VERSION "created by canmatrix"

NS_ :

BS_:

BU_: IPD

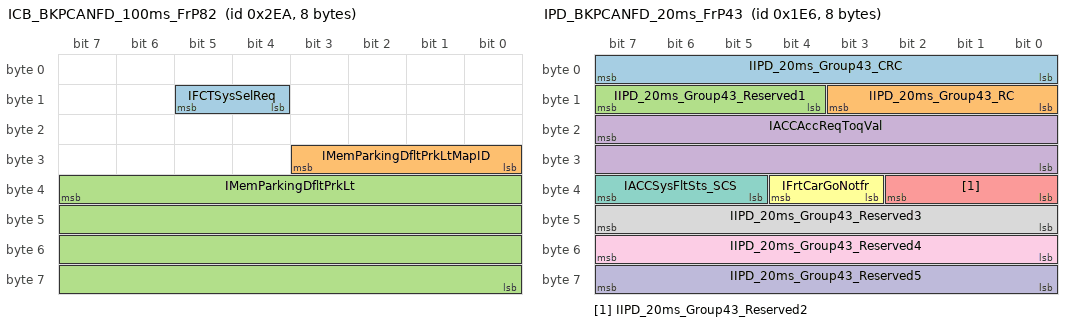
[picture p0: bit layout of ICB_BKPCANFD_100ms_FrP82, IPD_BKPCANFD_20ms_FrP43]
BO_ 746 ICB_BKPCANFD_100ms_FrP82: 8 Vector__XXX
 SG_ IFCTSysSelReq : 13|2@0+ (1,0) [0|3] "null" IPD
 SG_ IMemParkingDfltPrkLtMapID : 27|4@0+ (1,0) [0|15] "null" IPD
 SG_ IMemParkingDfltPrkLt : 39|32@0+ (1,0) [0|4294967295] "null" IPD

BO_ 368 ICB_BKPCANFD_30ms_FrP158: 16 Vector__XXX
 SG_ IICBVC_30ms_Group158_CRC : 7|8@0+ (1,0) [0|255] "null" IPD
 SG_ IICBVC_30ms_Group158_RC : 11|4@0+ (1,0) [0|15] "null" IPD
 SG_ ICCSpdDecAndIncVcCmd : 13|2@0+ (1,0) [0|3] "null" IPD
 SG_ ICCDisDecAndIncVcCmd : 15|2@0+ (1,0) [0|3] "null" IPD
 SG_ IICBVC_30ms_Group158_Reserved1 : 19|4@0+ (1,0) [0|15] "null" IPD
 SG_ ICCSwStsSetSwA : 20|1@0+ (1,0) [0|1] "null" IPD
 SG_ ICCSwStsCCASwA : 21|1@0+ (1,0) [0|1] "null" IPD
 SG_ ICCSpdVcCmdSwReq : 23|2@0+ (1,0) [0|3] "null" IPD
 SG_ ICCSpdVcCmd : 31|8@0+ (1,0) [0|255] "null" IPD
 SG_ IICBVC_30ms_Group158_Reserved2 : 39|8@0+ (1,0) [0|255] "null" IPD
 SG_ IICBVC_30ms_Group158_Reserved3 : 44|5@0+ (1,0) [0|31] "null" IPD
 SG_ ICCDisAdjtVcCmd : 47|3@0+ (1,0) [0|7] "null" IPD
 SG_ IICBVC_30ms_Group158_Reserved4 : 55|8@0+ (1,0) [0|255] "null" IPD
 SG_ IICBVC_30ms_Group158_Reserved5 : 63|8@0+ (1,0) [0|255] "null" IPD
 SG_ IICBVC_30ms_Group158_Reserved6 : 71|8@0+ (1,0) [0|255] "null" IPD
 SG_ IICBVC_30ms_Group158_Reserved7 : 79|8@0+ (1,0) [0|255] "null" IPD
 SG_ IICBVC_30ms_Group158_Reserved8 : 87|8@0+ (1,0) [0|255] "null" IPD
 SG_ IICBVC_30ms_Group158_Reserved9 : 95|8@0+ (1,0) [0|255] "null" IPD
 SG_ IICBVC_30ms_Group158_Reserved10 : 103|8@0+ (1,0) [0|255] "null" IPD
 SG_ IICBVC_30ms_Group158_Reserved11 : 111|8@0+ (1,0) [0|255] "null" IPD
 SG_ IICBVC_30ms_Group158_Reserved12 : 119|8@0+ (1,0) [0|255] "null" IPD
 SG_ IICBVC_30ms_Group158_Reserved13 : 127|8@0+ (1,0) [0|255] "null" IPD

BO_ 1389 ICB_CONNCANFD_Event_FrS67: 16 Vector__XXX
 SG_ IIdentityChlg : 71|64@0+ (1,0) [0|18446744073709551615] "null" IPD

BO_ 1111 ICB_ZONE_BDCAN_100ms_FrP00: 32 Vector__XXX
 SG_ IICCPCBTemp1 : 7|8@0+ (1,-40) [-40|215] "℃" Vector__XXX
 SG_ IICCPCBTemp2 : 15|8@0+ (1,-40) [-40|215] "℃" Vector__XXX
 SG_ IICCPCBTemp3 : 23|8@0+ (1,-40) [-40|215] "℃" Vector__XXX
 SG_ IICCPCBTemp4 : 31|8@0+ (1,-40) [-40|215] "℃" Vector__XXX
 SG_ IICCPCBTemp5 : 39|8@0+ (1,-40) [-40|215] "℃" Vector__XXX
 SG_ IICCThermalCoolingLvl : 47|4@0+ (1,0) [0|15] "null" Vector__XXX
 SG_ IFICMV2XEnEnbReq : 81|2@0+ (1,0) [0|3] "null" Vector__XXX
 SG_ IITMSTripBookReq : 84|3@0+ (1,0) [0|7] "null" Vector__XXX
 SG_ IElecPwrDistbnScene : 95|64@0+ (1,0) [0|18446744073709551615] "null" IPD
 SG_ IAltngChrgCrntReq : 159|8@0+ (1,0) [0|255] "null" Vector__XXX
 SG_ IDschrgTrgtSOCVal : 167|7@0+ (1,0) [0|127] "null" Vector__XXX

BO_ 1767 IPD_BKBCANFD_EvtInfo: 8 IPD
 SG_ IEvtPotclSigIPD : 7|64@0+ (1,0) [0|18446744073709551615] "null" Vector__XXX

BO_ 712 IPD_BKPCANFD_100ms_FrP124: 16 IPD
 SG_ INrwroadFwdBtnDsp : 15|2@0+ (1,0) [0|3] "null" Vector__XXX
 SG_ INrwroadFwdReDst : 23|11@0+ (0.1,0) [0|204.7] "m" Vector__XXX
 SG_ INrwroadFwdDsp : 28|5@0+ (1,0) [0|31] "null" Vector__XXX
 SG_ INrwroadFwdDstL : 39|8@0+ (1,0) [0|255] "cm" Vector__XXX
 SG_ INrwroadFwdDstR : 47|8@0+ (1,0) [0|255] "cm" Vector__XXX
 SG_ INrwroadFwdCndNotSt : 55|5@0+ (1,0) [0|31] "null" Vector__XXX
 SG_ IMemParkingCrsScrnReq : 88|1@0+ (1,0) [0|1] "null" Vector__XXX
 SG_ INrwroadFwdDstTostDsp : 111|4@0+ (1,0) [0|15] "null" Vector__XXX
 SG_ INrwroadFwdSwSts : 113|2@0+ (1,0) [0|3] "null" Vector__XXX
 SG_ INrwroadFwdDst360Req : 116|3@0+ (1,0) [0|7] "null" Vector__XXX
 SG_ INrwroadFwdDstBtnDsp : 119|3@0+ (1,0) [0|7] "null" Vector__XXX

BO_ 710 IPD_BKPCANFD_100ms_FrP127: 64 IPD
 SG_ IMemParkingPrkLt : 7|32@0+ (1,0) [0|4294967295] "null" Vector__XXX
 SG_ IMemParkingPrkLtMapID : 39|4@0+ (1,0) [0|15] "null" Vector__XXX
 SG_ ISpedRegulaModSwSts : 180|3@0+ (1,0) [0|7] "null" Vector__XXX
 SG_ IMemoryRouteSaveCancelRsp : 276|3@0+ (1,0) [0|7] "null" Vector__XXX
 SG_ ILDWAudiAlmReq : 319|3@0+ (1,0) [0|7] "null" Vector__XXX
 SG_ IELKSwStsHid : 321|2@0+ (1,0) [0|3] "null" Vector__XXX
 SG_ IELKIndiDisp : 335|3@0+ (1,0) [0|7] "null" Vector__XXX
 SG_ IMemParkngSwSts : 365|2@0+ (1,0) [0|3] "null" Vector__XXX
 SG_ IRADSSwSts : 373|2@0+ (1,0) [0|3] "null" Vector__XXX

BO_ 706 IPD_BKPCANFD_100ms_FrP128: 64 IPD
 SG_ IPDSysKeyPsAvlbl : 113|2@0+ (1,0) [0|3] "null" Vector__XXX
 SG_ IMemParkingReserveIPD5 : 419|4@0+ (1,0) [0|15] "null" Vector__XXX
 SG_ IMemParkingReserveIPD4 : 423|4@0+ (1,0) [0|15] "null" Vector__XXX
 SG_ IMemParkingReserveIPD2 : 425|2@0+ (1,0) [0|3] "null" Vector__XXX
 SG_ IMemParkingReserveIPD1 : 427|2@0+ (1,0) [0|3] "null" Vector__XXX
 SG_ IMemParkingReserveIPD6 : 431|4@0+ (1,0) [0|15] "null" Vector__XXX
 SG_ IMemParkingReserveIPD3 : 439|2@0+ (1,0) [0|3] "null" Vector__XXX

BO_ 844 IPD_BKPCANFD_100ms_FrP58: 32 IPD
 SG_ IRAAlrWorDis : 23|10@0+ (0.1,0) [0|102.3] "m" Vector__XXX
 SG_ IParkngEndDis : 29|6@0+ (0.1,0) [0|6.3] "m" Vector__XXX
 SG_ IMemParkngSilentPatrolSwSts : 41|2@0+ (1,0) [0|3] "null" Vector__XXX
 SG_ IHODMdlSts : 49|2@0+ (1,0) [0|3] "null" Vector__XXX
 SG_ ITgtParkingFavorite : 59|4@0+ (1,0) [0|15] "null" Vector__XXX
 SG_ IIPDWtrClntInltFlwReq : 63|4@0+ (1,0) [0|15] "null" Vector__XXX
 SG_ IMemParkngBtnRcnmRsp : 71|3@0+ (1,0) [0|7] "null" Vector__XXX
 SG_ IAVPUpdateMapProgress : 79|7@0+ (1,0) [0|127] "%" Vector__XXX
 SG_ IAVPMapDownloadFailReason : 87|4@0+ (1,0) [0|15] "null" Vector__XXX
 SG_ IIPDPowerFailSwSts : 101|2@0+ (1,0) [0|3] "null" Vector__XXX
 SG_ IAVPMapRutMgtSts : 103|2@0+ (1,0) [0|3] "null" Vector__XXX
 SG_ IAVPUpdateMapCancelRsp : 106|1@0+ (1,0) [0|1] "null" Vector__XXX
 SG_ IAVPTagResp : 107|1@0+ (1,0) [0|1] "null" Vector__XXX
 SG_ IAVPTagSts : 108|1@0+ (1,0) [0|1] "null" Vector__XXX
 SG_ ISpdLmtOfstSetNumResp : 115|4@0+ (1,0) [0|15] "null" Vector__XXX
 SG_ ITJAICAMsgReq : 123|5@0+ (1,0) [0|31] "null" Vector__XXX
 SG_ ISpdLmtOfstSetPercResp : 127|3@0+ (1,0) [0|7] "null" Vector__XXX
 SG_ IACCStsSw : 129|2@0+ (1,0) [0|3] "null" Vector__XXX
 SG_ IACCSpdLimtSw : 131|2@0+ (1,0) [0|3] "null" Vector__XXX
 SG_ ISpdLimitManualSts : 137|2@0+ (1,0) [0|3] "null" Vector__XXX
 SG_ ICCSpdlVcCmdSwReqDspCmd : 141|2@0+ (1,0) [0|3] "null" Vector__XXX
 SG_ ISpdLmtMdMsgReq : 147|3@0+ (1,0) [0|7] "null" Vector__XXX

BO_ 755 IPD_BKPCANFD_100ms_FrP61: 24 IPD
 SG_ ILADSInfoDispReqToICM_HPP : 23|8@0+ (1,0) [0|255] "null" Vector__XXX
 SG_ IESSAdoWrnngDspCmd : 25|2@0+ (1,0) [0|3] "null" Vector__XXX
 SG_ IHPPFnSts : 31|6@0+ (1,0) [0|63] "null" Vector__XXX
 SG_ IHPPInBmtSts : 32|1@0+ (1,0) [0|1] "null" Vector__XXX
 SG_ ILADSCurToEndPntDist : 39|7@0+ (0.1,0) [0|12.7] "null" Vector__XXX
 SG_ IESSDspCmd : 41|2@0+ (1,0) [0|3] "null" Vector__XXX
 SG_ INOACitySysMsg : 47|6@0+ (1,0) [0|63] "null" Vector__XXX
 SG_ IFLSUSSSts : 49|2@0+ (1,0) [0|3] "null" Vector__XXX
 SG_ INOPSysMsg : 55|6@0+ (1,0) [0|63] "null" Vector__XXX
 SG_ ILCRInHMI : 58|3@0+ (1,0) [0|7] "null" Vector__XXX
 SG_ INOADistDecMsg : 63|5@0+ (1,0) [0|31] "null" Vector__XXX
 SG_ INarRoVslAssSwResp : 66|3@0+ (1,0) [0|7] "null" Vector__XXX
 SG_ INrwroadBwdAssMesg : 71|5@0+ (1,0) [0|31] "null" Vector__XXX
 SG_ IJAMsgReq : 75|4@0+ (1,0) [0|15] "null" Vector__XXX
 SG_ IDetourMsgReq : 79|4@0+ (1,0) [0|15] "null" Vector__XXX
 SG_ IParkngOutDircnSelResult : 83|4@0+ (1,0) [0|15] "null" Vector__XXX
 SG_ INOAQukChgSwDspCmd : 87|4@0+ (1,0) [0|15] "null" Vector__XXX
 SG_ INrwroadBwdAssSwSts : 90|3@0+ (1,0) [0|7] "null" Vector__XXX
 SG_ IFLUSSSts : 92|2@0+ (1,0) [0|3] "null" Vector__XXX
 SG_ IPEBSts : 95|3@0+ (1,0) [0|7] "null" Vector__XXX
 SG_ IFrtCarGoNotfrDspCmd : 97|2@0+ (1,0) [0|3] "null" Vector__XXX
 SG_ IFRSUSSSts : 99|2@0+ (1,0) [0|3] "null" Vector__XXX
 SG_ IFMRUSSSts : 101|2@0+ (1,0) [0|3] "null" Vector__XXX
 SG_ IFMLUSSSts : 103|2@0+ (1,0) [0|3] "null" Vector__XXX
 SG_ INOALaneSetDspCmd : 105|2@0+ (1,0) [0|3] "null" Vector__XXX
 SG_ INOAETCSetDspCmd : 107|2@0+ (1,0) [0|3] "null" Vector__XXX
 SG_ ILCRSwDspCmd : 109|2@0+ (1,0) [0|3] "null" Vector__XXX
 SG_ IFRUSSSts : 111|2@0+ (1,0) [0|3] "null" Vector__XXX
 SG_ INOPCitySwDspCmd : 113|2@0+ (1,0) [0|3] "null" Vector__XXX
 SG_ INOPSwDspCmd : 116|3@0+ (1,0) [0|7] "null" Vector__XXX
 SG_ INOAReportSetDspCmd : 119|3@0+ (1,0) [0|7] "null" Vector__XXX
 SG_ IRLUSSSts : 121|2@0+ (1,0) [0|3] "null" Vector__XXX
 SG_ IRLSUSSSts : 123|2@0+ (1,0) [0|3] "null" Vector__XXX
 SG_ IPEBWarngReq : 125|2@0+ (1,0) [0|3] "null" Vector__XXX
 SG_ INrwroadBwdAssConfrmSwDscmd : 127|2@0+ (1,0) [0|3] "null" Vector__XXX
 SG_ IRRUSSSts : 129|2@0+ (1,0) [0|3] "null" Vector__XXX
 SG_ IRRSUSSSts : 131|2@0+ (1,0) [0|3] "null" Vector__XXX
 SG_ IRMRUSSSts : 133|2@0+ (1,0) [0|3] "null" Vector__XXX
 SG_ IRMLUSSSts : 135|2@0+ (1,0) [0|3] "null" Vector__XXX
 SG_ IParkngOutFRCrsSts : 136|1@0+ (1,0) [0|1] "null" Vector__XXX
 SG_ IParkngOutFLParllSts : 137|1@0+ (1,0) [0|1] "null" Vector__XXX
 SG_ IParkngOutFLCrsSts : 138|1@0+ (1,0) [0|1] "null" Vector__XXX
 SG_ IParkngOutBkRCrsSts : 139|1@0+ (1,0) [0|1] "null" Vector__XXX
 SG_ IParkngOutBkLCrsSts : 140|1@0+ (1,0) [0|1] "null" Vector__XXX
 SG_ IParkngOutBkCrsSts : 141|1@0+ (1,0) [0|1] "null" Vector__XXX
 SG_ IHPPOnRoutSts : 142|1@0+ (1,0) [0|1] "null" Vector__XXX
 SG_ IHPPMapBuildSts : 143|1@0+ (1,0) [0|1] "null" Vector__XXX
 SG_ IParkngDirAvlSts : 145|2@0+ (1,0) [0|3] "null" Vector__XXX
 SG_ IParkngDirSwResp : 147|2@0+ (1,0) [0|3] "null" Vector__XXX
 SG_ IPEBSwResp : 148|1@0+ (1,0) [0|1] "null" Vector__XXX
 SG_ IParkngSlotFindSts : 149|1@0+ (1,0) [0|1] "null" Vector__XXX
 SG_ IParkngOutFrtCrsSts : 150|1@0+ (1,0) [0|1] "null" Vector__XXX
 SG_ IParkngOutFRParllSts : 151|1@0+ (1,0) [0|1] "null" Vector__XXX

BO_ 486 IPD_BKPCANFD_20ms_FrP43: 8 IPD
 SG_ IIPD_20ms_Group43_CRC : 7|8@0+ (1,0) [0|255] "null" Vector__XXX
 SG_ IIPD_20ms_Group43_RC : 11|4@0+ (1,0) [0|15] "null" Vector__XXX
 SG_ IIPD_20ms_Group43_Reserved1 : 15|4@0+ (1,0) [0|15] "null" Vector__XXX
 SG_ IACCAccReqToqVal : 23|16@0+ (1,0) [0|65535] "Nm" Vector__XXX
 SG_ IIPD_20ms_Group43_Reserved2 : 34|3@0+ (1,0) [0|7] "null" Vector__XXX
 SG_ IFrtCarGoNotfr : 36|2@0+ (1,0) [0|3] "null" Vector__XXX
 SG_ IACCSysFltSts_SCS : 39|3@0+ (1,0) [0|7] "null" Vector__XXX
 SG_ IIPD_20ms_Group43_Reserved3 : 47|8@0+ (1,0) [0|255] "null" Vector__XXX
 SG_ IIPD_20ms_Group43_Reserved4 : 55|8@0+ (1,0) [0|255] "null" Vector__XXX
 SG_ IIPD_20ms_Group43_Reserved5 : 63|8@0+ (1,0) [0|255] "null" Vector__XXX

BO_ 337 IPD_BKPCANFD_20ms_FrP60: 20 IPD
 SG_ IIPD_20ms_Group60_CRC : 7|8@0+ (1,0) [0|255] "null" Vector__XXX
 SG_ IIPD_20ms_Group60_RC : 11|4@0+ (1,0) [0|15] "null" Vector__XXX
 SG_ IAutoLaneChngRLaneSts : 15|4@0+ (1,0) [0|15] "null" Vector__XXX
 SG_ IIPD_20ms_Group60_Reserved1 : 23|8@0+ (1,0) [0|255] "null" Vector__XXX
 SG_ IIPD_20ms_Group60_Reserved2 : 31|8@0+ (1,0) [0|255] "null" Vector__XXX
 SG_ IAPASCSToqReqVal : 39|16@0+ (1,0) [0|65535] "Nm" Vector__XXX
 SG_ IAPAVehCrdnatPosY : 55|10@0+ (1,-512) [-512|511] "cm" Vector__XXX
 SG_ IAPAVehCrdnatAzmth : 56|9@0+ (1,0) [0|511] "degree" Vector__XXX
 SG_ IESSDirInd : 58|2@0+ (1,0) [0|3] "null" Vector__XXX
 SG_ IIPD_20ms_Group60_Reserved3 : 61|3@0+ (1,0) [0|7] "null" Vector__XXX
 SG_ IPilotTkovMsgReq : 75|4@0+ (1,0) [0|15] "null" Vector__XXX
 SG_ INOPSysSts_ZPD : 79|4@0+ (1,0) [0|15] "null" Vector__XXX
 SG_ IPrkgDstCtrlSwResp : 81|2@0+ (1,0) [0|3] "null" Vector__XXX
 SG_ IALCSysSts : 84|3@0+ (1,0) [0|7] "null" Vector__XXX
 SG_ IALCSysFltSts : 87|3@0+ (1,0) [0|7] "null" Vector__XXX
 SG_ IAPAVehCrdnatPosX : 95|12@0+ (1,-2048) [-2048|2047] "cm" Vector__XXX
 SG_ IAutoLaneChngLLaneSts : 99|4@0+ (1,0) [0|15] "null" Vector__XXX
 SG_ IIPD_20ms_Group60_Reserved4 : 105|2@0+ (1,0) [0|3] "null" Vector__XXX
 SG_ IESSSysSts : 108|3@0+ (1,0) [0|7] "null" Vector__XXX
 SG_ IESSSysFltSts : 111|3@0+ (1,0) [0|7] "null" Vector__XXX
 SG_ IIPD_20ms_Group60_Reserved5 : 112|1@0+ (1,0) [0|1] "null" Vector__XXX
 SG_ IESSDrvrTkovReq : 113|1@0+ (1,0) [0|1] "null" Vector__XXX
 SG_ ISLIFSysFltSts : 116|3@0+ (1,0) [0|7] "null" Vector__XXX
 SG_ IParkngslottype : 119|3@0+ (1,0) [0|7] "null" Vector__XXX
 SG_ IIPD_20ms_Group60_Reserved6 : 124|5@0+ (1,0) [0|31] "null" Vector__XXX
 SG_ INOPSysFltSts : 127|3@0+ (1,0) [0|7] "null" Vector__XXX
 SG_ IIPD_20ms_Group60_Reserved7 : 135|8@0+ (1,0) [0|255] "null" Vector__XXX
 SG_ IIPD_20ms_Group60_Reserved8 : 143|8@0+ (1,0) [0|255] "null" Vector__XXX
 SG_ IIPD_20ms_Group60_Reserved9 : 151|8@0+ (1,0) [0|255] "null" Vector__XXX
 SG_ IIPD_20ms_Group60_Reserved10 : 159|8@0+ (1,0) [0|255] "null" Vector__XXX

BO_ 720 IPD_BKPCANFD_50ms_FrP14: 16 IPD
 SG_ IIPD_50ms_Group14_CRC : 7|8@0+ (1,0) [0|255] "null" Vector__XXX
 SG_ IIPD_50ms_Group14_RC : 11|4@0+ (1,0) [0|15] "null" Vector__XXX
 SG_ IIPD_50ms_Group14_Reserved1 : 15|4@0+ (1,0) [0|15] "null" Vector__XXX
 SG_ IIPD_50ms_Group14_Reserved2 : 23|8@0+ (1,0) [0|255] "null" Vector__XXX
 SG_ IIPD_50ms_Group14_Reserved3 : 31|8@0+ (1,0) [0|255] "null" Vector__XXX
 SG_ IIPD_50ms_Group14_Reserved4 : 39|8@0+ (1,0) [0|255] "null" Vector__XXX
 SG_ IIPD_50ms_Group14_Reserved5 : 47|8@0+ (1,0) [0|255] "null" Vector__XXX
 SG_ IIPD_50ms_Group14_Reserved6 : 55|8@0+ (1,0) [0|255] "null" Vector__XXX
 SG_ ILADSInfoDispReq : 63|8@0+ (1,0) [0|255] "null" Vector__XXX
 SG_ ILADSInfoDispReqToICM : 71|8@0+ (1,0) [0|255] "null" Vector__XXX
 SG_ IIPD_50ms_Group14_Reserved7 : 72|1@0+ (1,0) [0|1] "null" Vector__XXX
 SG_ ILADSProgressBar : 79|7@0+ (1,0) [0|127] "percent" Vector__XXX
 SG_ ISDWLSRObsRng : 83|4@0+ (1,0) [0|15] "null" Vector__XXX
 SG_ ISDWLSFObsRng : 87|4@0+ (1,0) [0|15] "null" Vector__XXX
 SG_ ISDWRSRObsRng : 91|4@0+ (1,0) [0|15] "null" Vector__XXX
 SG_ ISDWRSFObsRng : 95|4@0+ (1,0) [0|15] "null" Vector__XXX
 SG_ IIPD_50ms_Group14_Reserved8 : 103|8@0+ (1,0) [0|255] "null" Vector__XXX
 SG_ IIPD_50ms_Group14_Reserved9 : 111|8@0+ (1,0) [0|255] "null" Vector__XXX
 SG_ IIPD_50ms_Group14_Reserved10 : 119|8@0+ (1,0) [0|255] "null" Vector__XXX
 SG_ IIPD_50ms_Group14_Reserved11 : 127|8@0+ (1,0) [0|255] "null" Vector__XXX

BO_ 733 IPD_BKPCANFD_50ms_FrP49: 12 IPD
 SG_ IIPD_50ms_Group49_CRC : 7|8@0+ (1,0) [0|255] "null" Vector__XXX
 SG_ IIPD_50ms_Group49_RC : 11|4@0+ (1,0) [0|15] "null" Vector__XXX
 SG_ IKeepPwrRsnIPD : 15|4@0+ (1,0) [0|15] "null" Vector__XXX
 SG_ IIPD_50ms_Group49_Reserved1 : 20|5@0+ (1,0) [0|31] "null" Vector__XXX
 SG_ ISysPwrMdCtrl : 23|3@0+ (1,0) [0|7] "null" Vector__XXX
 SG_ IIPD_50ms_Group49_Reserved2 : 31|8@0+ (1,0) [0|255] "null" Vector__XXX
 SG_ IIPD_50ms_Group49_Reserved3 : 39|8@0+ (1,0) [0|255] "null" Vector__XXX
 SG_ IIPD_50ms_Group49_Reserved4 : 47|8@0+ (1,0) [0|255] "null" Vector__XXX
 SG_ IIPD_50ms_Group49_Reserved5 : 55|8@0+ (1,0) [0|255] "null" Vector__XXX
 SG_ IIPD_50ms_Group49_Reserved6 : 63|8@0+ (1,0) [0|255] "null" Vector__XXX

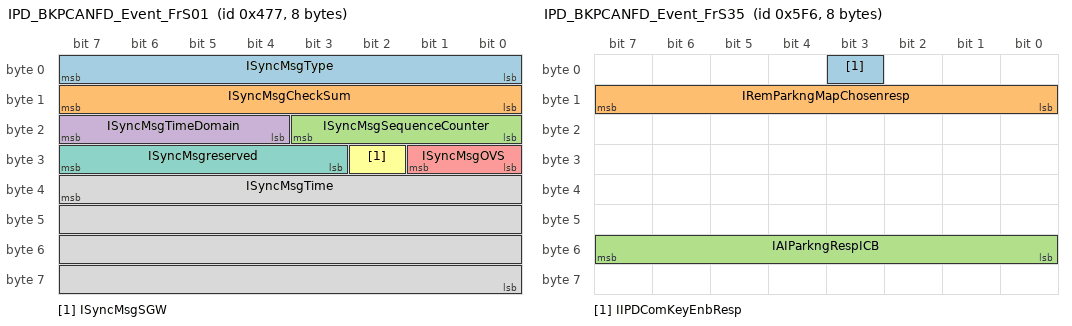
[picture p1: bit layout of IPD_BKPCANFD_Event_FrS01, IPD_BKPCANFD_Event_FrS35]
BO_ 1143 IPD_BKPCANFD_Event_FrS01: 8 IPD
 SG_ ISyncMsgType : 7|8@0+ (1,0) [0|255] "null" Vector__XXX
 SG_ ISyncMsgCheckSum : 15|8@0+ (1,0) [0|255] "null" Vector__XXX
 SG_ ISyncMsgSequenceCounter : 19|4@0+ (1,0) [0|15] "null" Vector__XXX
 SG_ ISyncMsgTimeDomain : 23|4@0+ (1,0) [0|15] "null" Vector__XXX
 SG_ ISyncMsgOVS : 25|2@0+ (1,0) [0|3] "s" Vector__XXX
 SG_ ISyncMsgSGW : 26|1@0+ (1,0) [0|1] "null" Vector__XXX
 SG_ ISyncMsgreserved : 31|5@0+ (1,0) [0|31] "null" Vector__XXX
 SG_ ISyncMsgTime : 39|32@0+ (1,0) [0|4294967295] "null" Vector__XXX

BO_ 1399 IPD_BKPCANFD_Event_FrS13: 20 IPD
 SG_ IIPDIdentityResp : 7|64@0+ (1,0) [0|18446744073709551615] "null" Vector__XXX

BO_ 1526 IPD_BKPCANFD_Event_FrS35: 8 IPD
 SG_ IIPDComKeyEnbResp : 3|1@0+ (1,0) [0|1] "null" Vector__XXX
 SG_ IRemParkngMapChosenresp : 15|8@0+ (1,0) [0|255] "null" Vector__XXX
 SG_ IAIParkngRespICB : 55|8@0+ (1,0) [0|255] "null" Vector__XXX

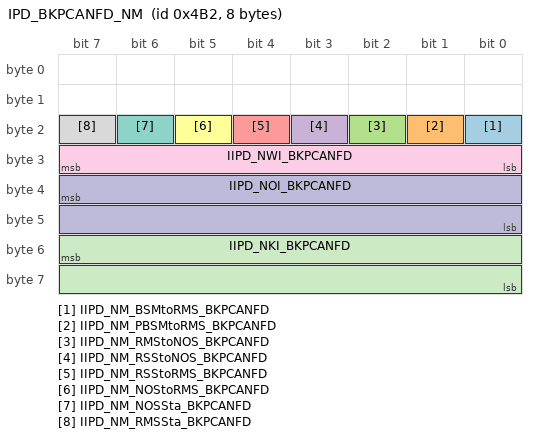
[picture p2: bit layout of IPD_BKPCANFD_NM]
BO_ 1202 IPD_BKPCANFD_NM: 8 IPD
 SG_ IIPD_NM_BSMtoRMS_BKPCANFD : 16|1@0+ (1,0) [0|1] "null" Vector__XXX
 SG_ IIPD_NM_PBSMtoRMS_BKPCANFD : 17|1@0+ (1,0) [0|1] "null" Vector__XXX
 SG_ IIPD_NM_RMStoNOS_BKPCANFD : 18|1@0+ (1,0) [0|1] "null" Vector__XXX
 SG_ IIPD_NM_RSStoNOS_BKPCANFD : 19|1@0+ (1,0) [0|1] "null" Vector__XXX
 SG_ IIPD_NM_RSStoRMS_BKPCANFD : 20|1@0+ (1,0) [0|1] "null" Vector__XXX
 SG_ IIPD_NM_NOStoRMS_BKPCANFD : 21|1@0+ (1,0) [0|1] "null" Vector__XXX
 SG_ IIPD_NM_NOSSta_BKPCANFD : 22|1@0+ (1,0) [0|1] "null" Vector__XXX
 SG_ IIPD_NM_RMSSta_BKPCANFD : 23|1@0+ (1,0) [0|1] "null" Vector__XXX
 SG_ IIPD_NWI_BKPCANFD : 31|8@0+ (1,0) [0|255] "null" Vector__XXX
 SG_ IIPD_NOI_BKPCANFD : 39|16@0+ (1,0) [0|65535] "null" Vector__XXX
 SG_ IIPD_NKI_BKPCANFD : 55|16@0+ (1,0) [0|65535] "null" Vector__XXX

BO_ 705 IPD_CHCANFD_100ms_FrP130: 16 IPD
 SG_ IRASysSts : 19|3@0+ (1,0) [0|7] "null" Vector__XXX
 SG_ IHWPEMStsForEdr : 124|3@0+ (1,0) [0|7] "null" Vector__XXX
 SG_ IHWPEMSts : 127|3@0+ (1,0) [0|7] "null" Vector__XXX

BA_DEF_ BO_ "FrameTriggeringName" STRING;
BA_DEF_ BO_ "GenMsgCycleTime" INT 0 65535;
BA_DEF_ BO_ "GenMsgDelayTime" INT 0 65535;
BA_DEF_ BO_ "GenMsgSendType" ENUM  "cyclicX","spontanX","cyclicIfActiveX","spontanWithDelay","cyclicAndSpontanX","cyclicAndSpontanWithDelay","spontanWithRepitition","cyclicIfActiveAndSpontanWD","cyclicIfActiveFast","cyclicWithRepeatOnDemand","none";
BA_DEF_ BO_ "GenMsgStartValue" STRING;
BA_DEF_ BO_ "PduName" STRING;
BA_DEF_ BO_ "VFrameFormat" ENUM  "StandardCAN","ExtendedCAN","reserved","reserved","reserved","reserved","reserved","reserved","reserved","reserved","reserved","reserved","reserved","reserved","StandardCAN_FD","ExtendedCAN_FD";
BA_DEF_ SG_ "CompuMethodName" STRING;
BA_DEF_ SG_ "GenSigStartValue" FLOAT 0 100000000000;
BA_DEF_ SG_ "ISignalName" STRING;
BA_DEF_ SG_ "LongName" STRING;
BA_DEF_ SG_ "SysSignalName" STRING;
BA_DEF_ SG_ "SystemSignalLongSymbol" STRING;
BA_ "FrameTriggeringName" BO_ 746 "ICB_BKPCANFD_100ms_FrP82";
BA_ "GenMsgCycleTime" BO_ 746 100;
BA_ "GenMsgSendType" BO_ 746 0;
BA_ "GenMsgStartValue" BO_ 746 "0000000000000000";
BA_ "PduName" BO_ 746 "ICB_100ms_PDU82";
BA_ "VFrameFormat" BO_ 746 14;
BA_ "FrameTriggeringName" BO_ 368 "ICB_BKPCANFD_30ms_FrP158";
BA_ "GenMsgCycleTime" BO_ 368 30;
BA_ "GenMsgSendType" BO_ 368 0;
BA_ "GenMsgStartValue" BO_ 368 "00000f00ff1fffffffffffffffffffff";
BA_ "PduName" BO_ 368 "ICBVC_30ms_PDU158";
BA_ "VFrameFormat" BO_ 368 14;
BA_ "FrameTriggeringName" BO_ 1389 "ICB_CONNCANFD_Event_FrS67";
BA_ "GenMsgSendType" BO_ 1389 1;
BA_ "GenMsgStartValue" BO_ 1389 "00000000000000000000000000000000";
BA_ "PduName" BO_ 1389 "ICB_Sporadic_PDU67";
BA_ "VFrameFormat" BO_ 1389 14;
BA_ "FrameTriggeringName" BO_ 1111 "ICB_ZONE_BDCAN_100ms_FrP00";
BA_ "GenMsgCycleTime" BO_ 1111 100;
BA_ "GenMsgSendType" BO_ 1111 0;
BA_ "GenMsgStartValue" BO_ 1111 "ffffffffff100000000000000000000000000020000000000000000000000000";
BA_ "PduName" BO_ 1111 "ICB_ZONE_100ms_PDU00";
BA_ "VFrameFormat" BO_ 1111 14;
BA_ "FrameTriggeringName" BO_ 1767 "IPD_BKBCANFD_EvtInfo";
BA_ "GenMsgSendType" BO_ 1767 1;
BA_ "GenMsgStartValue" BO_ 1767 "0000000000000000";
BA_ "PduName" BO_ 1767 "IPD_BKBCANFD_EvtInfo";
BA_ "VFrameFormat" BO_ 1767 14;
BA_ "FrameTriggeringName" BO_ 712 "IPD_BKPCANFD_100ms_FrP124";
BA_ "GenMsgCycleTime" BO_ 712 100;
BA_ "GenMsgSendType" BO_ 712 0;
BA_ "GenMsgStartValue" BO_ 712 "00c0ffe0ffff00000000000000000100";
BA_ "PduName" BO_ 712 "IPD_100ms_PDU124";
BA_ "VFrameFormat" BO_ 712 14;
BA_ "FrameTriggeringName" BO_ 710 "IPD_BKPCANFD_100ms_FrP127";
BA_ "GenMsgCycleTime" BO_ 710 100;
BA_ "GenMsgSendType" BO_ 710 0;
BA_ "GenMsgStartValue" BO_ 710 "00000000000000000000000000000000000000000000000000000000000000000000000000000000000000000010100000000000000000000000000000000000";
BA_ "PduName" BO_ 710 "IPD_100ms_PDU127";
BA_ "VFrameFormat" BO_ 710 14;
BA_ "FrameTriggeringName" BO_ 706 "IPD_BKPCANFD_100ms_FrP128";
BA_ "GenMsgCycleTime" BO_ 706 100;
BA_ "GenMsgSendType" BO_ 706 0;
BA_ "GenMsgStartValue" BO_ 706 "00000000000000000000000000000100000000000000000000000000000000000000000000000000000000000000000000000000000000000000000000000000";
BA_ "PduName" BO_ 706 "IPD_100ms_PDU128";
BA_ "VFrameFormat" BO_ 706 14;
BA_ "FrameTriggeringName" BO_ 844 "IPD_BKPCANFD_100ms_FrP58";
BA_ "GenMsgCycleTime" BO_ 844 100;
BA_ "GenMsgSendType" BO_ 844 0;
BA_ "GenMsgStartValue" BO_ 844 "0000000000000000000000000000000000000000000000000000000000000000";
BA_ "PduName" BO_ 844 "IPD_100ms_PDU58";
BA_ "VFrameFormat" BO_ 844 14;
BA_ "FrameTriggeringName" BO_ 755 "IPD_BKPCANFD_100ms_FrP61";
BA_ "GenMsgCycleTime" BO_ 755 100;
BA_ "GenMsgSendType" BO_ 755 0;
BA_ "GenMsgStartValue" BO_ 755 "000000020002040000000000000000000000000000000000";
BA_ "PduName" BO_ 755 "IPD_100ms_PDU61";
BA_ "VFrameFormat" BO_ 755 14;
BA_ "FrameTriggeringName" BO_ 486 "IPD_BKPCANFD_20ms_FrP43";
BA_ "GenMsgCycleTime" BO_ 486 20;
BA_ "GenMsgSendType" BO_ 486 0;
BA_ "GenMsgStartValue" BO_ 486 "00f0000007ffffff";
BA_ "PduName" BO_ 486 "IPD_20ms_PDU43";
BA_ "VFrameFormat" BO_ 486 14;
BA_ "FrameTriggeringName" BO_ 337 "IPD_BKPCANFD_20ms_FrP60";
BA_ "GenMsgCycleTime" BO_ 337 20;
BA_ "GenMsgSendType" BO_ 337 0;
BA_ "GenMsgStartValue" BO_ 337 "0000ffff0000003c000001000007011fffffffff";
BA_ "PduName" BO_ 337 "IPD_20ms_PDU60";
BA_ "VFrameFormat" BO_ 337 14;
BA_ "FrameTriggeringName" BO_ 720 "IPD_BKPCANFD_50ms_FrP14";
BA_ "GenMsgCycleTime" BO_ 720 50;
BA_ "GenMsgSendType" BO_ 720 0;
BA_ "GenMsgStartValue" BO_ 720 "00f0ffffffffff0000010000ffffffff";
BA_ "PduName" BO_ 720 "IPD_50ms_PDU14";
BA_ "VFrameFormat" BO_ 720 14;
BA_ "FrameTriggeringName" BO_ 733 "IPD_BKPCANFD_50ms_FrP49";
BA_ "GenMsgCycleTime" BO_ 733 50;
BA_ "GenMsgSendType" BO_ 733 0;
BA_ "GenMsgStartValue" BO_ 733 "00001fffffffffff00000000";
BA_ "PduName" BO_ 733 "IPD_50ms_PDU49";
BA_ "VFrameFormat" BO_ 733 14;
BA_ "FrameTriggeringName" BO_ 1143 "IPD_BKPCANFD_Event_FrS01";
BA_ "GenMsgDelayTime" BO_ 1143 10;
BA_ "GenMsgSendType" BO_ 1143 1;
BA_ "GenMsgStartValue" BO_ 1143 "0000100000000000";
BA_ "PduName" BO_ 1143 "IPD_Sporadic_PDU01";
BA_ "VFrameFormat" BO_ 1143 14;
BA_ "FrameTriggeringName" BO_ 1399 "IPD_BKPCANFD_Event_FrS13";
BA_ "GenMsgSendType" BO_ 1399 1;
BA_ "GenMsgStartValue" BO_ 1399 "0000000000000000000000000000000000000000";
BA_ "PduName" BO_ 1399 "IPD_Sporadic_PDU13";
BA_ "VFrameFormat" BO_ 1399 14;
BA_ "FrameTriggeringName" BO_ 1526 "IPD_BKPCANFD_Event_FrS35";
BA_ "GenMsgDelayTime" BO_ 1526 20;
BA_ "GenMsgSendType" BO_ 1526 1;
BA_ "GenMsgStartValue" BO_ 1526 "0000000000000000";
BA_ "PduName" BO_ 1526 "IPD_Sporadic_PDU35";
BA_ "VFrameFormat" BO_ 1526 14;
BA_ "FrameTriggeringName" BO_ 1202 "IPD_BKPCANFD_NM";
BA_ "GenMsgSendType" BO_ 1202 1;
BA_ "GenMsgStartValue" BO_ 1202 "0000000000000000";
BA_ "PduName" BO_ 1202 "NmPDU_BKPCANFD_IPD";
BA_ "VFrameFormat" BO_ 1202 14;
BA_ "FrameTriggeringName" BO_ 705 "IPD_CHCANFD_100ms_FrP130";
BA_ "GenMsgCycleTime" BO_ 705 100;
BA_ "GenMsgSendType" BO_ 705 0;
BA_ "GenMsgStartValue" BO_ 705 "00000000000000000000000000000000";
BA_ "PduName" BO_ 705 "IPD_100ms_PDU130";
BA_ "VFrameFormat" BO_ 705 14;
BA_ "CompuMethodName" SG_ 746 IFCTSysSelReq "FCTSysSelReq";
BA_ "ISignalName" SG_ 746 IFCTSysSelReq "IFCTSysSelReq";
BA_ "LongName" SG_ 746 IFCTSysSelReq "FCTA/B Switch Select Request";
BA_ "SysSignalName" SG_ 746 IFCTSysSelReq "FCTSysSelReq";
BA_ "CompuMethodName" SG_ 746 IMemParkingDfltPrkLtMapID "MemParkingDfltPrkLtMapID";
BA_ "ISignalName" SG_ 746 IMemParkingDfltPrkLtMapID "IMemParkingDfltPrkLtMapID";
BA_ "LongName" SG_ 746 IMemParkingDfltPrkLtMapID "Memory parking default parking lot map ID";
BA_ "SysSignalName" SG_ 746 IMemParkingDfltPrkLtMapID "MemParkingDfltPrkLtMapID";
BA_ "CompuMethodName" SG_ 746 IMemParkingDfltPrkLt "MemParkingDfltPrkLt";
BA_ "ISignalName" SG_ 746 IMemParkingDfltPrkLt "IMemParkingDfltPrkLt";
BA_ "LongName" SG_ 746 IMemParkingDfltPrkLt "Memory parking default parking lot";
BA_ "SysSignalName" SG_ 746 IMemParkingDfltPrkLt "MemParkingDfltPrkLt";
BA_ "CompuMethodName" SG_ 368 IICBVC_30ms_Group158_CRC "ICBVC_30ms_Group158_CRC";
BA_ "ISignalName" SG_ 368 IICBVC_30ms_Group158_CRC "IICBVC_30ms_Group158_CRC";
BA_ "SysSignalName" SG_ 368 IICBVC_30ms_Group158_CRC "ICBVC_30ms_Group158_CRC";
BA_ "CompuMethodName" SG_ 368 IICBVC_30ms_Group158_RC "ICBVC_30ms_Group158_RC";
BA_ "ISignalName" SG_ 368 IICBVC_30ms_Group158_RC "IICBVC_30ms_Group158_RC";
BA_ "SysSignalName" SG_ 368 IICBVC_30ms_Group158_RC "ICBVC_30ms_Group158_RC";
BA_ "CompuMethodName" SG_ 368 ICCSpdDecAndIncVcCmd "CCSpdDecAndIncVcCmd";
BA_ "ISignalName" SG_ 368 ICCSpdDecAndIncVcCmd "ICCSpdDecAndIncVcCmd";
BA_ "LongName" SG_ 368 ICCSpdDecAndIncVcCmd "Cruise_Control_Speed_Decrease_And_Increase_Voice_Command";
BA_ "SysSignalName" SG_ 368 ICCSpdDecAndIncVcCmd "CCSpdDecAndIncVcCmd";
BA_ "CompuMethodName" SG_ 368 ICCDisDecAndIncVcCmd "CCDisDecAndIncVcCmd";
BA_ "ISignalName" SG_ 368 ICCDisDecAndIncVcCmd "ICCDisDecAndIncVcCmd";
BA_ "LongName" SG_ 368 ICCDisDecAndIncVcCmd "Cruise_Control_Distance_Decrease_And_Increase_Voice_Command";
BA_ "SysSignalName" SG_ 368 ICCDisDecAndIncVcCmd "CCDisDecAndIncVcCmd";
BA_ "CompuMethodName" SG_ 368 IICBVC_30ms_Group158_Reserved1 "ICBVC_30ms_Group158_Reserved1";
BA_ "GenSigStartValue" SG_ 368 IICBVC_30ms_Group158_Reserved1 15;
BA_ "ISignalName" SG_ 368 IICBVC_30ms_Group158_Reserved1 "IICBVC_30ms_Group158_Reserved1";
BA_ "SysSignalName" SG_ 368 IICBVC_30ms_Group158_Reserved1 "ICBVC_30ms_Group158_Reserved1";
BA_ "CompuMethodName" SG_ 368 ICCSwStsSetSwA "CCSwStsSetSwA";
BA_ "ISignalName" SG_ 368 ICCSwStsSetSwA "ICCSwStsSetSwA";
BA_ "LongName" SG_ 368 ICCSwStsSetSwA "Cruise_Control_Switch_Status_Set_Switch_Active";
BA_ "SysSignalName" SG_ 368 ICCSwStsSetSwA "CCSwStsSetSwA";
BA_ "CompuMethodName" SG_ 368 ICCSwStsCCASwA "CCSwStsCCASwA";
BA_ "ISignalName" SG_ 368 ICCSwStsCCASwA "ICCSwStsCCASwA";
BA_ "LongName" SG_ 368 ICCSwStsCCASwA "Cruise_Control_Switch_Status_Cruise_Control_Active_Switch_Active";
BA_ "SysSignalName" SG_ 368 ICCSwStsCCASwA "CCSwStsCCASwA";
BA_ "CompuMethodName" SG_ 368 ICCSpdVcCmdSwReq "CCSpdVcCmdSwReq";
BA_ "ISignalName" SG_ 368 ICCSpdVcCmdSwReq "ICCSpdVcCmdSwReq";
BA_ "LongName" SG_ 368 ICCSpdVcCmdSwReq "Cruise_Control_Speed_Voice_Command_Switch_Request";
BA_ "SysSignalName" SG_ 368 ICCSpdVcCmdSwReq "CCSpdVcCmdSwReq";
BA_ "CompuMethodName" SG_ 368 ICCSpdVcCmd "CCSpdVcCmd";
BA_ "ISignalName" SG_ 368 ICCSpdVcCmd "ICCSpdVcCmd";
BA_ "LongName" SG_ 368 ICCSpdVcCmd "Cruise_Control_Speed_Voice_Command";
BA_ "SysSignalName" SG_ 368 ICCSpdVcCmd "CCSpdVcCmd";
BA_ "CompuMethodName" SG_ 368 IICBVC_30ms_Group158_Reserved2 "ICBVC_30ms_Group158_Reserved2";
BA_ "GenSigStartValue" SG_ 368 IICBVC_30ms_Group158_Reserved2 255;
BA_ "ISignalName" SG_ 368 IICBVC_30ms_Group158_Reserved2 "IICBVC_30ms_Group158_Reserved2";
BA_ "SysSignalName" SG_ 368 IICBVC_30ms_Group158_Reserved2 "ICBVC_30ms_Group158_Reserved2";
BA_ "CompuMethodName" SG_ 368 IICBVC_30ms_Group158_Reserved3 "ICBVC_30ms_Group158_Reserved3";
BA_ "GenSigStartValue" SG_ 368 IICBVC_30ms_Group158_Reserved3 31;
BA_ "ISignalName" SG_ 368 IICBVC_30ms_Group158_Reserved3 "IICBVC_30ms_Group158_Reserved3";
BA_ "SysSignalName" SG_ 368 IICBVC_30ms_Group158_Reserved3 "ICBVC_30ms_Group158_Reserved3";
BA_ "CompuMethodName" SG_ 368 ICCDisAdjtVcCmd "CCDisAdjtVcCmd";
BA_ "ISignalName" SG_ 368 ICCDisAdjtVcCmd "ICCDisAdjtVcCmd";
BA_ "LongName" SG_ 368 ICCDisAdjtVcCmd "Cruise_Control_Distance_Adjust_Voice_Command";
BA_ "SysSignalName" SG_ 368 ICCDisAdjtVcCmd "CCDisAdjtVcCmd";
BA_ "CompuMethodName" SG_ 368 IICBVC_30ms_Group158_Reserved4 "ICBVC_30ms_Group158_Reserved4";
BA_ "GenSigStartValue" SG_ 368 IICBVC_30ms_Group158_Reserved4 255;
BA_ "ISignalName" SG_ 368 IICBVC_30ms_Group158_Reserved4 "IICBVC_30ms_Group158_Reserved4";
BA_ "SysSignalName" SG_ 368 IICBVC_30ms_Group158_Reserved4 "ICBVC_30ms_Group158_Reserved4";
BA_ "CompuMethodName" SG_ 368 IICBVC_30ms_Group158_Reserved5 "ICBVC_30ms_Group158_Reserved5";
BA_ "GenSigStartValue" SG_ 368 IICBVC_30ms_Group158_Reserved5 255;
BA_ "ISignalName" SG_ 368 IICBVC_30ms_Group158_Reserved5 "IICBVC_30ms_Group158_Reserved5";
BA_ "SysSignalName" SG_ 368 IICBVC_30ms_Group158_Reserved5 "ICBVC_30ms_Group158_Reserved5";
BA_ "CompuMethodName" SG_ 368 IICBVC_30ms_Group158_Reserved6 "ICBVC_30ms_Group158_Reserved6";
BA_ "GenSigStartValue" SG_ 368 IICBVC_30ms_Group158_Reserved6 255;
BA_ "ISignalName" SG_ 368 IICBVC_30ms_Group158_Reserved6 "IICBVC_30ms_Group158_Reserved6";
BA_ "SysSignalName" SG_ 368 IICBVC_30ms_Group158_Reserved6 "ICBVC_30ms_Group158_Reserved6";
BA_ "CompuMethodName" SG_ 368 IICBVC_30ms_Group158_Reserved7 "ICBVC_30ms_Group158_Reserved7";
BA_ "GenSigStartValue" SG_ 368 IICBVC_30ms_Group158_Reserved7 255;
BA_ "ISignalName" SG_ 368 IICBVC_30ms_Group158_Reserved7 "IICBVC_30ms_Group158_Reserved7";
BA_ "SysSignalName" SG_ 368 IICBVC_30ms_Group158_Reserved7 "ICBVC_30ms_Group158_Reserved7";
BA_ "CompuMethodName" SG_ 368 IICBVC_30ms_Group158_Reserved8 "ICBVC_30ms_Group158_Reserved8";
BA_ "GenSigStartValue" SG_ 368 IICBVC_30ms_Group158_Reserved8 255;
BA_ "ISignalName" SG_ 368 IICBVC_30ms_Group158_Reserved8 "IICBVC_30ms_Group158_Reserved8";
BA_ "SysSignalName" SG_ 368 IICBVC_30ms_Group158_Reserved8 "ICBVC_30ms_Group158_Reserved8";
BA_ "CompuMethodName" SG_ 368 IICBVC_30ms_Group158_Reserved9 "ICBVC_30ms_Group158_Reserved9";
BA_ "GenSigStartValue" SG_ 368 IICBVC_30ms_Group158_Reserved9 255;
BA_ "ISignalName" SG_ 368 IICBVC_30ms_Group158_Reserved9 "IICBVC_30ms_Group158_Reserved9";
BA_ "SysSignalName" SG_ 368 IICBVC_30ms_Group158_Reserved9 "ICBVC_30ms_Group158_Reserved9";
BA_ "CompuMethodName" SG_ 368 IICBVC_30ms_Group158_Reserved10 "ICBVC_30ms_Group158_Reserved10";
BA_ "GenSigStartValue" SG_ 368 IICBVC_30ms_Group158_Reserved10 255;
BA_ "ISignalName" SG_ 368 IICBVC_30ms_Group158_Reserved10 "IICBVC_30ms_Group158_Reserved10";
BA_ "SysSignalName" SG_ 368 IICBVC_30ms_Group158_Reserved10 "ICBVC_30ms_Group158_Reserved10";
BA_ "CompuMethodName" SG_ 368 IICBVC_30ms_Group158_Reserved11 "ICBVC_30ms_Group158_Reserved11";
BA_ "GenSigStartValue" SG_ 368 IICBVC_30ms_Group158_Reserved11 255;
BA_ "ISignalName" SG_ 368 IICBVC_30ms_Group158_Reserved11 "IICBVC_30ms_Group158_Reserved11";
BA_ "SysSignalName" SG_ 368 IICBVC_30ms_Group158_Reserved11 "ICBVC_30ms_Group158_Reserved11";
BA_ "CompuMethodName" SG_ 368 IICBVC_30ms_Group158_Reserved12 "ICBVC_30ms_Group158_Reserved12";
BA_ "GenSigStartValue" SG_ 368 IICBVC_30ms_Group158_Reserved12 255;
BA_ "ISignalName" SG_ 368 IICBVC_30ms_Group158_Reserved12 "IICBVC_30ms_Group158_Reserved12";
BA_ "SysSignalName" SG_ 368 IICBVC_30ms_Group158_Reserved12 "ICBVC_30ms_Group158_Reserved12";
BA_ "CompuMethodName" SG_ 368 IICBVC_30ms_Group158_Reserved13 "ICBVC_30ms_Group158_Reserved13";
BA_ "GenSigStartValue" SG_ 368 IICBVC_30ms_Group158_Reserved13 255;
BA_ "ISignalName" SG_ 368 IICBVC_30ms_Group158_Reserved13 "IICBVC_30ms_Group158_Reserved13";
BA_ "SysSignalName" SG_ 368 IICBVC_30ms_Group158_Reserved13 "ICBVC_30ms_Group158_Reserved13";
BA_ "CompuMethodName" SG_ 1389 IIdentityChlg "IdentityChlg";
BA_ "ISignalName" SG_ 1389 IIdentityChlg "IIdentityChlg";
BA_ "LongName" SG_ 1389 IIdentityChlg "Identification Challenge";
BA_ "SysSignalName" SG_ 1389 IIdentityChlg "IdentityChlg";
BA_ "CompuMethodName" SG_ 1111 IICCPCBTemp1 "ICCPCBTemp1";
BA_ "GenSigStartValue" SG_ 1111 IICCPCBTemp1 255;
BA_ "ISignalName" SG_ 1111 IICCPCBTemp1 "IICCPCBTemp1";
BA_ "LongName" SG_ 1111 IICCPCBTemp1 "ICC PCB Temperature 1";
BA_ "SysSignalName" SG_ 1111 IICCPCBTemp1 "ICCPCBTemp1";
BA_ "CompuMethodName" SG_ 1111 IICCPCBTemp2 "ICCPCBTemp2";
BA_ "GenSigStartValue" SG_ 1111 IICCPCBTemp2 255;
BA_ "ISignalName" SG_ 1111 IICCPCBTemp2 "IICCPCBTemp2";
BA_ "LongName" SG_ 1111 IICCPCBTemp2 "ICC PCB Temperature 2";
BA_ "SysSignalName" SG_ 1111 IICCPCBTemp2 "ICCPCBTemp2";
BA_ "CompuMethodName" SG_ 1111 IICCPCBTemp3 "ICCPCBTemp3";
BA_ "GenSigStartValue" SG_ 1111 IICCPCBTemp3 255;
BA_ "ISignalName" SG_ 1111 IICCPCBTemp3 "IICCPCBTemp3";
BA_ "LongName" SG_ 1111 IICCPCBTemp3 "ICC PCB Temperature 3";
BA_ "SysSignalName" SG_ 1111 IICCPCBTemp3 "ICCPCBTemp3";
BA_ "CompuMethodName" SG_ 1111 IICCPCBTemp4 "ICCPCBTemp4";
BA_ "GenSigStartValue" SG_ 1111 IICCPCBTemp4 255;
BA_ "ISignalName" SG_ 1111 IICCPCBTemp4 "IICCPCBTemp4";
BA_ "LongName" SG_ 1111 IICCPCBTemp4 "ICC PCB Temperature 4";
BA_ "SysSignalName" SG_ 1111 IICCPCBTemp4 "ICCPCBTemp4";
BA_ "CompuMethodName" SG_ 1111 IICCPCBTemp5 "ICCPCBTemp5";
BA_ "GenSigStartValue" SG_ 1111 IICCPCBTemp5 255;
BA_ "ISignalName" SG_ 1111 IICCPCBTemp5 "IICCPCBTemp5";
BA_ "LongName" SG_ 1111 IICCPCBTemp5 "ICC PCB Temperature 5";
BA_ "SysSignalName" SG_ 1111 IICCPCBTemp5 "ICCPCBTemp5";
BA_ "CompuMethodName" SG_ 1111 IICCThermalCoolingLvl "ICCThermalCoolingLvl";
BA_ "GenSigStartValue" SG_ 1111 IICCThermalCoolingLvl 1;
BA_ "ISignalName" SG_ 1111 IICCThermalCoolingLvl "IICCThermalCoolingLvl";
BA_ "LongName" SG_ 1111 IICCThermalCoolingLvl "ICC Thermal Cooling Level";
BA_ "SysSignalName" SG_ 1111 IICCThermalCoolingLvl "ICCThermalCoolingLvl";
BA_ "CompuMethodName" SG_ 1111 IFICMV2XEnEnbReq "FICMV2XEnEnbReq";
BA_ "ISignalName" SG_ 1111 IFICMV2XEnEnbReq "IFICMV2XEnEnbReq";
BA_ "LongName" SG_ 1111 IFICMV2XEnEnbReq "Front Infotainment Control Module V2x Engine Enable  Request";
BA_ "SysSignalName" SG_ 1111 IFICMV2XEnEnbReq "FICMV2XEnEnbReq";
BA_ "CompuMethodName" SG_ 1111 IITMSTripBookReq "ITMSTripBookReq";
BA_ "ISignalName" SG_ 1111 IITMSTripBookReq "IITMSTripBookReq";
BA_ "LongName" SG_ 1111 IITMSTripBookReq "Trip Book Request";
BA_ "SysSignalName" SG_ 1111 IITMSTripBookReq "ITMSTripBookReq";
BA_ "CompuMethodName" SG_ 1111 IElecPwrDistbnScene "ElecPwrDistbnScene";
BA_ "ISignalName" SG_ 1111 IElecPwrDistbnScene "IElecPwrDistbnScene";
BA_ "LongName" SG_ 1111 IElecPwrDistbnScene "ElectricPowerDistributionScene";
BA_ "SysSignalName" SG_ 1111 IElecPwrDistbnScene "ElecPwrDistbnScene";
BA_ "CompuMethodName" SG_ 1111 IAltngChrgCrntReq "AltngChrgCrntReq";
BA_ "GenSigStartValue" SG_ 1111 IAltngChrgCrntReq 32;
BA_ "ISignalName" SG_ 1111 IAltngChrgCrntReq "IAltngChrgCrntReq";
BA_ "LongName" SG_ 1111 IAltngChrgCrntReq "Alternating Charge Current Request";
BA_ "SysSignalName" SG_ 1111 IAltngChrgCrntReq "AltngChrgCrntReq";
BA_ "CompuMethodName" SG_ 1111 IDschrgTrgtSOCVal "DschrgTrgtSOCVal";
BA_ "ISignalName" SG_ 1111 IDschrgTrgtSOCVal "IDschrgTrgtSOCVal";
BA_ "LongName" SG_ 1111 IDschrgTrgtSOCVal "DisCharge Target State Of Charge Value";
BA_ "SysSignalName" SG_ 1111 IDschrgTrgtSOCVal "DschrgTrgtSOCVal";
BA_ "CompuMethodName" SG_ 1767 IEvtPotclSigIPD "EvtPotclSigIPD";
BA_ "ISignalName" SG_ 1767 IEvtPotclSigIPD "IEvtPotclSigIPD";
BA_ "LongName" SG_ 1767 IEvtPotclSigIPD "Event_Protocol_Signal_IPD";
BA_ "SysSignalName" SG_ 1767 IEvtPotclSigIPD "EvtPotclSigIPD";
BA_ "CompuMethodName" SG_ 712 INrwroadFwdBtnDsp "NrwroadFwdBtnDsp";
BA_ "GenSigStartValue" SG_ 712 INrwroadFwdBtnDsp 3;
BA_ "ISignalName" SG_ 712 INrwroadFwdBtnDsp "INrwroadFwdBtnDsp";
BA_ "LongName" SG_ 712 INrwroadFwdBtnDsp "Narrow road forward button display";
BA_ "SysSignalName" SG_ 712 INrwroadFwdBtnDsp "NrwroadFwdBtnDsp";
BA_ "CompuMethodName" SG_ 712 INrwroadFwdReDst "NrwroadFwdReDst";
BA_ "GenSigStartValue" SG_ 712 INrwroadFwdReDst 2047;
BA_ "ISignalName" SG_ 712 INrwroadFwdReDst "INrwroadFwdReDst";
BA_ "LongName" SG_ 712 INrwroadFwdReDst "Narrow road forward remaining distance";
BA_ "SysSignalName" SG_ 712 INrwroadFwdReDst "NrwroadFwdReDst";
BA_ "CompuMethodName" SG_ 712 INrwroadFwdDsp "NrwroadFwdDsp";
BA_ "ISignalName" SG_ 712 INrwroadFwdDsp "INrwroadFwdDsp";
BA_ "LongName" SG_ 712 INrwroadFwdDsp "Narrow road forward display";
BA_ "SysSignalName" SG_ 712 INrwroadFwdDsp "NrwroadFwdDsp";
BA_ "CompuMethodName" SG_ 712 INrwroadFwdDstL "NrwroadFwdDstL";
BA_ "GenSigStartValue" SG_ 712 INrwroadFwdDstL 255;
BA_ "ISignalName" SG_ 712 INrwroadFwdDstL "INrwroadFwdDstL";
BA_ "LongName" SG_ 712 INrwroadFwdDstL "Narrow road forward distance left";
BA_ "SysSignalName" SG_ 712 INrwroadFwdDstL "NrwroadFwdDstL";
BA_ "CompuMethodName" SG_ 712 INrwroadFwdDstR "NrwroadFwdDstR";
BA_ "GenSigStartValue" SG_ 712 INrwroadFwdDstR 255;
BA_ "ISignalName" SG_ 712 INrwroadFwdDstR "INrwroadFwdDstR";
BA_ "LongName" SG_ 712 INrwroadFwdDstR "Narrow road forward distance right";
BA_ "SysSignalName" SG_ 712 INrwroadFwdDstR "NrwroadFwdDstR";
BA_ "CompuMethodName" SG_ 712 INrwroadFwdCndNotSt "NrwroadFwdCndNotSt";
BA_ "ISignalName" SG_ 712 INrwroadFwdCndNotSt "INrwroadFwdCndNotSt";
BA_ "LongName" SG_ 712 INrwroadFwdCndNotSt "Narrow road forward not satisfied";
BA_ "SysSignalName" SG_ 712 INrwroadFwdCndNotSt "NrwroadFwdCndNotSt";
BA_ "CompuMethodName" SG_ 712 IMemParkingCrsScrnReq "MemParkingCrsScrnReq";
BA_ "ISignalName" SG_ 712 IMemParkingCrsScrnReq "IMemParkingCrsScrnReq";
BA_ "LongName" SG_ 712 IMemParkingCrsScrnReq "Memory parking curise screen display request";
BA_ "SysSignalName" SG_ 712 IMemParkingCrsScrnReq "MemParkingCrsScrnReq";
BA_ "CompuMethodName" SG_ 712 INrwroadFwdDstTostDsp "NrwroadFwdDstTostDsp";
BA_ "ISignalName" SG_ 712 INrwroadFwdDstTostDsp "INrwroadFwdDstTostDsp";
BA_ "LongName" SG_ 712 INrwroadFwdDstTostDsp "Narrow road forward distance Toast display";
BA_ "SysSignalName" SG_ 712 INrwroadFwdDstTostDsp "NrwroadFwdDstTostDsp";
BA_ "CompuMethodName" SG_ 712 INrwroadFwdSwSts "NrwroadFwdSwSts";
BA_ "GenSigStartValue" SG_ 712 INrwroadFwdSwSts 1;
BA_ "ISignalName" SG_ 712 INrwroadFwdSwSts "INrwroadFwdSwSts";
BA_ "LongName" SG_ 712 INrwroadFwdSwSts "Narrow road forward Switch Status";
BA_ "SysSignalName" SG_ 712 INrwroadFwdSwSts "NrwroadFwdSwSts";
BA_ "CompuMethodName" SG_ 712 INrwroadFwdDst360Req "NrwroadFwdDst360Req";
BA_ "ISignalName" SG_ 712 INrwroadFwdDst360Req "INrwroadFwdDst360Req";
BA_ "LongName" SG_ 712 INrwroadFwdDst360Req "Narrow road forward distance 360 Requst";
BA_ "SysSignalName" SG_ 712 INrwroadFwdDst360Req "NrwroadFwdDst360Req";
BA_ "CompuMethodName" SG_ 712 INrwroadFwdDstBtnDsp "NrwroadFwdDstBtnDsp";
BA_ "ISignalName" SG_ 712 INrwroadFwdDstBtnDsp "INrwroadFwdDstBtnDsp";
BA_ "LongName" SG_ 712 INrwroadFwdDstBtnDsp "Narrow road forward distance button display";
BA_ "SysSignalName" SG_ 712 INrwroadFwdDstBtnDsp "NrwroadFwdDstBtnDsp";
BA_ "CompuMethodName" SG_ 710 IMemParkingPrkLt "MemParkingPrkLt";
BA_ "ISignalName" SG_ 710 IMemParkingPrkLt "IMemParkingPrkLt";
BA_ "LongName" SG_ 710 IMemParkingPrkLt "Memory parking parking lot";
BA_ "SysSignalName" SG_ 710 IMemParkingPrkLt "MemParkingPrkLt";
BA_ "CompuMethodName" SG_ 710 IMemParkingPrkLtMapID "MemParkingPrkLtMapID";
BA_ "ISignalName" SG_ 710 IMemParkingPrkLtMapID "IMemParkingPrkLtMapID";
BA_ "LongName" SG_ 710 IMemParkingPrkLtMapID "Memory parking parking lot map ID";
BA_ "SysSignalName" SG_ 710 IMemParkingPrkLtMapID "MemParkingPrkLtMapID";
BA_ "CompuMethodName" SG_ 710 ISpedRegulaModSwSts "SpedRegulaModSwSts";
BA_ "ISignalName" SG_ 710 ISpedRegulaModSwSts "ISpedRegulaModSwSts";
BA_ "LongName" SG_ 710 ISpedRegulaModSwSts "Speed Regulation Mode Switch status";
BA_ "SysSignalName" SG_ 710 ISpedRegulaModSwSts "SpedRegulaModSwSts";
BA_ "CompuMethodName" SG_ 710 IMemoryRouteSaveCancelRsp "MemoryRouteSaveCancelRsp";
BA_ "ISignalName" SG_ 710 IMemoryRouteSaveCancelRsp "IMemoryRouteSaveCancelRsp";
BA_ "LongName" SG_ 710 IMemoryRouteSaveCancelRsp "Memory Route Save Cancel Respond";
BA_ "SysSignalName" SG_ 710 IMemoryRouteSaveCancelRsp "MemoryRouteSaveCancelRsp";
BA_ "CompuMethodName" SG_ 710 ILDWAudiAlmReq "LDWAudiAlmReq";
BA_ "ISignalName" SG_ 710 ILDWAudiAlmReq "ILDWAudiAlmReq";
BA_ "LongName" SG_ 710 ILDWAudiAlmReq "LDW Audible Alarm Request";
BA_ "SysSignalName" SG_ 710 ILDWAudiAlmReq "LDWAudiAlmReq";
BA_ "CompuMethodName" SG_ 710 IELKSwStsHid "ELKSwStsHid";
BA_ "ISignalName" SG_ 710 IELKSwStsHid "IELKSwStsHid";
BA_ "LongName" SG_ 710 IELKSwStsHid "ELK Switch status hide";
BA_ "SysSignalName" SG_ 710 IELKSwStsHid "ELKSwStsHid";
BA_ "CompuMethodName" SG_ 710 IELKIndiDisp "ELKIndiDisp";
BA_ "ISignalName" SG_ 710 IELKIndiDisp "IELKIndiDisp";
BA_ "LongName" SG_ 710 IELKIndiDisp "ELK Indicator Display";
BA_ "SysSignalName" SG_ 710 IELKIndiDisp "ELKIndiDisp";
BA_ "CompuMethodName" SG_ 710 IMemParkngSwSts "MemParkngSwSts";
BA_ "GenSigStartValue" SG_ 710 IMemParkngSwSts 1;
BA_ "ISignalName" SG_ 710 IMemParkngSwSts "IMemParkngSwSts";
BA_ "LongName" SG_ 710 IMemParkngSwSts "Memory Parking Switch Status";
BA_ "SysSignalName" SG_ 710 IMemParkngSwSts "MemParkngSwSts";
BA_ "CompuMethodName" SG_ 710 IRADSSwSts "RADSSwSts";
BA_ "GenSigStartValue" SG_ 710 IRADSSwSts 1;
BA_ "ISignalName" SG_ 710 IRADSSwSts "IRADSSwSts";
BA_ "LongName" SG_ 710 IRADSSwSts "Remenber Autonomous Driving System Switch Status";
BA_ "SysSignalName" SG_ 710 IRADSSwSts "RADSSwSts";
BA_ "CompuMethodName" SG_ 706 IPDSysKeyPsAvlbl "PDSysKeyPsAvlbl";
BA_ "GenSigStartValue" SG_ 706 IPDSysKeyPsAvlbl 1;
BA_ "ISignalName" SG_ 706 IPDSysKeyPsAvlbl "IPDSysKeyPsAvlbl";
BA_ "LongName" SG_ 706 IPDSysKeyPsAvlbl "Key valid";
BA_ "SysSignalName" SG_ 706 IPDSysKeyPsAvlbl "PDSysKeyPsAvlbl";
BA_ "CompuMethodName" SG_ 706 IMemParkingReserveIPD5 "MemParkingReserveIPD5";
BA_ "ISignalName" SG_ 706 IMemParkingReserveIPD5 "IMemParkingReserveIPD5";
BA_ "LongName" SG_ 706 IMemParkingReserveIPD5 "memory parking reserved IPD 05";
BA_ "SysSignalName" SG_ 706 IMemParkingReserveIPD5 "MemParkingReserveIPD5";
BA_ "CompuMethodName" SG_ 706 IMemParkingReserveIPD4 "MemParkingReserveIPD4";
BA_ "ISignalName" SG_ 706 IMemParkingReserveIPD4 "IMemParkingReserveIPD4";
BA_ "LongName" SG_ 706 IMemParkingReserveIPD4 "memory parking reserved IPD 04";
BA_ "SysSignalName" SG_ 706 IMemParkingReserveIPD4 "MemParkingReserveIPD4";
BA_ "CompuMethodName" SG_ 706 IMemParkingReserveIPD2 "MemParkingReserveIPD2";
BA_ "ISignalName" SG_ 706 IMemParkingReserveIPD2 "IMemParkingReserveIPD2";
BA_ "LongName" SG_ 706 IMemParkingReserveIPD2 "memory parking reserved IPD 02";
BA_ "SysSignalName" SG_ 706 IMemParkingReserveIPD2 "MemParkingReserveIPD2";
BA_ "CompuMethodName" SG_ 706 IMemParkingReserveIPD1 "MemParkingReserveIPD1";
BA_ "ISignalName" SG_ 706 IMemParkingReserveIPD1 "IMemParkingReserveIPD1";
BA_ "LongName" SG_ 706 IMemParkingReserveIPD1 "memory parking reserved IPD 01";
BA_ "SysSignalName" SG_ 706 IMemParkingReserveIPD1 "MemParkingReserveIPD1";
BA_ "CompuMethodName" SG_ 706 IMemParkingReserveIPD6 "MemParkingReserveIPD6";
BA_ "ISignalName" SG_ 706 IMemParkingReserveIPD6 "IMemParkingReserveIPD6";
BA_ "LongName" SG_ 706 IMemParkingReserveIPD6 "memory parking reserved IPD 06";
BA_ "SysSignalName" SG_ 706 IMemParkingReserveIPD6 "MemParkingReserveIPD6";
BA_ "CompuMethodName" SG_ 706 IMemParkingReserveIPD3 "MemParkingReserveIPD3";
BA_ "ISignalName" SG_ 706 IMemParkingReserveIPD3 "IMemParkingReserveIPD3";
BA_ "LongName" SG_ 706 IMemParkingReserveIPD3 "memory parking reserved IPD 03";
BA_ "SysSignalName" SG_ 706 IMemParkingReserveIPD3 "MemParkingReserveIPD3";
BA_ "CompuMethodName" SG_ 844 IRAAlrWorDis "RAAlrWorDis";
BA_ "ISignalName" SG_ 844 IRAAlrWorDis "IRAAlrWorDis";
BA_ "LongName" SG_ 844 IRAAlrWorDis "Reverse Assist Already Working Distance";
BA_ "SysSignalName" SG_ 844 IRAAlrWorDis "RAAlrWorDis";
BA_ "CompuMethodName" SG_ 844 IParkngEndDis "ParkngEndDis";
BA_ "ISignalName" SG_ 844 IParkngEndDis "IParkngEndDis";
BA_ "LongName" SG_ 844 IParkngEndDis "Parking to End Distance";
BA_ "SysSignalName" SG_ 844 IParkngEndDis "ParkngEndDis";
BA_ "CompuMethodName" SG_ 844 IMemParkngSilentPatrolSwSts "MemParkngSilentPatrolSwSts";
BA_ "ISignalName" SG_ 844 IMemParkngSilentPatrolSwSts "IMemParkngSilentPatrolSwSts";
BA_ "LongName" SG_ 844 IMemParkngSilentPatrolSwSts "Mem Parkng Silent Patrol Sts";
BA_ "SysSignalName" SG_ 844 IMemParkngSilentPatrolSwSts "MemParkngSilentPatrolSwSts";
BA_ "CompuMethodName" SG_ 844 IHODMdlSts "HODMdlSts";
BA_ "ISignalName" SG_ 844 IHODMdlSts "IHODMdlSts";
BA_ "LongName" SG_ 844 IHODMdlSts "HOD Model Status";
BA_ "SysSignalName" SG_ 844 IHODMdlSts "HODMdlSts";
BA_ "CompuMethodName" SG_ 844 ITgtParkingFavorite "TgtParkingFavorite";
BA_ "ISignalName" SG_ 844 ITgtParkingFavorite "ITgtParkingFavorite";
BA_ "LongName" SG_ 844 ITgtParkingFavorite "Target Parking Favorite";
BA_ "SysSignalName" SG_ 844 ITgtParkingFavorite "TgtParkingFavorite";
BA_ "CompuMethodName" SG_ 844 IIPDWtrClntInltFlwReq "IPDWtrClntInltFlwReq";
BA_ "ISignalName" SG_ 844 IIPDWtrClntInltFlwReq "IIPDWtrClntInltFlwReq";
BA_ "LongName" SG_ 844 IIPDWtrClntInltFlwReq "IPD_water_coolant_inlet_flow_request";
BA_ "SysSignalName" SG_ 844 IIPDWtrClntInltFlwReq "IPDWtrClntInltFlwReq";
BA_ "CompuMethodName" SG_ 844 IMemParkngBtnRcnmRsp "MemParkngBtnRcnmRsp";
BA_ "ISignalName" SG_ 844 IMemParkngBtnRcnmRsp "IMemParkngBtnRcnmRsp";
BA_ "LongName" SG_ 844 IMemParkngBtnRcnmRsp "Memory Parkng Button Recommand Response";
BA_ "SysSignalName" SG_ 844 IMemParkngBtnRcnmRsp "MemParkngBtnRcnmRsp";
BA_ "CompuMethodName" SG_ 844 IAVPUpdateMapProgress "AVPUpdateMapProgress";
BA_ "ISignalName" SG_ 844 IAVPUpdateMapProgress "IAVPUpdateMapProgress";
BA_ "LongName" SG_ 844 IAVPUpdateMapProgress "AVP Update Map Progress";
BA_ "SysSignalName" SG_ 844 IAVPUpdateMapProgress "AVPUpdateMapProgress";
BA_ "CompuMethodName" SG_ 844 IAVPMapDownloadFailReason "AVPMapDownloadFailReason";
BA_ "ISignalName" SG_ 844 IAVPMapDownloadFailReason "IAVPMapDownloadFailReason";
BA_ "LongName" SG_ 844 IAVPMapDownloadFailReason "AVP Map Download Fail Reason";
BA_ "SysSignalName" SG_ 844 IAVPMapDownloadFailReason "AVPMapDownloadFailReason";
BA_ "CompuMethodName" SG_ 844 IIPDPowerFailSwSts "IPDPowerFailSwSts";
BA_ "ISignalName" SG_ 844 IIPDPowerFailSwSts "IIPDPowerFailSwSts";
BA_ "LongName" SG_ 844 IIPDPowerFailSwSts "IPD_Power_Faile_Switch_Status";
BA_ "SysSignalName" SG_ 844 IIPDPowerFailSwSts "IPDPowerFailSwSts";
BA_ "CompuMethodName" SG_ 844 IAVPMapRutMgtSts "AVPMapRutMgtSts";
BA_ "ISignalName" SG_ 844 IAVPMapRutMgtSts "IAVPMapRutMgtSts";
BA_ "LongName" SG_ 844 IAVPMapRutMgtSts "AVP Map Route Management Status";
BA_ "SysSignalName" SG_ 844 IAVPMapRutMgtSts "AVPMapRutMgtSts";
BA_ "CompuMethodName" SG_ 844 IAVPUpdateMapCancelRsp "AVPUpdateMapCancelRsp";
BA_ "ISignalName" SG_ 844 IAVPUpdateMapCancelRsp "IAVPUpdateMapCancelRsp";
BA_ "LongName" SG_ 844 IAVPUpdateMapCancelRsp "AVP Update Map Cancel Response";
BA_ "SysSignalName" SG_ 844 IAVPUpdateMapCancelRsp "AVPUpdateMapCancelRsp";
BA_ "CompuMethodName" SG_ 844 IAVPTagResp "AVPTagResp";
BA_ "ISignalName" SG_ 844 IAVPTagResp "IAVPTagResp";
BA_ "LongName" SG_ 844 IAVPTagResp "AVP Tag Response";
BA_ "SysSignalName" SG_ 844 IAVPTagResp "AVPTagResp";
BA_ "CompuMethodName" SG_ 844 IAVPTagSts "AVPTagSts";
BA_ "ISignalName" SG_ 844 IAVPTagSts "IAVPTagSts";
BA_ "LongName" SG_ 844 IAVPTagSts "AVP Tag Status";
BA_ "SysSignalName" SG_ 844 IAVPTagSts "AVPTagSts";
BA_ "CompuMethodName" SG_ 844 ISpdLmtOfstSetNumResp "SpdLmtOfstSetNumResp";
BA_ "ISignalName" SG_ 844 ISpdLmtOfstSetNumResp "ISpdLmtOfstSetNumResp";
BA_ "LongName" SG_ 844 ISpdLmtOfstSetNumResp "Speed Limit Offset Set Number_Response";
BA_ "SysSignalName" SG_ 844 ISpdLmtOfstSetNumResp "SpdLmtOfstSetNumResp";
BA_ "CompuMethodName" SG_ 844 ITJAICAMsgReq "TJAICAMsgReq";
BA_ "ISignalName" SG_ 844 ITJAICAMsgReq "ITJAICAMsgReq";
BA_ "LongName" SG_ 844 ITJAICAMsgReq "Traffic_Jam_Assist_Integrated_Cruise_Assist_Message_Request";
BA_ "SysSignalName" SG_ 844 ITJAICAMsgReq "TJAICAMsgReq";
BA_ "CompuMethodName" SG_ 844 ISpdLmtOfstSetPercResp "SpdLmtOfstSetPercResp";
BA_ "ISignalName" SG_ 844 ISpdLmtOfstSetPercResp "ISpdLmtOfstSetPercResp";
BA_ "LongName" SG_ 844 ISpdLmtOfstSetPercResp "Speed Limit Offset Set Percent_Response";
BA_ "SysSignalName" SG_ 844 ISpdLmtOfstSetPercResp "SpdLmtOfstSetPercResp";
BA_ "CompuMethodName" SG_ 844 IACCStsSw "ACCStsSw";
BA_ "ISignalName" SG_ 844 IACCStsSw "IACCStsSw";
BA_ "LongName" SG_ 844 IACCStsSw "ACC status switch";
BA_ "SysSignalName" SG_ 844 IACCStsSw "ACCStsSw";
BA_ "CompuMethodName" SG_ 844 IACCSpdLimtSw "ACCSpdLimtSw";
BA_ "ISignalName" SG_ 844 IACCSpdLimtSw "IACCSpdLimtSw";
BA_ "LongName" SG_ 844 IACCSpdLimtSw "ACC speed limit swtich";
BA_ "SysSignalName" SG_ 844 IACCSpdLimtSw "ACCSpdLimtSw";
BA_ "CompuMethodName" SG_ 844 ISpdLimitManualSts "SpdLimitManualSts";
BA_ "ISignalName" SG_ 844 ISpdLimitManualSts "ISpdLimitManualSts";
BA_ "LongName" SG_ 844 ISpdLimitManualSts "Speed limit manual status";
BA_ "SysSignalName" SG_ 844 ISpdLimitManualSts "SpdLimitManualSts";
BA_ "CompuMethodName" SG_ 844 ICCSpdlVcCmdSwReqDspCmd "CCSpdlVcCmdSwReqDspCmd";
BA_ "ISignalName" SG_ 844 ICCSpdlVcCmdSwReqDspCmd "ICCSpdlVcCmdSwReqDspCmd";
BA_ "LongName" SG_ 844 ICCSpdlVcCmdSwReqDspCmd "Cruise_Control_Speed_Voice_Command_Switch_Request_Display_Command";
BA_ "SysSignalName" SG_ 844 ICCSpdlVcCmdSwReqDspCmd "CCSpdlVcCmdSwReqDspCmd";
BA_ "CompuMethodName" SG_ 844 ISpdLmtMdMsgReq "SpdLmtMdMsgReq";
BA_ "ISignalName" SG_ 844 ISpdLmtMdMsgReq "ISpdLmtMdMsgReq";
BA_ "LongName" SG_ 844 ISpdLmtMdMsgReq "Speed_Limit_Mode_Message_Request";
BA_ "SysSignalName" SG_ 844 ISpdLmtMdMsgReq "SpdLmtMdMsgReq";
BA_ "CompuMethodName" SG_ 755 ILADSInfoDispReqToICM_HPP "LADSInfoDispReqToICM_HPP";
BA_ "ISignalName" SG_ 755 ILADSInfoDispReqToICM_HPP "ILADSInfoDispReqToICM_HPP";
BA_ "LongName" SG_ 755 ILADSInfoDispReqToICM_HPP "Advance_Park_Assist_Information_Display_Request_HPP";
BA_ "SysSignalName" SG_ 755 ILADSInfoDispReqToICM_HPP "LADSInfoDispReqToICM_HPP";
BA_ "CompuMethodName" SG_ 755 IESSAdoWrnngDspCmd "ESSAdoWrnngDspCmd";
BA_ "GenSigStartValue" SG_ 755 IESSAdoWrnngDspCmd 2;
BA_ "ISignalName" SG_ 755 IESSAdoWrnngDspCmd "IESSAdoWrnngDspCmd";
BA_ "LongName" SG_ 755 IESSAdoWrnngDspCmd "Emergency_Steering_System Audio Warning Display Command";
BA_ "SysSignalName" SG_ 755 IESSAdoWrnngDspCmd "ESSAdoWrnngDspCmd";
BA_ "CompuMethodName" SG_ 755 IHPPFnSts "HPPFnSts";
BA_ "ISignalName" SG_ 755 IHPPFnSts "IHPPFnSts";
BA_ "LongName" SG_ 755 IHPPFnSts "HPP_Function_Status";
BA_ "SysSignalName" SG_ 755 IHPPFnSts "HPPFnSts";
BA_ "CompuMethodName" SG_ 755 IHPPInBmtSts "HPPInBmtSts";
BA_ "ISignalName" SG_ 755 IHPPInBmtSts "IHPPInBmtSts";
BA_ "LongName" SG_ 755 IHPPInBmtSts "HPP_In_Basement_Status";
BA_ "SysSignalName" SG_ 755 IHPPInBmtSts "HPPInBmtSts";
BA_ "CompuMethodName" SG_ 755 ILADSCurToEndPntDist "LADSCurToEndPntDist";
BA_ "ISignalName" SG_ 755 ILADSCurToEndPntDist "ILADSCurToEndPntDist";
BA_ "LongName" SG_ 755 ILADSCurToEndPntDist "Low Speed Automated Driving System Current To End Point Distance";
BA_ "SysSignalName" SG_ 755 ILADSCurToEndPntDist "LADSCurToEndPntDist";
BA_ "CompuMethodName" SG_ 755 IESSDspCmd "ESSDspCmd";
BA_ "GenSigStartValue" SG_ 755 IESSDspCmd 2;
BA_ "ISignalName" SG_ 755 IESSDspCmd "IESSDspCmd";
BA_ "LongName" SG_ 755 IESSDspCmd "Emergency_Steering_Display_Command";
BA_ "SysSignalName" SG_ 755 IESSDspCmd "ESSDspCmd";
BA_ "CompuMethodName" SG_ 755 INOACitySysMsg "NOACitySysMsg";
BA_ "ISignalName" SG_ 755 INOACitySysMsg "INOACitySysMsg";
BA_ "LongName" SG_ 755 INOACitySysMsg "Navigation  On AutoPilot City System
  Message";
BA_ "SysSignalName" SG_ 755 INOACitySysMsg "NOACitySysMsg";
BA_ "CompuMethodName" SG_ 755 IFLSUSSSts "FLSUSSSts";
BA_ "ISignalName" SG_ 755 IFLSUSSSts "IFLSUSSSts";
BA_ "LongName" SG_ 755 IFLSUSSSts "Front Left Side USS Status";
BA_ "SysSignalName" SG_ 755 IFLSUSSSts "FLSUSSSts";
BA_ "CompuMethodName" SG_ 755 INOPSysMsg "NOPSysMsg";
BA_ "GenSigStartValue" SG_ 755 INOPSysMsg 1;
BA_ "ISignalName" SG_ 755 INOPSysMsg "INOPSysMsg";
BA_ "LongName" SG_ 755 INOPSysMsg "Navigation On Pilot System Message";
BA_ "SysSignalName" SG_ 755 INOPSysMsg "NOPSysMsg";
BA_ "CompuMethodName" SG_ 755 ILCRInHMI "LCRInHMI";
BA_ "ISignalName" SG_ 755 ILCRInHMI "ILCRInHMI";
BA_ "LongName" SG_ 755 ILCRInHMI "Lane Change Recommendation In Human Machine Interface";
BA_ "SysSignalName" SG_ 755 ILCRInHMI "LCRInHMI";
BA_ "CompuMethodName" SG_ 755 INOADistDecMsg "NOADistDecMsg";
BA_ "ISignalName" SG_ 755 INOADistDecMsg "INOADistDecMsg";
BA_ "LongName" SG_ 755 INOADistDecMsg "NOA distance decrease Message";
BA_ "SysSignalName" SG_ 755 INOADistDecMsg "NOADistDecMsg";
BA_ "CompuMethodName" SG_ 755 INarRoVslAssSwResp "NarRoVslAssSwResp";
BA_ "ISignalName" SG_ 755 INarRoVslAssSwResp "INarRoVslAssSwResp";
BA_ "LongName" SG_ 755 INarRoVslAssSwResp "Narrow road Visual Assist Switch Response";
BA_ "SysSignalName" SG_ 755 INarRoVslAssSwResp "NarRoVslAssSwResp";
BA_ "CompuMethodName" SG_ 755 INrwroadBwdAssMesg "NrwroadBwdAssMesg";
BA_ "ISignalName" SG_ 755 INrwroadBwdAssMesg "INrwroadBwdAssMesg";
BA_ "LongName" SG_ 755 INrwroadBwdAssMesg "Narrow road Backward Assistance Message";
BA_ "SysSignalName" SG_ 755 INrwroadBwdAssMesg "NrwroadBwdAssMesg";
BA_ "CompuMethodName" SG_ 755 IJAMsgReq "JAMsgReq";
BA_ "ISignalName" SG_ 755 IJAMsgReq "IJAMsgReq";
BA_ "LongName" SG_ 755 IJAMsgReq "Junction Assist Message Request";
BA_ "SysSignalName" SG_ 755 IJAMsgReq "JAMsgReq";
BA_ "CompuMethodName" SG_ 755 IDetourMsgReq "DetourMsgReq";
BA_ "ISignalName" SG_ 755 IDetourMsgReq "IDetourMsgReq";
BA_ "LongName" SG_ 755 IDetourMsgReq "Detour Message Request";
BA_ "SysSignalName" SG_ 755 IDetourMsgReq "DetourMsgReq";
BA_ "CompuMethodName" SG_ 755 IParkngOutDircnSelResult "ParkngOutDircnSelResult";
BA_ "ISignalName" SG_ 755 IParkngOutDircnSelResult "IParkngOutDircnSelResult";
BA_ "LongName" SG_ 755 IParkngOutDircnSelResult "Parking Out Direction Select Result";
BA_ "SysSignalName" SG_ 755 IParkngOutDircnSelResult "ParkngOutDircnSelResult";
BA_ "CompuMethodName" SG_ 755 INOAQukChgSwDspCmd "NOAQukChgSwDspCmd";
BA_ "ISignalName" SG_ 755 INOAQukChgSwDspCmd "INOAQukChgSwDspCmd";
BA_ "LongName" SG_ 755 INOAQukChgSwDspCmd "NOA quickly change Switch Display Command";
BA_ "SysSignalName" SG_ 755 INOAQukChgSwDspCmd "NOAQukChgSwDspCmd";
BA_ "CompuMethodName" SG_ 755 INrwroadBwdAssSwSts "NrwroadBwdAssSwSts";
BA_ "ISignalName" SG_ 755 INrwroadBwdAssSwSts "INrwroadBwdAssSwSts";
BA_ "LongName" SG_ 755 INrwroadBwdAssSwSts "Narrow road Backward Assistance Switch Status";
BA_ "SysSignalName" SG_ 755 INrwroadBwdAssSwSts "NrwroadBwdAssSwSts";
BA_ "CompuMethodName" SG_ 755 IFLUSSSts "FLUSSSts";
BA_ "ISignalName" SG_ 755 IFLUSSSts "IFLUSSSts";
BA_ "LongName" SG_ 755 IFLUSSSts "Front Left USS Status";
BA_ "SysSignalName" SG_ 755 IFLUSSSts "FLUSSSts";
BA_ "CompuMethodName" SG_ 755 IPEBSts "PEBSts";
BA_ "ISignalName" SG_ 755 IPEBSts "IPEBSts";
BA_ "LongName" SG_ 755 IPEBSts "Parking_Emergency_Brake_Status";
BA_ "SysSignalName" SG_ 755 IPEBSts "PEBSts";
BA_ "CompuMethodName" SG_ 755 IFrtCarGoNotfrDspCmd "FrtCarGoNotfrDspCmd";
BA_ "ISignalName" SG_ 755 IFrtCarGoNotfrDspCmd "IFrtCarGoNotfrDspCmd";
BA_ "LongName" SG_ 755 IFrtCarGoNotfrDspCmd "FrontCar GoNotifierDisplayCommand";
BA_ "SysSignalName" SG_ 755 IFrtCarGoNotfrDspCmd "FrtCarGoNotfrDspCmd";
BA_ "CompuMethodName" SG_ 755 IFRSUSSSts "FRSUSSSts";
BA_ "ISignalName" SG_ 755 IFRSUSSSts "IFRSUSSSts";
BA_ "LongName" SG_ 755 IFRSUSSSts "Front Right Side USS Status";
BA_ "SysSignalName" SG_ 755 IFRSUSSSts "FRSUSSSts";
BA_ "CompuMethodName" SG_ 755 IFMRUSSSts "FMRUSSSts";
BA_ "ISignalName" SG_ 755 IFMRUSSSts "IFMRUSSSts";
BA_ "LongName" SG_ 755 IFMRUSSSts "Front Middle Right USS Status";
BA_ "SysSignalName" SG_ 755 IFMRUSSSts "FMRUSSSts";
BA_ "CompuMethodName" SG_ 755 IFMLUSSSts "FMLUSSSts";
BA_ "ISignalName" SG_ 755 IFMLUSSSts "IFMLUSSSts";
BA_ "LongName" SG_ 755 IFMLUSSSts "Front Middle Left USS Status";
BA_ "SysSignalName" SG_ 755 IFMLUSSSts "FMLUSSSts";
BA_ "CompuMethodName" SG_ 755 INOALaneSetDspCmd "NOALaneSetDspCmd";
BA_ "ISignalName" SG_ 755 INOALaneSetDspCmd "INOALaneSetDspCmd";
BA_ "LongName" SG_ 755 INOALaneSetDspCmd "NOA Lane Set Display Command";
BA_ "SysSignalName" SG_ 755 INOALaneSetDspCmd "NOALaneSetDspCmd";
BA_ "CompuMethodName" SG_ 755 INOAETCSetDspCmd "NOAETCSetDspCmd";
BA_ "ISignalName" SG_ 755 INOAETCSetDspCmd "INOAETCSetDspCmd";
BA_ "LongName" SG_ 755 INOAETCSetDspCmd "NOA ETC Set Display Command";
BA_ "SysSignalName" SG_ 755 INOAETCSetDspCmd "NOAETCSetDspCmd";
BA_ "CompuMethodName" SG_ 755 ILCRSwDspCmd "LCRSwDspCmd";
BA_ "ISignalName" SG_ 755 ILCRSwDspCmd "ILCRSwDspCmd";
BA_ "LongName" SG_ 755 ILCRSwDspCmd "Lane Change Recommendation Switch Display Command";
BA_ "SysSignalName" SG_ 755 ILCRSwDspCmd "LCRSwDspCmd";
BA_ "CompuMethodName" SG_ 755 IFRUSSSts "FRUSSSts";
BA_ "ISignalName" SG_ 755 IFRUSSSts "IFRUSSSts";
BA_ "LongName" SG_ 755 IFRUSSSts "Front Right USS Status";
BA_ "SysSignalName" SG_ 755 IFRUSSSts "FRUSSSts";
BA_ "CompuMethodName" SG_ 755 INOPCitySwDspCmd "NOPCitySwDspCmd";
BA_ "ISignalName" SG_ 755 INOPCitySwDspCmd "INOPCitySwDspCmd";
BA_ "LongName" SG_ 755 INOPCitySwDspCmd "Navigation On Pilot City Display Command";
BA_ "SysSignalName" SG_ 755 INOPCitySwDspCmd "NOPCitySwDspCmd";
BA_ "CompuMethodName" SG_ 755 INOPSwDspCmd "NOPSwDspCmd";
BA_ "ISignalName" SG_ 755 INOPSwDspCmd "INOPSwDspCmd";
BA_ "LongName" SG_ 755 INOPSwDspCmd "Nop Switch Request Display Command";
BA_ "SysSignalName" SG_ 755 INOPSwDspCmd "NOPSwDspCmd";
BA_ "CompuMethodName" SG_ 755 INOAReportSetDspCmd "NOAReportSetDspCmd";
BA_ "ISignalName" SG_ 755 INOAReportSetDspCmd "INOAReportSetDspCmd";
BA_ "LongName" SG_ 755 INOAReportSetDspCmd "NOA Report Set Display Command";
BA_ "SysSignalName" SG_ 755 INOAReportSetDspCmd "NOAReportSetDspCmd";
BA_ "CompuMethodName" SG_ 755 IRLUSSSts "RLUSSSts";
BA_ "ISignalName" SG_ 755 IRLUSSSts "IRLUSSSts";
BA_ "LongName" SG_ 755 IRLUSSSts "Rear Left USS Status";
BA_ "SysSignalName" SG_ 755 IRLUSSSts "RLUSSSts";
BA_ "CompuMethodName" SG_ 755 IRLSUSSSts "RLSUSSSts";
BA_ "ISignalName" SG_ 755 IRLSUSSSts "IRLSUSSSts";
BA_ "LongName" SG_ 755 IRLSUSSSts "Rear Left Side USS Status";
BA_ "SysSignalName" SG_ 755 IRLSUSSSts "RLSUSSSts";
BA_ "CompuMethodName" SG_ 755 IPEBWarngReq "PEBWarngReq";
BA_ "ISignalName" SG_ 755 IPEBWarngReq "IPEBWarngReq";
BA_ "LongName" SG_ 755 IPEBWarngReq "Parking_Emergency_Brake_Warning_Request";
BA_ "SysSignalName" SG_ 755 IPEBWarngReq "PEBWarngReq";
BA_ "CompuMethodName" SG_ 755 INrwroadBwdAssConfrmSwDscmd "NrwroadBwdAssConfrmSwDscmd";
BA_ "ISignalName" SG_ 755 INrwroadBwdAssConfrmSwDscmd "INrwroadBwdAssConfrmSwDscmd";
BA_ "LongName" SG_ 755 INrwroadBwdAssConfrmSwDscmd "Narrow road Backward Assistance Conform Switch Display command";
BA_ "SysSignalName" SG_ 755 INrwroadBwdAssConfrmSwDscmd "NrwroadBwdAssConfrmSwDscmd";
BA_ "CompuMethodName" SG_ 755 IRRUSSSts "RRUSSSts";
BA_ "ISignalName" SG_ 755 IRRUSSSts "IRRUSSSts";
BA_ "LongName" SG_ 755 IRRUSSSts "Rear Right USS Status";
BA_ "SysSignalName" SG_ 755 IRRUSSSts "RRUSSSts";
BA_ "CompuMethodName" SG_ 755 IRRSUSSSts "RRSUSSSts";
BA_ "ISignalName" SG_ 755 IRRSUSSSts "IRRSUSSSts";
BA_ "LongName" SG_ 755 IRRSUSSSts "Rear Right Side USS Status";
BA_ "SysSignalName" SG_ 755 IRRSUSSSts "RRSUSSSts";
BA_ "CompuMethodName" SG_ 755 IRMRUSSSts "RMRUSSSts";
BA_ "ISignalName" SG_ 755 IRMRUSSSts "IRMRUSSSts";
BA_ "LongName" SG_ 755 IRMRUSSSts "Rear Middle Right USS Status";
BA_ "SysSignalName" SG_ 755 IRMRUSSSts "RMRUSSSts";
BA_ "CompuMethodName" SG_ 755 IRMLUSSSts "RMLUSSSts";
BA_ "ISignalName" SG_ 755 IRMLUSSSts "IRMLUSSSts";
BA_ "LongName" SG_ 755 IRMLUSSSts "Rear Middle Left USS Status";
BA_ "SysSignalName" SG_ 755 IRMLUSSSts "RMLUSSSts";
BA_ "CompuMethodName" SG_ 755 IParkngOutFRCrsSts "ParkngOutFRCrsSts";
BA_ "ISignalName" SG_ 755 IParkngOutFRCrsSts "IParkngOutFRCrsSts";
BA_ "LongName" SG_ 755 IParkngOutFRCrsSts "Parking Out Front Right Cross Status";
BA_ "SysSignalName" SG_ 755 IParkngOutFRCrsSts "ParkngOutFRCrsSts";
BA_ "CompuMethodName" SG_ 755 IParkngOutFLParllSts "ParkngOutFLParllSts";
BA_ "ISignalName" SG_ 755 IParkngOutFLParllSts "IParkngOutFLParllSts";
BA_ "LongName" SG_ 755 IParkngOutFLParllSts "Parking Out Front Left Parallel Status";
BA_ "SysSignalName" SG_ 755 IParkngOutFLParllSts "ParkngOutFLParllSts";
BA_ "CompuMethodName" SG_ 755 IParkngOutFLCrsSts "ParkngOutFLCrsSts";
BA_ "ISignalName" SG_ 755 IParkngOutFLCrsSts "IParkngOutFLCrsSts";
BA_ "LongName" SG_ 755 IParkngOutFLCrsSts "Parking Out Front Left Cross Status";
BA_ "SysSignalName" SG_ 755 IParkngOutFLCrsSts "ParkngOutFLCrsSts";
BA_ "CompuMethodName" SG_ 755 IParkngOutBkRCrsSts "ParkngOutBkRCrsSts";
BA_ "ISignalName" SG_ 755 IParkngOutBkRCrsSts "IParkngOutBkRCrsSts";
BA_ "LongName" SG_ 755 IParkngOutBkRCrsSts "Parking Out Back Right Cross Status";
BA_ "SysSignalName" SG_ 755 IParkngOutBkRCrsSts "ParkngOutBkRCrsSts";
BA_ "CompuMethodName" SG_ 755 IParkngOutBkLCrsSts "ParkngOutBkLCrsSts";
BA_ "ISignalName" SG_ 755 IParkngOutBkLCrsSts "IParkngOutBkLCrsSts";
BA_ "LongName" SG_ 755 IParkngOutBkLCrsSts "Parking Out Back Left Cross Status";
BA_ "SysSignalName" SG_ 755 IParkngOutBkLCrsSts "ParkngOutBkLCrsSts";
BA_ "CompuMethodName" SG_ 755 IParkngOutBkCrsSts "ParkngOutBkCrsSts";
BA_ "ISignalName" SG_ 755 IParkngOutBkCrsSts "IParkngOutBkCrsSts";
BA_ "LongName" SG_ 755 IParkngOutBkCrsSts "Parking Out Back Cross Status";
BA_ "SysSignalName" SG_ 755 IParkngOutBkCrsSts "ParkngOutBkCrsSts";
BA_ "CompuMethodName" SG_ 755 IHPPOnRoutSts "HPPOnRoutSts";
BA_ "ISignalName" SG_ 755 IHPPOnRoutSts "IHPPOnRoutSts";
BA_ "LongName" SG_ 755 IHPPOnRoutSts "HPP_On_Rout_Ststus";
BA_ "SysSignalName" SG_ 755 IHPPOnRoutSts "HPPOnRoutSts";
BA_ "CompuMethodName" SG_ 755 IHPPMapBuildSts "HPPMapBuildSts";
BA_ "ISignalName" SG_ 755 IHPPMapBuildSts "IHPPMapBuildSts";
BA_ "LongName" SG_ 755 IHPPMapBuildSts "HPP_Map_Build_Status";
BA_ "SysSignalName" SG_ 755 IHPPMapBuildSts "HPPMapBuildSts";
BA_ "CompuMethodName" SG_ 755 IParkngDirAvlSts "ParkngDirAvlSts";
BA_ "ISignalName" SG_ 755 IParkngDirAvlSts "IParkngDirAvlSts";
BA_ "LongName" SG_ 755 IParkngDirAvlSts "AIParking Function Request";
BA_ "SysSignalName" SG_ 755 IParkngDirAvlSts "ParkngDirAvlSts";
BA_ "CompuMethodName" SG_ 755 IParkngDirSwResp "ParkngDirSwResp";
BA_ "ISignalName" SG_ 755 IParkngDirSwResp "IParkngDirSwResp";
BA_ "LongName" SG_ 755 IParkngDirSwResp "Parking_Direction_Switch_Response";
BA_ "SysSignalName" SG_ 755 IParkngDirSwResp "ParkngDirSwResp";
BA_ "CompuMethodName" SG_ 755 IPEBSwResp "PEBSwResp";
BA_ "ISignalName" SG_ 755 IPEBSwResp "IPEBSwResp";
BA_ "LongName" SG_ 755 IPEBSwResp "Parking_Emergency_Brake_Switch_Response";
BA_ "SysSignalName" SG_ 755 IPEBSwResp "PEBSwResp";
BA_ "CompuMethodName" SG_ 755 IParkngSlotFindSts "ParkngSlotFindSts";
BA_ "ISignalName" SG_ 755 IParkngSlotFindSts "IParkngSlotFindSts";
BA_ "LongName" SG_ 755 IParkngSlotFindSts "Parking Slot Find Status";
BA_ "SysSignalName" SG_ 755 IParkngSlotFindSts "ParkngSlotFindSts";
BA_ "CompuMethodName" SG_ 755 IParkngOutFrtCrsSts "ParkngOutFrtCrsSts";
BA_ "ISignalName" SG_ 755 IParkngOutFrtCrsSts "IParkngOutFrtCrsSts";
BA_ "LongName" SG_ 755 IParkngOutFrtCrsSts "Parking Out Front Cross Status";
BA_ "SysSignalName" SG_ 755 IParkngOutFrtCrsSts "ParkngOutFrtCrsSts";
BA_ "CompuMethodName" SG_ 755 IParkngOutFRParllSts "ParkngOutFRParllSts";
BA_ "ISignalName" SG_ 755 IParkngOutFRParllSts "IParkngOutFRParllSts";
BA_ "LongName" SG_ 755 IParkngOutFRParllSts "Parking Out Front Right Parallel Status";
BA_ "SysSignalName" SG_ 755 IParkngOutFRParllSts "ParkngOutFRParllSts";
BA_ "CompuMethodName" SG_ 486 IIPD_20ms_Group43_CRC "IPD_20ms_Group43_CRC";
BA_ "ISignalName" SG_ 486 IIPD_20ms_Group43_CRC "IIPD_20ms_Group43_CRC";
BA_ "SysSignalName" SG_ 486 IIPD_20ms_Group43_CRC "IPD_20ms_Group43_CRC";
BA_ "CompuMethodName" SG_ 486 IIPD_20ms_Group43_RC "IPD_20ms_Group43_RC";
BA_ "ISignalName" SG_ 486 IIPD_20ms_Group43_RC "IIPD_20ms_Group43_RC";
BA_ "SysSignalName" SG_ 486 IIPD_20ms_Group43_RC "IPD_20ms_Group43_RC";
BA_ "CompuMethodName" SG_ 486 IIPD_20ms_Group43_Reserved1 "IPD_20ms_Group43_Reserved1";
BA_ "GenSigStartValue" SG_ 486 IIPD_20ms_Group43_Reserved1 15;
BA_ "ISignalName" SG_ 486 IIPD_20ms_Group43_Reserved1 "IIPD_20ms_Group43_Reserved1";
BA_ "SysSignalName" SG_ 486 IIPD_20ms_Group43_Reserved1 "IPD_20ms_Group43_Reserved1";
BA_ "CompuMethodName" SG_ 486 IACCAccReqToqVal "ACCAccReqToqVal";
BA_ "ISignalName" SG_ 486 IACCAccReqToqVal "IACCAccReqToqVal";
BA_ "LongName" SG_ 486 IACCAccReqToqVal "Adaptive Cruise Control Acceleration Request Torque Value";
BA_ "SysSignalName" SG_ 486 IACCAccReqToqVal "ACCAccReqToqVal";
BA_ "CompuMethodName" SG_ 486 IIPD_20ms_Group43_Reserved2 "IPD_20ms_Group43_Reserved2";
BA_ "GenSigStartValue" SG_ 486 IIPD_20ms_Group43_Reserved2 7;
BA_ "ISignalName" SG_ 486 IIPD_20ms_Group43_Reserved2 "IIPD_20ms_Group43_Reserved2";
BA_ "SysSignalName" SG_ 486 IIPD_20ms_Group43_Reserved2 "IPD_20ms_Group43_Reserved2";
BA_ "CompuMethodName" SG_ 486 IFrtCarGoNotfr "FrtCarGoNotfr";
BA_ "ISignalName" SG_ 486 IFrtCarGoNotfr "IFrtCarGoNotfr";
BA_ "LongName" SG_ 486 IFrtCarGoNotfr "FrontCar GoNotifier";
BA_ "SysSignalName" SG_ 486 IFrtCarGoNotfr "FrtCarGoNotfr";
BA_ "CompuMethodName" SG_ 486 IACCSysFltSts_SCS "ACCSysFltSts_SCS";
BA_ "ISignalName" SG_ 486 IACCSysFltSts_SCS "IACCSysFltSts_SCS";
BA_ "LongName" SG_ 486 IACCSysFltSts_SCS "Adaptive_Cruise_Control_System_Fault_Status";
BA_ "SysSignalName" SG_ 486 IACCSysFltSts_SCS "ACCSysFltSts_SCS";
BA_ "CompuMethodName" SG_ 486 IIPD_20ms_Group43_Reserved3 "IPD_20ms_Group43_Reserved3";
BA_ "GenSigStartValue" SG_ 486 IIPD_20ms_Group43_Reserved3 255;
BA_ "ISignalName" SG_ 486 IIPD_20ms_Group43_Reserved3 "IIPD_20ms_Group43_Reserved3";
BA_ "SysSignalName" SG_ 486 IIPD_20ms_Group43_Reserved3 "IPD_20ms_Group43_Reserved3";
BA_ "CompuMethodName" SG_ 486 IIPD_20ms_Group43_Reserved4 "IPD_20ms_Group43_Reserved4";
BA_ "GenSigStartValue" SG_ 486 IIPD_20ms_Group43_Reserved4 255;
BA_ "ISignalName" SG_ 486 IIPD_20ms_Group43_Reserved4 "IIPD_20ms_Group43_Reserved4";
BA_ "SysSignalName" SG_ 486 IIPD_20ms_Group43_Reserved4 "IPD_20ms_Group43_Reserved4";
BA_ "CompuMethodName" SG_ 486 IIPD_20ms_Group43_Reserved5 "IPD_20ms_Group43_Reserved5";
BA_ "GenSigStartValue" SG_ 486 IIPD_20ms_Group43_Reserved5 255;
BA_ "ISignalName" SG_ 486 IIPD_20ms_Group43_Reserved5 "IIPD_20ms_Group43_Reserved5";
BA_ "SysSignalName" SG_ 486 IIPD_20ms_Group43_Reserved5 "IPD_20ms_Group43_Reserved5";
BA_ "CompuMethodName" SG_ 337 IIPD_20ms_Group60_CRC "IPD_20ms_Group60_CRC";
BA_ "ISignalName" SG_ 337 IIPD_20ms_Group60_CRC "IIPD_20ms_Group60_CRC";
BA_ "SysSignalName" SG_ 337 IIPD_20ms_Group60_CRC "IPD_20ms_Group60_CRC";
BA_ "CompuMethodName" SG_ 337 IIPD_20ms_Group60_RC "IPD_20ms_Group60_RC";
BA_ "ISignalName" SG_ 337 IIPD_20ms_Group60_RC "IIPD_20ms_Group60_RC";
BA_ "SysSignalName" SG_ 337 IIPD_20ms_Group60_RC "IPD_20ms_Group60_RC";
BA_ "CompuMethodName" SG_ 337 IAutoLaneChngRLaneSts "AutoLaneChngRLaneSts";
BA_ "ISignalName" SG_ 337 IAutoLaneChngRLaneSts "IAutoLaneChngRLaneSts";
BA_ "LongName" SG_ 337 IAutoLaneChngRLaneSts "Auto_Lane_Change_Right_Lane_Status";
BA_ "SysSignalName" SG_ 337 IAutoLaneChngRLaneSts "AutoLaneChngRLaneSts";
BA_ "CompuMethodName" SG_ 337 IIPD_20ms_Group60_Reserved1 "IPD_20ms_Group60_Reserved1";
BA_ "GenSigStartValue" SG_ 337 IIPD_20ms_Group60_Reserved1 255;
BA_ "ISignalName" SG_ 337 IIPD_20ms_Group60_Reserved1 "IIPD_20ms_Group60_Reserved1";
BA_ "SysSignalName" SG_ 337 IIPD_20ms_Group60_Reserved1 "IPD_20ms_Group60_Reserved1";
BA_ "CompuMethodName" SG_ 337 IIPD_20ms_Group60_Reserved2 "IPD_20ms_Group60_Reserved2";
BA_ "GenSigStartValue" SG_ 337 IIPD_20ms_Group60_Reserved2 255;
BA_ "ISignalName" SG_ 337 IIPD_20ms_Group60_Reserved2 "IIPD_20ms_Group60_Reserved2";
BA_ "SysSignalName" SG_ 337 IIPD_20ms_Group60_Reserved2 "IPD_20ms_Group60_Reserved2";
BA_ "CompuMethodName" SG_ 337 IAPASCSToqReqVal "APASCSToqReqVal";
BA_ "ISignalName" SG_ 337 IAPASCSToqReqVal "IAPASCSToqReqVal";
BA_ "LongName" SG_ 337 IAPASCSToqReqVal "Advance Park Assist Stability Control System Torque Request Value";
BA_ "SysSignalName" SG_ 337 IAPASCSToqReqVal "APASCSToqReqVal";
BA_ "CompuMethodName" SG_ 337 IAPAVehCrdnatPosY "APAVehCrdnatPosY";
BA_ "ISignalName" SG_ 337 IAPAVehCrdnatPosY "IAPAVehCrdnatPosY";
BA_ "LongName" SG_ 337 IAPAVehCrdnatPosY "Advanced_Park_Assist_Vehicle_Coordinate_Position_Y";
BA_ "SysSignalName" SG_ 337 IAPAVehCrdnatPosY "APAVehCrdnatPosY";
BA_ "CompuMethodName" SG_ 337 IAPAVehCrdnatAzmth "APAVehCrdnatAzmth";
BA_ "ISignalName" SG_ 337 IAPAVehCrdnatAzmth "IAPAVehCrdnatAzmth";
BA_ "LongName" SG_ 337 IAPAVehCrdnatAzmth "Advanced_Park_Assist_Vehicle_Coordinate_Azimuth";
BA_ "SysSignalName" SG_ 337 IAPAVehCrdnatAzmth "APAVehCrdnatAzmth";
BA_ "CompuMethodName" SG_ 337 IESSDirInd "ESSDirInd";
BA_ "GenSigStartValue" SG_ 337 IESSDirInd 2;
BA_ "ISignalName" SG_ 337 IESSDirInd "IESSDirInd";
BA_ "LongName" SG_ 337 IESSDirInd "Emergency_Steering_System _Direction_Indication";
BA_ "SysSignalName" SG_ 337 IESSDirInd "ESSDirInd";
BA_ "CompuMethodName" SG_ 337 IIPD_20ms_Group60_Reserved3 "IPD_20ms_Group60_Reserved3";
BA_ "GenSigStartValue" SG_ 337 IIPD_20ms_Group60_Reserved3 7;
BA_ "ISignalName" SG_ 337 IIPD_20ms_Group60_Reserved3 "IIPD_20ms_Group60_Reserved3";
BA_ "SysSignalName" SG_ 337 IIPD_20ms_Group60_Reserved3 "IPD_20ms_Group60_Reserved3";
BA_ "CompuMethodName" SG_ 337 IPilotTkovMsgReq "PilotTkovMsgReq";
BA_ "ISignalName" SG_ 337 IPilotTkovMsgReq "IPilotTkovMsgReq";
BA_ "LongName" SG_ 337 IPilotTkovMsgReq "Pilot Take Over Message Request";
BA_ "SysSignalName" SG_ 337 IPilotTkovMsgReq "PilotTkovMsgReq";
BA_ "CompuMethodName" SG_ 337 INOPSysSts_ZPD "NOPSysSts_ZPD";
BA_ "ISignalName" SG_ 337 INOPSysSts_ZPD "INOPSysSts_ZPD";
BA_ "LongName" SG_ 337 INOPSysSts_ZPD "Navigation On Pilot System Status";
BA_ "SysSignalName" SG_ 337 INOPSysSts_ZPD "NOPSysSts_ZPD";
BA_ "CompuMethodName" SG_ 337 IPrkgDstCtrlSwResp "PrkgDstCtrlSwResp";
BA_ "GenSigStartValue" SG_ 337 IPrkgDstCtrlSwResp 1;
BA_ "ISignalName" SG_ 337 IPrkgDstCtrlSwResp "IPrkgDstCtrlSwResp";
BA_ "LongName" SG_ 337 IPrkgDstCtrlSwResp "Parking Distance Ctrl Switch Response";
BA_ "SysSignalName" SG_ 337 IPrkgDstCtrlSwResp "PrkgDstCtrlSwResp";
BA_ "CompuMethodName" SG_ 337 IALCSysSts "ALCSysSts";
BA_ "ISignalName" SG_ 337 IALCSysSts "IALCSysSts";
BA_ "LongName" SG_ 337 IALCSysSts "Auto_Lane_Change_System_Status";
BA_ "SysSignalName" SG_ 337 IALCSysSts "ALCSysSts";
BA_ "CompuMethodName" SG_ 337 IALCSysFltSts "ALCSysFltSts";
BA_ "ISignalName" SG_ 337 IALCSysFltSts "IALCSysFltSts";
BA_ "LongName" SG_ 337 IALCSysFltSts "ALC System Failure Status";
BA_ "SysSignalName" SG_ 337 IALCSysFltSts "ALCSysFltSts";
BA_ "CompuMethodName" SG_ 337 IAPAVehCrdnatPosX "APAVehCrdnatPosX";
BA_ "ISignalName" SG_ 337 IAPAVehCrdnatPosX "IAPAVehCrdnatPosX";
BA_ "LongName" SG_ 337 IAPAVehCrdnatPosX "Advanced_Park_Assist_Vehicle_Coordinate_Position_X";
BA_ "SysSignalName" SG_ 337 IAPAVehCrdnatPosX "APAVehCrdnatPosX";
BA_ "CompuMethodName" SG_ 337 IAutoLaneChngLLaneSts "AutoLaneChngLLaneSts";
BA_ "ISignalName" SG_ 337 IAutoLaneChngLLaneSts "IAutoLaneChngLLaneSts";
BA_ "LongName" SG_ 337 IAutoLaneChngLLaneSts "Auto_Lane_Change_Left_Lane_Status";
BA_ "SysSignalName" SG_ 337 IAutoLaneChngLLaneSts "AutoLaneChngLLaneSts";
BA_ "CompuMethodName" SG_ 337 IIPD_20ms_Group60_Reserved4 "IPD_20ms_Group60_Reserved4";
BA_ "GenSigStartValue" SG_ 337 IIPD_20ms_Group60_Reserved4 3;
BA_ "ISignalName" SG_ 337 IIPD_20ms_Group60_Reserved4 "IIPD_20ms_Group60_Reserved4";
BA_ "SysSignalName" SG_ 337 IIPD_20ms_Group60_Reserved4 "IPD_20ms_Group60_Reserved4";
BA_ "CompuMethodName" SG_ 337 IESSSysSts "ESSSysSts";
BA_ "GenSigStartValue" SG_ 337 IESSSysSts 1;
BA_ "ISignalName" SG_ 337 IESSSysSts "IESSSysSts";
BA_ "LongName" SG_ 337 IESSSysSts "Emergency_Steering_System_Status";
BA_ "SysSignalName" SG_ 337 IESSSysSts "ESSSysSts";
BA_ "CompuMethodName" SG_ 337 IESSSysFltSts "ESSSysFltSts";
BA_ "ISignalName" SG_ 337 IESSSysFltSts "IESSSysFltSts";
BA_ "LongName" SG_ 337 IESSSysFltSts "Emergency_Steering_System_Fault_Status";
BA_ "SysSignalName" SG_ 337 IESSSysFltSts "ESSSysFltSts";
BA_ "CompuMethodName" SG_ 337 IIPD_20ms_Group60_Reserved5 "IPD_20ms_Group60_Reserved5";
BA_ "GenSigStartValue" SG_ 337 IIPD_20ms_Group60_Reserved5 1;
BA_ "ISignalName" SG_ 337 IIPD_20ms_Group60_Reserved5 "IIPD_20ms_Group60_Reserved5";
BA_ "SysSignalName" SG_ 337 IIPD_20ms_Group60_Reserved5 "IPD_20ms_Group60_Reserved5";
BA_ "CompuMethodName" SG_ 337 IESSDrvrTkovReq "ESSDrvrTkovReq";
BA_ "ISignalName" SG_ 337 IESSDrvrTkovReq "IESSDrvrTkovReq";
BA_ "LongName" SG_ 337 IESSDrvrTkovReq "Emergency_Steering_System_Takeover_Request";
BA_ "SysSignalName" SG_ 337 IESSDrvrTkovReq "ESSDrvrTkovReq";
BA_ "CompuMethodName" SG_ 337 ISLIFSysFltSts "SLIFSysFltSts";
BA_ "ISignalName" SG_ 337 ISLIFSysFltSts "ISLIFSysFltSts";
BA_ "LongName" SG_ 337 ISLIFSysFltSts "Speed_Limit_Information_Function_System_Fault_Status";
BA_ "SysSignalName" SG_ 337 ISLIFSysFltSts "SLIFSysFltSts";
BA_ "CompuMethodName" SG_ 337 IParkngslottype "Parkngslottype";
BA_ "ISignalName" SG_ 337 IParkngslottype "IParkngslottype";
BA_ "LongName" SG_ 337 IParkngslottype "Parking Slot Type";
BA_ "SysSignalName" SG_ 337 IParkngslottype "Parkngslottype";
BA_ "CompuMethodName" SG_ 337 IIPD_20ms_Group60_Reserved6 "IPD_20ms_Group60_Reserved6";
BA_ "GenSigStartValue" SG_ 337 IIPD_20ms_Group60_Reserved6 31;
BA_ "ISignalName" SG_ 337 IIPD_20ms_Group60_Reserved6 "IIPD_20ms_Group60_Reserved6";
BA_ "SysSignalName" SG_ 337 IIPD_20ms_Group60_Reserved6 "IPD_20ms_Group60_Reserved6";
BA_ "CompuMethodName" SG_ 337 INOPSysFltSts "NOPSysFltSts";
BA_ "ISignalName" SG_ 337 INOPSysFltSts "INOPSysFltSts";
BA_ "LongName" SG_ 337 INOPSysFltSts "Nop System Failure Status";
BA_ "SysSignalName" SG_ 337 INOPSysFltSts "NOPSysFltSts";
BA_ "CompuMethodName" SG_ 337 IIPD_20ms_Group60_Reserved7 "IPD_20ms_Group60_Reserved7";
BA_ "GenSigStartValue" SG_ 337 IIPD_20ms_Group60_Reserved7 255;
BA_ "ISignalName" SG_ 337 IIPD_20ms_Group60_Reserved7 "IIPD_20ms_Group60_Reserved7";
BA_ "SysSignalName" SG_ 337 IIPD_20ms_Group60_Reserved7 "IPD_20ms_Group60_Reserved7";
BA_ "CompuMethodName" SG_ 337 IIPD_20ms_Group60_Reserved8 "IPD_20ms_Group60_Reserved8";
BA_ "GenSigStartValue" SG_ 337 IIPD_20ms_Group60_Reserved8 255;
BA_ "ISignalName" SG_ 337 IIPD_20ms_Group60_Reserved8 "IIPD_20ms_Group60_Reserved8";
BA_ "SysSignalName" SG_ 337 IIPD_20ms_Group60_Reserved8 "IPD_20ms_Group60_Reserved8";
BA_ "CompuMethodName" SG_ 337 IIPD_20ms_Group60_Reserved9 "IPD_20ms_Group60_Reserved9";
BA_ "GenSigStartValue" SG_ 337 IIPD_20ms_Group60_Reserved9 255;
BA_ "ISignalName" SG_ 337 IIPD_20ms_Group60_Reserved9 "IIPD_20ms_Group60_Reserved9";
BA_ "SysSignalName" SG_ 337 IIPD_20ms_Group60_Reserved9 "IPD_20ms_Group60_Reserved9";
BA_ "CompuMethodName" SG_ 337 IIPD_20ms_Group60_Reserved10 "IPD_20ms_Group60_Reserved10";
BA_ "GenSigStartValue" SG_ 337 IIPD_20ms_Group60_Reserved10 255;
BA_ "ISignalName" SG_ 337 IIPD_20ms_Group60_Reserved10 "IIPD_20ms_Group60_Reserved10";
BA_ "SysSignalName" SG_ 337 IIPD_20ms_Group60_Reserved10 "IPD_20ms_Group60_Reserved10";
BA_ "CompuMethodName" SG_ 720 IIPD_50ms_Group14_CRC "IPD_50ms_Group14_CRC";
BA_ "ISignalName" SG_ 720 IIPD_50ms_Group14_CRC "IIPD_50ms_Group14_CRC";
BA_ "SysSignalName" SG_ 720 IIPD_50ms_Group14_CRC "IPD_50ms_Group14_CRC";
BA_ "CompuMethodName" SG_ 720 IIPD_50ms_Group14_RC "IPD_50ms_Group14_RC";
BA_ "ISignalName" SG_ 720 IIPD_50ms_Group14_RC "IIPD_50ms_Group14_RC";
BA_ "SysSignalName" SG_ 720 IIPD_50ms_Group14_RC "IPD_50ms_Group14_RC";
BA_ "CompuMethodName" SG_ 720 IIPD_50ms_Group14_Reserved1 "IPD_50ms_Group14_Reserved1";
BA_ "GenSigStartValue" SG_ 720 IIPD_50ms_Group14_Reserved1 15;
BA_ "ISignalName" SG_ 720 IIPD_50ms_Group14_Reserved1 "IIPD_50ms_Group14_Reserved1";
BA_ "SysSignalName" SG_ 720 IIPD_50ms_Group14_Reserved1 "IPD_50ms_Group14_Reserved1";
BA_ "CompuMethodName" SG_ 720 IIPD_50ms_Group14_Reserved2 "IPD_50ms_Group14_Reserved2";
BA_ "GenSigStartValue" SG_ 720 IIPD_50ms_Group14_Reserved2 255;
BA_ "ISignalName" SG_ 720 IIPD_50ms_Group14_Reserved2 "IIPD_50ms_Group14_Reserved2";
BA_ "SysSignalName" SG_ 720 IIPD_50ms_Group14_Reserved2 "IPD_50ms_Group14_Reserved2";
BA_ "CompuMethodName" SG_ 720 IIPD_50ms_Group14_Reserved3 "IPD_50ms_Group14_Reserved3";
BA_ "GenSigStartValue" SG_ 720 IIPD_50ms_Group14_Reserved3 255;
BA_ "ISignalName" SG_ 720 IIPD_50ms_Group14_Reserved3 "IIPD_50ms_Group14_Reserved3";
BA_ "SysSignalName" SG_ 720 IIPD_50ms_Group14_Reserved3 "IPD_50ms_Group14_Reserved3";
BA_ "CompuMethodName" SG_ 720 IIPD_50ms_Group14_Reserved4 "IPD_50ms_Group14_Reserved4";
BA_ "GenSigStartValue" SG_ 720 IIPD_50ms_Group14_Reserved4 255;
BA_ "ISignalName" SG_ 720 IIPD_50ms_Group14_Reserved4 "IIPD_50ms_Group14_Reserved4";
BA_ "SysSignalName" SG_ 720 IIPD_50ms_Group14_Reserved4 "IPD_50ms_Group14_Reserved4";
BA_ "CompuMethodName" SG_ 720 IIPD_50ms_Group14_Reserved5 "IPD_50ms_Group14_Reserved5";
BA_ "GenSigStartValue" SG_ 720 IIPD_50ms_Group14_Reserved5 255;
BA_ "ISignalName" SG_ 720 IIPD_50ms_Group14_Reserved5 "IIPD_50ms_Group14_Reserved5";
BA_ "SysSignalName" SG_ 720 IIPD_50ms_Group14_Reserved5 "IPD_50ms_Group14_Reserved5";
BA_ "CompuMethodName" SG_ 720 IIPD_50ms_Group14_Reserved6 "IPD_50ms_Group14_Reserved6";
BA_ "GenSigStartValue" SG_ 720 IIPD_50ms_Group14_Reserved6 255;
BA_ "ISignalName" SG_ 720 IIPD_50ms_Group14_Reserved6 "IIPD_50ms_Group14_Reserved6";
BA_ "SysSignalName" SG_ 720 IIPD_50ms_Group14_Reserved6 "IPD_50ms_Group14_Reserved6";
BA_ "CompuMethodName" SG_ 720 ILADSInfoDispReq "LADSInfoDispReq";
BA_ "ISignalName" SG_ 720 ILADSInfoDispReq "ILADSInfoDispReq";
BA_ "LongName" SG_ 720 ILADSInfoDispReq "Low Speed Automated Driving System Information Display Request";
BA_ "SysSignalName" SG_ 720 ILADSInfoDispReq "LADSInfoDispReq";
BA_ "CompuMethodName" SG_ 720 ILADSInfoDispReqToICM "LADSInfoDispReqToICM";
BA_ "ISignalName" SG_ 720 ILADSInfoDispReqToICM "ILADSInfoDispReqToICM";
BA_ "LongName" SG_ 720 ILADSInfoDispReqToICM "Low Speed Automated Driving System Informaiton Display Request To Intelligent Cockpit Module";
BA_ "SysSignalName" SG_ 720 ILADSInfoDispReqToICM "LADSInfoDispReqToICM";
BA_ "CompuMethodName" SG_ 720 IIPD_50ms_Group14_Reserved7 "IPD_50ms_Group14_Reserved7";
BA_ "GenSigStartValue" SG_ 720 IIPD_50ms_Group14_Reserved7 1;
BA_ "ISignalName" SG_ 720 IIPD_50ms_Group14_Reserved7 "IIPD_50ms_Group14_Reserved7";
BA_ "SysSignalName" SG_ 720 IIPD_50ms_Group14_Reserved7 "IPD_50ms_Group14_Reserved7";
BA_ "CompuMethodName" SG_ 720 ILADSProgressBar "LADSProgressBar";
BA_ "ISignalName" SG_ 720 ILADSProgressBar "ILADSProgressBar";
BA_ "LongName" SG_ 720 ILADSProgressBar "Lads_Progress_Bar";
BA_ "SysSignalName" SG_ 720 ILADSProgressBar "LADSProgressBar";
BA_ "CompuMethodName" SG_ 720 ISDWLSRObsRng "SDWLSRObsRng";
BA_ "ISignalName" SG_ 720 ISDWLSRObsRng "ISDWLSRObsRng";
BA_ "LongName" SG_ 720 ISDWLSRObsRng "SDW Left Side Rear Obstacle Range";
BA_ "SysSignalName" SG_ 720 ISDWLSRObsRng "SDWLSRObsRng";
BA_ "CompuMethodName" SG_ 720 ISDWLSFObsRng "SDWLSFObsRng";
BA_ "ISignalName" SG_ 720 ISDWLSFObsRng "ISDWLSFObsRng";
BA_ "LongName" SG_ 720 ISDWLSFObsRng "SDW Left Side Front Obstacle Range";
BA_ "SysSignalName" SG_ 720 ISDWLSFObsRng "SDWLSFObsRng";
BA_ "CompuMethodName" SG_ 720 ISDWRSRObsRng "SDWRSRObsRng";
BA_ "ISignalName" SG_ 720 ISDWRSRObsRng "ISDWRSRObsRng";
BA_ "LongName" SG_ 720 ISDWRSRObsRng "SDW Right Side Rear Obstacle Range";
BA_ "SysSignalName" SG_ 720 ISDWRSRObsRng "SDWRSRObsRng";
BA_ "CompuMethodName" SG_ 720 ISDWRSFObsRng "SDWRSFObsRng";
BA_ "ISignalName" SG_ 720 ISDWRSFObsRng "ISDWRSFObsRng";
BA_ "LongName" SG_ 720 ISDWRSFObsRng "SDW Right Side Front Obstacle Range";
BA_ "SysSignalName" SG_ 720 ISDWRSFObsRng "SDWRSFObsRng";
BA_ "CompuMethodName" SG_ 720 IIPD_50ms_Group14_Reserved8 "IPD_50ms_Group14_Reserved8";
BA_ "GenSigStartValue" SG_ 720 IIPD_50ms_Group14_Reserved8 255;
BA_ "ISignalName" SG_ 720 IIPD_50ms_Group14_Reserved8 "IIPD_50ms_Group14_Reserved8";
BA_ "SysSignalName" SG_ 720 IIPD_50ms_Group14_Reserved8 "IPD_50ms_Group14_Reserved8";
BA_ "CompuMethodName" SG_ 720 IIPD_50ms_Group14_Reserved9 "IPD_50ms_Group14_Reserved9";
BA_ "GenSigStartValue" SG_ 720 IIPD_50ms_Group14_Reserved9 255;
BA_ "ISignalName" SG_ 720 IIPD_50ms_Group14_Reserved9 "IIPD_50ms_Group14_Reserved9";
BA_ "SysSignalName" SG_ 720 IIPD_50ms_Group14_Reserved9 "IPD_50ms_Group14_Reserved9";
BA_ "CompuMethodName" SG_ 720 IIPD_50ms_Group14_Reserved10 "IPD_50ms_Group14_Reserved10";
BA_ "GenSigStartValue" SG_ 720 IIPD_50ms_Group14_Reserved10 255;
BA_ "ISignalName" SG_ 720 IIPD_50ms_Group14_Reserved10 "IIPD_50ms_Group14_Reserved10";
BA_ "SysSignalName" SG_ 720 IIPD_50ms_Group14_Reserved10 "IPD_50ms_Group14_Reserved10";
BA_ "CompuMethodName" SG_ 720 IIPD_50ms_Group14_Reserved11 "IPD_50ms_Group14_Reserved11";
BA_ "GenSigStartValue" SG_ 720 IIPD_50ms_Group14_Reserved11 255;
BA_ "ISignalName" SG_ 720 IIPD_50ms_Group14_Reserved11 "IIPD_50ms_Group14_Reserved11";
BA_ "SysSignalName" SG_ 720 IIPD_50ms_Group14_Reserved11 "IPD_50ms_Group14_Reserved11";
BA_ "CompuMethodName" SG_ 733 IIPD_50ms_Group49_CRC "IPD_50ms_Group49_CRC";
BA_ "ISignalName" SG_ 733 IIPD_50ms_Group49_CRC "IIPD_50ms_Group49_CRC";
BA_ "SysSignalName" SG_ 733 IIPD_50ms_Group49_CRC "IPD_50ms_Group49_CRC";
BA_ "CompuMethodName" SG_ 733 IIPD_50ms_Group49_RC "IPD_50ms_Group49_RC";
BA_ "ISignalName" SG_ 733 IIPD_50ms_Group49_RC "IIPD_50ms_Group49_RC";
BA_ "SysSignalName" SG_ 733 IIPD_50ms_Group49_RC "IPD_50ms_Group49_RC";
BA_ "CompuMethodName" SG_ 733 IKeepPwrRsnIPD "KeepPwrRsnIPD";
BA_ "ISignalName" SG_ 733 IKeepPwrRsnIPD "IKeepPwrRsnIPD";
BA_ "LongName" SG_ 733 IKeepPwrRsnIPD "Keep Power Reason IPD";
BA_ "SysSignalName" SG_ 733 IKeepPwrRsnIPD "KeepPwrRsnIPD";
BA_ "CompuMethodName" SG_ 733 IIPD_50ms_Group49_Reserved1 "IPD_50ms_Group49_Reserved1";
BA_ "GenSigStartValue" SG_ 733 IIPD_50ms_Group49_Reserved1 31;
BA_ "ISignalName" SG_ 733 IIPD_50ms_Group49_Reserved1 "IIPD_50ms_Group49_Reserved1";
BA_ "SysSignalName" SG_ 733 IIPD_50ms_Group49_Reserved1 "IPD_50ms_Group49_Reserved1";
BA_ "CompuMethodName" SG_ 733 ISysPwrMdCtrl "SysPwrMdCtrl";
BA_ "ISignalName" SG_ 733 ISysPwrMdCtrl "ISysPwrMdCtrl";
BA_ "LongName" SG_ 733 ISysPwrMdCtrl "System power mode control";
BA_ "SysSignalName" SG_ 733 ISysPwrMdCtrl "SysPwrMdCtrl";
BA_ "CompuMethodName" SG_ 733 IIPD_50ms_Group49_Reserved2 "IPD_50ms_Group49_Reserved2";
BA_ "GenSigStartValue" SG_ 733 IIPD_50ms_Group49_Reserved2 255;
BA_ "ISignalName" SG_ 733 IIPD_50ms_Group49_Reserved2 "IIPD_50ms_Group49_Reserved2";
BA_ "SysSignalName" SG_ 733 IIPD_50ms_Group49_Reserved2 "IPD_50ms_Group49_Reserved2";
BA_ "CompuMethodName" SG_ 733 IIPD_50ms_Group49_Reserved3 "IPD_50ms_Group49_Reserved3";
BA_ "GenSigStartValue" SG_ 733 IIPD_50ms_Group49_Reserved3 255;
BA_ "ISignalName" SG_ 733 IIPD_50ms_Group49_Reserved3 "IIPD_50ms_Group49_Reserved3";
BA_ "SysSignalName" SG_ 733 IIPD_50ms_Group49_Reserved3 "IPD_50ms_Group49_Reserved3";
BA_ "CompuMethodName" SG_ 733 IIPD_50ms_Group49_Reserved4 "IPD_50ms_Group49_Reserved4";
BA_ "GenSigStartValue" SG_ 733 IIPD_50ms_Group49_Reserved4 255;
BA_ "ISignalName" SG_ 733 IIPD_50ms_Group49_Reserved4 "IIPD_50ms_Group49_Reserved4";
BA_ "SysSignalName" SG_ 733 IIPD_50ms_Group49_Reserved4 "IPD_50ms_Group49_Reserved4";
BA_ "CompuMethodName" SG_ 733 IIPD_50ms_Group49_Reserved5 "IPD_50ms_Group49_Reserved5";
BA_ "GenSigStartValue" SG_ 733 IIPD_50ms_Group49_Reserved5 255;
BA_ "ISignalName" SG_ 733 IIPD_50ms_Group49_Reserved5 "IIPD_50ms_Group49_Reserved5";
BA_ "SysSignalName" SG_ 733 IIPD_50ms_Group49_Reserved5 "IPD_50ms_Group49_Reserved5";
BA_ "CompuMethodName" SG_ 733 IIPD_50ms_Group49_Reserved6 "IPD_50ms_Group49_Reserved6";
BA_ "GenSigStartValue" SG_ 733 IIPD_50ms_Group49_Reserved6 255;
BA_ "ISignalName" SG_ 733 IIPD_50ms_Group49_Reserved6 "IIPD_50ms_Group49_Reserved6";
BA_ "SysSignalName" SG_ 733 IIPD_50ms_Group49_Reserved6 "IPD_50ms_Group49_Reserved6";
BA_ "CompuMethodName" SG_ 1143 ISyncMsgType "SyncMsgType";
BA_ "ISignalName" SG_ 1143 ISyncMsgType "ISyncMsgType";
BA_ "LongName" SG_ 1143 ISyncMsgType "Time synchronization message - type";
BA_ "SysSignalName" SG_ 1143 ISyncMsgType "SyncMsgType";
BA_ "CompuMethodName" SG_ 1143 ISyncMsgCheckSum "SyncMsgCheckSum";
BA_ "ISignalName" SG_ 1143 ISyncMsgCheckSum "ISyncMsgCheckSum";
BA_ "LongName" SG_ 1143 ISyncMsgCheckSum "Time synchronization message - CRC";
BA_ "SysSignalName" SG_ 1143 ISyncMsgCheckSum "SyncMsgCheckSum";
BA_ "CompuMethodName" SG_ 1143 ISyncMsgSequenceCounter "SyncMsgSequenceCounter";
BA_ "ISignalName" SG_ 1143 ISyncMsgSequenceCounter "ISyncMsgSequenceCounter";
BA_ "LongName" SG_ 1143 ISyncMsgSequenceCounter "Time synchronization message - sequence counter";
BA_ "SysSignalName" SG_ 1143 ISyncMsgSequenceCounter "SyncMsgSequenceCounter";
BA_ "CompuMethodName" SG_ 1143 ISyncMsgTimeDomain "SyncMsgTimeDomain";
BA_ "GenSigStartValue" SG_ 1143 ISyncMsgTimeDomain 1;
BA_ "ISignalName" SG_ 1143 ISyncMsgTimeDomain "ISyncMsgTimeDomain";
BA_ "LongName" SG_ 1143 ISyncMsgTimeDomain "Time synchronization message - time domain";
BA_ "SysSignalName" SG_ 1143 ISyncMsgTimeDomain "SyncMsgTimeDomain";
BA_ "CompuMethodName" SG_ 1143 ISyncMsgOVS "SyncMsgOVS";
BA_ "ISignalName" SG_ 1143 ISyncMsgOVS "ISyncMsgOVS";
BA_ "LongName" SG_ 1143 ISyncMsgOVS "Time synchronization message - overflow of second";
BA_ "SysSignalName" SG_ 1143 ISyncMsgOVS "SyncMsgOVS";
BA_ "CompuMethodName" SG_ 1143 ISyncMsgSGW "SyncMsgSGW";
BA_ "ISignalName" SG_ 1143 ISyncMsgSGW "ISyncMsgSGW";
BA_ "LongName" SG_ 1143 ISyncMsgSGW "Time synchronization message - time gateway synchronization status";
BA_ "SysSignalName" SG_ 1143 ISyncMsgSGW "SyncMsgSGW";
BA_ "CompuMethodName" SG_ 1143 ISyncMsgreserved "SyncMsgreserved";
BA_ "ISignalName" SG_ 1143 ISyncMsgreserved "ISyncMsgreserved";
BA_ "LongName" SG_ 1143 ISyncMsgreserved "Time synchronization message - reserved";
BA_ "SysSignalName" SG_ 1143 ISyncMsgreserved "SyncMsgreserved";
BA_ "CompuMethodName" SG_ 1143 ISyncMsgTime "SyncMsgTime";
BA_ "ISignalName" SG_ 1143 ISyncMsgTime "ISyncMsgTime";
BA_ "LongName" SG_ 1143 ISyncMsgTime "Time synchronization message - synchronization time";
BA_ "SysSignalName" SG_ 1143 ISyncMsgTime "SyncMsgTime";
BA_ "CompuMethodName" SG_ 1399 IIPDIdentityResp "IPDIdentityResp";
BA_ "ISignalName" SG_ 1399 IIPDIdentityResp "IIPDIdentityResp";
BA_ "LongName" SG_ 1399 IIPDIdentityResp "IPD Identification Response";
BA_ "SysSignalName" SG_ 1399 IIPDIdentityResp "IPDIdentityResp";
BA_ "CompuMethodName" SG_ 1526 IIPDComKeyEnbResp "IPDComKeyEnbResp";
BA_ "ISignalName" SG_ 1526 IIPDComKeyEnbResp "IIPDComKeyEnbResp";
BA_ "LongName" SG_ 1526 IIPDComKeyEnbResp "IPD Communication Key Enable Response";
BA_ "SysSignalName" SG_ 1526 IIPDComKeyEnbResp "IPDComKeyEnbResp";
BA_ "CompuMethodName" SG_ 1526 IRemParkngMapChosenresp "RemParkngMapChosenresp";
BA_ "ISignalName" SG_ 1526 IRemParkngMapChosenresp "IRemParkngMapChosenresp";
BA_ "LongName" SG_ 1526 IRemParkngMapChosenresp "response for remember parking map choosen";
BA_ "SysSignalName" SG_ 1526 IRemParkngMapChosenresp "RemParkngMapChosenresp";
BA_ "CompuMethodName" SG_ 1526 IAIParkngRespICB "AIParkngRespICB";
BA_ "ISignalName" SG_ 1526 IAIParkngRespICB "IAIParkngRespICB";
BA_ "LongName" SG_ 1526 IAIParkngRespICB "AIParking Function Response";
BA_ "SysSignalName" SG_ 1526 IAIParkngRespICB "AIParkngRespICB";
BA_ "CompuMethodName" SG_ 1202 IIPD_NM_BSMtoRMS_BKPCANFD "IPD_NM_BSMtoRMS_BKPCANFD";
BA_ "ISignalName" SG_ 1202 IIPD_NM_BSMtoRMS_BKPCANFD "IIPD_NM_BSMtoRMS_BKPCANFD";
BA_ "LongName" SG_ 1202 IIPD_NM_BSMtoRMS_BKPCANFD "IPD_NM_BSMtoRMS_BKPCANFD";
BA_ "SysSignalName" SG_ 1202 IIPD_NM_BSMtoRMS_BKPCANFD "IPD_NM_BSMtoRMS_BKPCANFD";
BA_ "CompuMethodName" SG_ 1202 IIPD_NM_PBSMtoRMS_BKPCANFD "IPD_NM_PBSMtoRMS_BKPCANFD";
BA_ "ISignalName" SG_ 1202 IIPD_NM_PBSMtoRMS_BKPCANFD "IIPD_NM_PBSMtoRMS_BKPCANFD";
BA_ "LongName" SG_ 1202 IIPD_NM_PBSMtoRMS_BKPCANFD "IPD_NM_PBSMtoRMS_BKPCANFD";
BA_ "SysSignalName" SG_ 1202 IIPD_NM_PBSMtoRMS_BKPCANFD "IPD_NM_PBSMtoRMS_BKPCANFD";
BA_ "CompuMethodName" SG_ 1202 IIPD_NM_RMStoNOS_BKPCANFD "IPD_NM_RMStoNOS_BKPCANFD";
BA_ "ISignalName" SG_ 1202 IIPD_NM_RMStoNOS_BKPCANFD "IIPD_NM_RMStoNOS_BKPCANFD";
BA_ "LongName" SG_ 1202 IIPD_NM_RMStoNOS_BKPCANFD "IPD_NM_RMStoNOS_BKPCANFD";
BA_ "SysSignalName" SG_ 1202 IIPD_NM_RMStoNOS_BKPCANFD "IPD_NM_RMStoNOS_BKPCANFD";
BA_ "CompuMethodName" SG_ 1202 IIPD_NM_RSStoNOS_BKPCANFD "IPD_NM_RSStoNOS_BKPCANFD";
BA_ "ISignalName" SG_ 1202 IIPD_NM_RSStoNOS_BKPCANFD "IIPD_NM_RSStoNOS_BKPCANFD";
BA_ "LongName" SG_ 1202 IIPD_NM_RSStoNOS_BKPCANFD "IPD_NM_RSStoNOS_BKPCANFD";
BA_ "SysSignalName" SG_ 1202 IIPD_NM_RSStoNOS_BKPCANFD "IPD_NM_RSStoNOS_BKPCANFD";
BA_ "CompuMethodName" SG_ 1202 IIPD_NM_RSStoRMS_BKPCANFD "IPD_NM_RSStoRMS_BKPCANFD";
BA_ "ISignalName" SG_ 1202 IIPD_NM_RSStoRMS_BKPCANFD "IIPD_NM_RSStoRMS_BKPCANFD";
BA_ "LongName" SG_ 1202 IIPD_NM_RSStoRMS_BKPCANFD "IPD_NM_RSStoRMS_BKPCANFD";
BA_ "SysSignalName" SG_ 1202 IIPD_NM_RSStoRMS_BKPCANFD "IPD_NM_RSStoRMS_BKPCANFD";
BA_ "CompuMethodName" SG_ 1202 IIPD_NM_NOStoRMS_BKPCANFD "IPD_NM_NOStoRMS_BKPCANFD";
BA_ "ISignalName" SG_ 1202 IIPD_NM_NOStoRMS_BKPCANFD "IIPD_NM_NOStoRMS_BKPCANFD";
BA_ "LongName" SG_ 1202 IIPD_NM_NOStoRMS_BKPCANFD "IPD_NM_NOStoRMS_BKPCANFD";
BA_ "SysSignalName" SG_ 1202 IIPD_NM_NOStoRMS_BKPCANFD "IPD_NM_NOStoRMS_BKPCANFD";
BA_ "CompuMethodName" SG_ 1202 IIPD_NM_NOSSta_BKPCANFD "IPD_NM_NOSSta_BKPCANFD";
BA_ "ISignalName" SG_ 1202 IIPD_NM_NOSSta_BKPCANFD "IIPD_NM_NOSSta_BKPCANFD";
BA_ "LongName" SG_ 1202 IIPD_NM_NOSSta_BKPCANFD "IPD_NM_NOSSta_BKPCANFD";
BA_ "SysSignalName" SG_ 1202 IIPD_NM_NOSSta_BKPCANFD "IPD_NM_NOSSta_BKPCANFD";
BA_ "CompuMethodName" SG_ 1202 IIPD_NM_RMSSta_BKPCANFD "IPD_NM_RMSSta_BKPCANFD";
BA_ "ISignalName" SG_ 1202 IIPD_NM_RMSSta_BKPCANFD "IIPD_NM_RMSSta_BKPCANFD";
BA_ "LongName" SG_ 1202 IIPD_NM_RMSSta_BKPCANFD "IPD_NM_RMSSta_BKPCANFD";
BA_ "SysSignalName" SG_ 1202 IIPD_NM_RMSSta_BKPCANFD "IPD_NM_RMSSta_BKPCANFD";
BA_ "CompuMethodName" SG_ 1202 IIPD_NWI_BKPCANFD "IPD_NWI_BKPCANFD";
BA_ "ISignalName" SG_ 1202 IIPD_NWI_BKPCANFD "IIPD_NWI_BKPCANFD";
BA_ "LongName" SG_ 1202 IIPD_NWI_BKPCANFD "IPD BKPCANFD Network_Wakeup_Indication";
BA_ "SysSignalName" SG_ 1202 IIPD_NWI_BKPCANFD "IPD_NWI_BKPCANFD";
BA_ "CompuMethodName" SG_ 1202 IIPD_NOI_BKPCANFD "IPD_NOI_BKPCANFD";
BA_ "ISignalName" SG_ 1202 IIPD_NOI_BKPCANFD "IIPD_NOI_BKPCANFD";
BA_ "LongName" SG_ 1202 IIPD_NOI_BKPCANFD "IPD BKPCANFD Network Operation Indication";
BA_ "SysSignalName" SG_ 1202 IIPD_NOI_BKPCANFD "IPD_NOI_BKPCANFD";
BA_ "CompuMethodName" SG_ 1202 IIPD_NKI_BKPCANFD "IPD_NKI_BKPCANFD";
BA_ "ISignalName" SG_ 1202 IIPD_NKI_BKPCANFD "IIPD_NKI_BKPCANFD";
BA_ "LongName" SG_ 1202 IIPD_NKI_BKPCANFD "IPD BKPCANFD Network Keep Indication";
BA_ "SysSignalName" SG_ 1202 IIPD_NKI_BKPCANFD "IPD_NKI_BKPCANFD";
BA_ "CompuMethodName" SG_ 705 IRASysSts "RASysSts";
BA_ "ISignalName" SG_ 705 IRASysSts "IRASysSts";
BA_ "LongName" SG_ 705 IRASysSts "Reverse Assist Systerm Status";
BA_ "SysSignalName" SG_ 705 IRASysSts "RASysSts";
BA_ "CompuMethodName" SG_ 705 IHWPEMStsForEdr "HWPEMStsForEdr";
BA_ "ISignalName" SG_ 705 IHWPEMStsForEdr "IHWPEMStsForEdr";
BA_ "LongName" SG_ 705 IHWPEMStsForEdr "L3 Function Emergency mode Status For Edr";
BA_ "SysSignalName" SG_ 705 IHWPEMStsForEdr "HWPEMStsForEdr";
BA_ "CompuMethodName" SG_ 705 IHWPEMSts "HWPEMSts";
BA_ "ISignalName" SG_ 705 IHWPEMSts "IHWPEMSts";
BA_ "LongName" SG_ 705 IHWPEMSts "HWP Function Emergency mode Status";
BA_ "SysSignalName" SG_ 705 IHWPEMSts "HWPEMSts";
VAL_ 746 IFCTSysSelReq 0 "FCTSysSelReq_0_no_request" 1 "FCTSysSelReq_1_driver_switch_FCTA_off_request" 2 "FCTSysSelReq_2_driver_switch_FCTA_on_request" 3 "FCTSysSelReq_3_driver_switch_FCTB__FCTA__on_request";
VAL_ 368 ICCSpdDecAndIncVcCmd 0 "CCSpdDecAndIncVcCmd_0_NoRequest" 1 "CCSpdDecAndIncVcCmd_1_SpeedDecrease" 2 "CCSpdDecAndIncVcCmd_2_SpeedIncrease" 3 "CCSpdDecAndIncVcCmd_3_reserved";
VAL_ 368 ICCDisDecAndIncVcCmd 0 "CCDisDecAndIncVcCmd_0_NoRequest" 1 "CCDisDecAndIncVcCmd_1_DistanceDecrease" 2 "CCDisDecAndIncVcCmd_2_DistanceIncrease" 3 "CCDisDecAndIncVcCmd_3_reserved";
VAL_ 368 ICCSwStsSetSwA 0 "CCSwStsSetSwA_0_False" 1 "CCSwStsSetSwA_1_True";
VAL_ 368 ICCSwStsCCASwA 0 "CCSwStsCCASwA_0_False" 1 "CCSwStsCCASwA_1_True";
VAL_ 368 ICCSpdVcCmdSwReq 0 "CCSpdVcCmdSwReq_0_NoRequest" 1 "CCSpdVcCmdSwReq_1_off" 2 "CCSpdVcCmdSwReq_2_on" 3 "CCSpdVcCmdSwReq_3_reserved";
VAL_ 368 ICCDisAdjtVcCmd 0 "CCDisAdjtVcCmd_0_NoRequest" 1 "CCDisAdjtVcCmd_1_Distance1" 2 "CCDisAdjtVcCmd_2_Distance2" 3 "CCDisAdjtVcCmd_3_Distance3" 4 "CCDisAdjtVcCmd_4_Distance4" 5 "CCDisAdjtVcCmd_5_Distance5";
VAL_ 1111 IICCPCBTemp1 255 "ICCPCBTemp1_255_Invalid_Value";
VAL_ 1111 IICCPCBTemp2 255 "ICCPCBTemp2_255_Invalid_Value";
VAL_ 1111 IICCPCBTemp3 255 "ICCPCBTemp3_255_Invalid_Value";
VAL_ 1111 IICCPCBTemp4 255 "ICCPCBTemp4_255_Invalid_Value";
VAL_ 1111 IICCPCBTemp5 255 "ICCPCBTemp5_255_Invalid_Value";
VAL_ 1111 IICCThermalCoolingLvl 0 "ICCThermalCoolingLvl_0_abnormal" 1 "ICCThermalCoolingLvl_1_Thermal_Cooling_level_1" 2 "ICCThermalCoolingLvl_2_Thermal_Cooling_level_2" 3 "ICCThermalCoolingLvl_3_Thermal_Cooling_level_3" 4 "ICCThermalCoolingLvl_4_Thermal_Cooling_level_4" 5 "ICCThermalCoolingLvl_5_reserved" 6 "ICCThermalCoolingLvl_6_reserved" 7 "ICCThermalCoolingLvl_7_reserved" 8 "ICCThermalCoolingLvl_8_reserved" 9 "ICCThermalCoolingLvl_9_reserved" 10 "ICCThermalCoolingLvl_10_reserved" 11 "ICCThermalCoolingLvl_11_reserved" 12 "ICCThermalCoolingLvl_12_reserved" 13 "ICCThermalCoolingLvl_13_reserved" 14 "ICCThermalCoolingLvl_14_reserved" 15 "ICCThermalCoolingLvl_15_reserved";
VAL_ 1111 IFICMV2XEnEnbReq 0 "FICMV2XEnEnbReq_0_Default" 1 "FICMV2XEnEnbReq_1_Enable" 2 "FICMV2XEnEnbReq_2_Disable";
VAL_ 1111 IITMSTripBookReq 0 "ITMSTripBookReq_0_Default" 1 "ITMSTripBookReq_1_TripBookON" 2 "ITMSTripBookReq_2_TripBookOFF";
VAL_ 712 INrwroadFwdBtnDsp 0 "NrwroadFwdBtnDsp_0_unavailable" 1 "NrwroadFwdBtnDsp_1_passive" 2 "NrwroadFwdBtnDsp_2_postive" 3 "NrwroadFwdBtnDsp_3_Reserved";
VAL_ 712 INrwroadFwdDsp 0 "NrwroadFwdDsp_0_Reserved0" 1 "NrwroadFwdDsp_1_Reserved1" 2 "NrwroadFwdDsp_2_Reserved2" 3 "NrwroadFwdDsp_3_Reserved3" 4 "NrwroadFwdDsp_4_Reserved4" 5 "NrwroadFwdDsp_5_Reserved5" 6 "NrwroadFwdDsp_6_Reserved6" 7 "NrwroadFwdDsp_7_Reserved7" 8 "NrwroadFwdDsp_8_Reserved8" 9 "NrwroadFwdDsp_9_Reserved9" 10 "NrwroadFwdDsp_10_Reserved10" 11 "NrwroadFwdDsp_11_Reserved11" 12 "NrwroadFwdDsp_12_Reserved12" 13 "NrwroadFwdDsp_13_Reserved13" 14 "NrwroadFwdDsp_14_Reserved14" 15 "NrwroadFwdDsp_15_Reserved15" 16 "NrwroadFwdDsp_16_Reserved16" 17 "NrwroadFwdDsp_17_Reserved17" 18 "NrwroadFwdDsp_18_Reserved18" 19 "NrwroadFwdDsp_19_Reserved19" 20 "NrwroadFwdDsp_20_Reserved20" 21 "NrwroadFwdDsp_21_Reserved21" 22 "NrwroadFwdDsp_22_Reserved22" 23 "NrwroadFwdDsp_23_Reserved23" 24 "NrwroadFwdDsp_24_Reserved24" 25 "NrwroadFwdDsp_25_Reserved25" 26 "NrwroadFwdDsp_26_Reserved26" 27 "NrwroadFwdDsp_27_Reserved27" 28 "NrwroadFwdDsp_28_Reserved28" 29 "NrwroadFwdDsp_29_Reserved29" 30 "NrwroadFwdDsp_30_Reserved30" 31 "NrwroadFwdDsp_31_Reserved31";
VAL_ 712 INrwroadFwdCndNotSt 0 "NrwroadFwdCndNotSt_0_Reserved0" 1 "NrwroadFwdCndNotSt_1_Reserved1" 2 "NrwroadFwdCndNotSt_2_Reserved2" 3 "NrwroadFwdCndNotSt_3_Reserved3" 4 "NrwroadFwdCndNotSt_4_Reserved4" 5 "NrwroadFwdCndNotSt_5_Reserved5" 6 "NrwroadFwdCndNotSt_6_Reserved6" 7 "NrwroadFwdCndNotSt_7_Reserved7" 8 "NrwroadFwdCndNotSt_8_Reserved8" 9 "NrwroadFwdCndNotSt_9_Reserved9" 10 "NrwroadFwdCndNotSt_10_Reserved10" 11 "NrwroadFwdCndNotSt_11_Reserved11" 12 "NrwroadFwdCndNotSt_12_Reserved12" 13 "NrwroadFwdCndNotSt_13_Reserved13" 14 "NrwroadFwdCndNotSt_14_Reserved14" 15 "NrwroadFwdCndNotSt_15_Reserved15" 16 "NrwroadFwdCndNotSt_16_Reserved16" 17 "NrwroadFwdCndNotSt_17_Reserved17" 18 "NrwroadFwdCndNotSt_18_Reserved18" 19 "NrwroadFwdCndNotSt_19_Reserved19" 20 "NrwroadFwdCndNotSt_20_Reserved20" 21 "NrwroadFwdCndNotSt_21_Reserved21" 22 "NrwroadFwdCndNotSt_22_Reserved22" 23 "NrwroadFwdCndNotSt_23_Reserved23" 24 "NrwroadFwdCndNotSt_24_Reserved24" 25 "NrwroadFwdCndNotSt_25_Reserved25" 26 "NrwroadFwdCndNotSt_26_Reserved26" 27 "NrwroadFwdCndNotSt_27_Reserved27" 28 "NrwroadFwdCndNotSt_28_Reserved28" 29 "NrwroadFwdCndNotSt_29_Reserved29" 30 "NrwroadFwdCndNotSt_30_Reserved30" 31 "NrwroadFwdCndNotSt_31_Reserved31";
VAL_ 712 IMemParkingCrsScrnReq 0 "MemParkingCrsScrnReq_0_Norequest" 1 "MemParkingCrsScrnReq_1_Request";
VAL_ 712 INrwroadFwdDstTostDsp 0 "NrwroadFwdDstTostDsp_0_Unavialable" 1 "NrwroadFwdDstTostDsp_1_RecommendedRelease" 2 "NrwroadFwdDstTostDsp_2_StartRelease" 3 "NrwroadFwdDstTostDsp_3_SuspendRelease" 4 "NrwroadFwdDstTostDsp_4_ResumeRelease" 5 "NrwroadFwdDstTostDsp_5_QuitRelease" 6 "NrwroadFwdDstTostDsp_6_Reserved6" 7 "NrwroadFwdDstTostDsp_7_Reserved7" 8 "NrwroadFwdDstTostDsp_8_Reserved8" 9 "NrwroadFwdDstTostDsp_9_Reserved9" 10 "NrwroadFwdDstTostDsp_10_Reserved10" 11 "NrwroadFwdDstTostDsp_11_Reserved11" 12 "NrwroadFwdDstTostDsp_12_Reserved12" 13 "NrwroadFwdDstTostDsp_13_Reserved13" 14 "NrwroadFwdDstTostDsp_14_Reserved14" 15 "NrwroadFwdDstTostDsp_15_Reserved15";
VAL_ 712 INrwroadFwdSwSts 0 "NrwroadFwdSwSts_0_Unavaliable" 1 "NrwroadFwdSwSts_1_Off" 2 "NrwroadFwdSwSts_2_On" 3 "NrwroadFwdSwSts_3_Reserve";
VAL_ 712 INrwroadFwdDst360Req 0 "NrwroadFwdDst360Req_0_NoRequest" 1 "NrwroadFwdDst360Req_1_Request" 2 "NrwroadFwdDst360Req_2_Quit" 3 "NrwroadFwdDst360Req_3_Hold" 4 "NrwroadFwdDst360Req_4_Reserved4" 5 "NrwroadFwdDst360Req_5_Reserved5" 6 "NrwroadFwdDst360Req_6_Reserved6" 7 "NrwroadFwdDst360Req_7_Reserved7";
VAL_ 712 INrwroadFwdDstBtnDsp 0 "NrwroadFwdDstBtndsp_0_Unavialable" 1 "NrwroadFwdDstBtndsp_1_Highlight" 2 "NrwroadFwdDstBtndsp_2_Flashing" 3 "NrwroadFwdDstBtndsp_3_Hide" 4 "NrwroadFwdDstBtndsp_4_Reserved4" 5 "NrwroadFwdDstBtndsp_5_Reserved5" 6 "NrwroadFwdDstBtndsp_6_Reserved6" 7 "NrwroadFwdDstBtndsp_7_Reserved7";
VAL_ 710 ISpedRegulaModSwSts 0 "SpedRegulaModSwSts_0_unavaliable" 1 "SpedRegulaModSwSts_1_switch_on" 2 "SpedRegulaModSwSts_2_switch_off" 3 "SpedRegulaModSwSts_3_switch_hide" 4 "SpedRegulaModSwSts_4_Reserved" 5 "SpedRegulaModSwSts_5_Reserved" 6 "SpedRegulaModSwSts_6_Reserved" 7 "SpedRegulaModSwSts_7_Reserved";
VAL_ 710 IMemoryRouteSaveCancelRsp 0 "MemoryRouteSaveCancelRsp_0_no_request" 1 "MemoryRouteSaveCancelRsp_1_ON_request" 2 "MemoryRouteSaveCancelRsp_2_OFF_request" 3 "MemoryRouteSaveCancelRsp_3_Reserved" 4 "MemoryRouteSaveCancelRsp_4_Reserved" 5 "MemoryRouteSaveCancelRsp_5_Reserved" 6 "MemoryRouteSaveCancelRsp_6_Reserved" 7 "MemoryRouteSaveCancelRsp_7_Reserved";
VAL_ 710 ILDWAudiAlmReq 0 "LDWAudiAlmReq_0__0" 1 "LDWAudiAlmReq_1__1" 2 "LDWAudiAlmReq_2__2" 3 "LDWAudiAlmReq_3__3" 4 "LDWAudiAlmReq_4__4" 5 "LDWAudiAlmReq_5__5" 6 "LDWAudiAlmReq_6__6" 7 "LDWAudiAlmReq_7__7";
VAL_ 710 IELKSwStsHid 0 "ELKSwStsHid_0__0" 1 "ELKSwStsHid_1__1" 2 "ELKSwStsHid_2__2" 3 "ELKSwStsHid_3__3";
VAL_ 710 IELKIndiDisp 0 "ELKIndiDisp_0__0" 1 "ELKIndiDisp_1__1" 2 "ELKIndiDisp_2__2" 3 "ELKIndiDisp_3__3" 4 "ELKIndiDisp_4__4" 5 "ELKIndiDisp_5__5" 6 "ELKIndiDisp_6__6" 7 "ELKIndiDisp_7__7";
VAL_ 710 IMemParkngSwSts 0 "MemParkngSwSts_0_Unavaliable" 1 "MemParkngSwSts_1_Off" 2 "MemParkngSwSts_2_On" 3 "MemParkngSwSts_3_Reserve";
VAL_ 710 IRADSSwSts 0 "RADSSwSts_0_Unavaliable" 1 "RADSSwSts_1_Off" 2 "RADSSwSts_2_On" 3 "RADSSwSts_3_Reserve";
VAL_ 706 IPDSysKeyPsAvlbl 0 "PDSysKeyPsAvlbl_0_Invalid" 1 "PDSysKeyPsAvlbl_1_Valid";
VAL_ 706 IMemParkingReserveIPD5 0 "MemParkingReserveIPD5_0_1" 1 "MemParkingReserveIPD5_1_2" 2 "MemParkingReserveIPD5_2_3" 3 "MemParkingReserveIPD5_3_4" 4 "MemParkingReserveIPD5_4_5" 5 "MemParkingReserveIPD5_5_6" 6 "MemParkingReserveIPD5_6_7" 7 "MemParkingReserveIPD5_7_8" 8 "MemParkingReserveIPD5_8_9" 9 "MemParkingReserveIPD5_9_10" 10 "MemParkingReserveIPD5_10_11" 11 "MemParkingReserveIPD5_11_12" 12 "MemParkingReserveIPD5_12_13" 13 "MemParkingReserveIPD5_13_14" 14 "MemParkingReserveIPD5_14_15" 15 "MemParkingReserveIPD5_15_16";
VAL_ 706 IMemParkingReserveIPD4 0 "MemParkingReserveIPD4_0_1" 1 "MemParkingReserveIPD4_1_2" 2 "MemParkingReserveIPD4_2_3" 3 "MemParkingReserveIPD4_3_4" 4 "MemParkingReserveIPD4_4_5" 5 "MemParkingReserveIPD4_5_6" 6 "MemParkingReserveIPD4_6_7" 7 "MemParkingReserveIPD4_7_8" 8 "MemParkingReserveIPD4_8_9" 9 "MemParkingReserveIPD4_9_10" 10 "MemParkingReserveIPD4_10_11" 11 "MemParkingReserveIPD4_11_12" 12 "MemParkingReserveIPD4_12_13" 13 "MemParkingReserveIPD4_13_14" 14 "MemParkingReserveIPD4_14_15" 15 "MemParkingReserveIPD4_15_16";
VAL_ 706 IMemParkingReserveIPD2 0 "MemParkingReserveIPD2_0_1" 1 "MemParkingReserveIPD2_1_2" 2 "MemParkingReserveIPD2_2_3" 3 "MemParkingReserveIPD2_3_4";
VAL_ 706 IMemParkingReserveIPD1 0 "MemParkingReserveIPD1_0_1" 1 "MemParkingReserveIPD1_1_2" 2 "MemParkingReserveIPD1_2_3" 3 "MemParkingReserveIPD1_3_4";
VAL_ 706 IMemParkingReserveIPD6 0 "MemParkingReserveIPD6_0_1" 1 "MemParkingReserveIPD6_1_2" 2 "MemParkingReserveIPD6_2_3" 3 "MemParkingReserveIPD6_3_4" 4 "MemParkingReserveIPD6_4_5" 5 "MemParkingReserveIPD6_5_6" 6 "MemParkingReserveIPD6_6_7" 7 "MemParkingReserveIPD6_7_8" 8 "MemParkingReserveIPD6_8_9" 9 "MemParkingReserveIPD6_9_10" 10 "MemParkingReserveIPD6_10_11" 11 "MemParkingReserveIPD6_11_12" 12 "MemParkingReserveIPD6_12_13" 13 "MemParkingReserveIPD6_13_14" 14 "MemParkingReserveIPD6_14_15" 15 "MemParkingReserveIPD6_15_16";
VAL_ 706 IMemParkingReserveIPD3 0 "MemParkingReserveIPD3_0_1" 1 "MemParkingReserveIPD3_1_2" 2 "MemParkingReserveIPD3_2_3" 3 "MemParkingReserveIPD3_3_4";
VAL_ 844 IMemParkngSilentPatrolSwSts 0 "MemParkngSilentPatrolSwSts_0_NoRequest" 1 "MemParkngSilentPatrolSwSts_1_ON" 2 "MemParkngSilentPatrolSwSts_2_OFF" 3 "MemParkngSilentPatrolSwSts_3_Reserved";
VAL_ 844 IHODMdlSts 0 "HODMdlSts_0_no_request" 1 "HODMdlSts_1_Standard" 2 "HODMdlSts_2_Comfortable" 3 "HODMdlSts_3_Reserved";
VAL_ 844 ITgtParkingFavorite 0 "TgtParkingFavorite_0_NoFavorite" 1 "TgtParkingFavorite_1_FavoriteId1" 2 "TgtParkingFavorite_2_FavoriteId2" 3 "TgtParkingFavorite_3_FavoriteId3" 4 "TgtParkingFavorite_4_FavoriteId4" 5 "TgtParkingFavorite_5_FavoriteId5" 6 "TgtParkingFavorite_6_FavoriteId6" 7 "TgtParkingFavorite_7_FavoriteId7" 8 "TgtParkingFavorite_8_FavoriteId8" 9 "TgtParkingFavorite_9_FavoriteId9" 10 "TgtParkingFavorite_10_FavoriteId10" 11 "TgtParkingFavorite_11_FavoriteId11" 12 "TgtParkingFavorite_12_FavoriteId12" 13 "TgtParkingFavorite_13_Reserved1" 14 "TgtParkingFavorite_14_Reserved2" 15 "TgtParkingFavorite_15_Reserved3";
VAL_ 844 IIPDWtrClntInltFlwReq 0 "IPDWtrClntInltFlwReq_0_1_L_min" 1 "IPDWtrClntInltFlwReq_1_2_L_min" 2 "IPDWtrClntInltFlwReq_2_3_L_min" 3 "IPDWtrClntInltFlwReq_3_4_L_min" 4 "IPDWtrClntInltFlwReq_4_5_L_min" 5 "IPDWtrClntInltFlwReq_5_6_L_min" 6 "IPDWtrClntInltFlwReq_6_7_L_min" 7 "IPDWtrClntInltFlwReq_7_8_L_min" 8 "IPDWtrClntInltFlwReq_8_9_L_min" 9 "IPDWtrClntInltFlwReq_9_10_L_min" 10 "IPDWtrClntInltFlwReq_10_11_L_min" 11 "IPDWtrClntInltFlwReq_11_12_L_min" 12 "IPDWtrClntInltFlwReq_12_16_L_min" 13 "IPDWtrClntInltFlwReq_13_Reserved0" 14 "IPDWtrClntInltFlwReq_14_Reserved1" 15 "IPDWtrClntInltFlwReq_15_SysMax";
VAL_ 844 IMemParkngBtnRcnmRsp 0 "MemParkngBtnRcnmRsp_0_Reserved1" 1 "MemParkngBtnRcnmRsp_1_Reserved2" 2 "MemParkngBtnRcnmRsp_2_SavePathRsp" 3 "MemParkngBtnRcnmRsp_3_SavePathAPARsp" 4 "MemParkngBtnRcnmRsp_4_SavePathSilentRsp" 5 "MemParkngBtnRcnmRsp_5_Reserved" 6 "MemParkngBtnRcnmRsp_6_Reserved" 7 "MemParkngBtnRcnmRsp_7_Reserved";
VAL_ 844 IAVPMapDownloadFailReason 0 "AVPMapDownloadFailReason_0_Reserve" 1 "AVPMapDownloadFailReason_1_Reserve" 2 "AVPMapDownloadFailReason_2_Reserve" 3 "AVPMapDownloadFailReason_3_Reserve" 4 "AVPMapDownloadFailReason_4_Reserve" 5 "AVPMapDownloadFailReason_5_Reserve" 6 "AVPMapDownloadFailReason_6_Reserve" 7 "AVPMapDownloadFailReason_7_Reserve";
VAL_ 844 IIPDPowerFailSwSts 0 "IPDPowerFailSwSts_0_unavailable" 1 "IPDPowerFailSwSts_1_IPD_off" 2 "IPDPowerFailSwSts_2_IPD_on" 3 "IPDPowerFailSwSts_3_Reserved";
VAL_ 844 IAVPMapRutMgtSts 0 "AVPMapRutMgtSts_0_Unavaliable" 1 "AVPMapRutMgtSts_1_Off" 2 "AVPMapRutMgtSts_2_On" 3 "AVPMapRutMgtSts_3_Reserve";
VAL_ 844 IAVPUpdateMapCancelRsp 0 "AVPUpdateMapCancelRsp_0_Failed" 1 "AVPUpdateMapCancelRsp_1_Success";
VAL_ 844 IAVPTagResp 0 "AVPTagResp_0_fail" 1 "AVPTagResp_1_success";
VAL_ 844 IAVPTagSts 0 "AVPTagSts_0_NotAvailable" 1 "AVPTagSts_1_Available";
VAL_ 844 ISpdLmtOfstSetNumResp 0 "SpdLmtOfstSetNumResp_0_Unavailable" 1 "SpdLmtOfstSetNumResp_1_0_km_h" 2 "SpdLmtOfstSetNumResp_2_5_km_h" 3 "SpdLmtOfstSetNumResp_3_10_km_h" 4 "SpdLmtOfstSetNumResp_4_15_km_h" 5 "SpdLmtOfstSetNumResp_5_20_km_h" 6 "SpdLmtOfstSetNumResp_6__5_km_h" 7 "SpdLmtOfstSetNumResp_7__10_km_h" 8 "SpdLmtOfstSetNumResp_8__15_km_h" 9 "SpdLmtOfstSetNumResp_9__20_km_h" 10 "SpdLmtOfstSetNumResp_10_reserved" 11 "SpdLmtOfstSetNumResp_11_reserved" 12 "SpdLmtOfstSetNumResp_12_reserved" 13 "SpdLmtOfstSetNumResp_13_reserved" 14 "SpdLmtOfstSetNumResp_14_reserved";
VAL_ 844 ITJAICAMsgReq 0 "TJAICAMsgReq_0_NoDisplay" 1 "TJAICAMsgReq_1_hands_on_request" 2 "TJAICAMsgReq_2_wide_lane_left" 3 "TJAICAMsgReq_3_wide_lane_right" 4 "TJAICAMsgReq_4_red_traffic_light_attention" 5 "TJAICAMsgReq_5_override_attention" 6 "TJAICAMsgReq_6_curve_attention" 7 "TJAICAMsgReq_7_reserve" 8 "TJAICAMsgReq_8_reserve" 9 "TJAICAMsgReq_9_reserve" 10 "TJAICAMsgReq_10_reserve" 11 "TJAICAMsgReq_11_reserve" 12 "TJAICAMsgReq_12_reserve" 13 "TJAICAMsgReq_13_reserve" 14 "TJAICAMsgReq_14_reserve" 15 "TJAICAMsgReq_15_reserve" 16 "TJAICAMsgReq_16_reserve" 17 "TJAICAMsgReq_17_reserve" 18 "TJAICAMsgReq_18_reserve" 19 "TJAICAMsgReq_19_reserve" 20 "TJAICAMsgReq_20_reserve" 21 "TJAICAMsgReq_21_reserve" 22 "TJAICAMsgReq_22_reserve" 23 "TJAICAMsgReq_23_reserve" 24 "TJAICAMsgReq_24_reserve" 25 "TJAICAMsgReq_25_reserve" 26 "TJAICAMsgReq_26_reserve" 27 "TJAICAMsgReq_27_reserve" 28 "TJAICAMsgReq_28_reserve" 29 "TJAICAMsgReq_29_reserve" 30 "TJAICAMsgReq_30_reserve" 31 "TJAICAMsgReq_31_reserve";
VAL_ 844 ISpdLmtOfstSetPercResp 0 "SpdLmtOfstSetPercResp_0_Unavailable" 1 "SpdLmtOfstSetPercResp_1_0" 2 "SpdLmtOfstSetPercResp_2_5" 3 "SpdLmtOfstSetPercResp_3_10" 4 "SpdLmtOfstSetPercResp_4_20" 5 "SpdLmtOfstSetPercResp_5__5" 6 "SpdLmtOfstSetPercResp_6__10" 7 "SpdLmtOfstSetPercResp_7__20";
VAL_ 844 IACCStsSw 0 "ACCStsSw_0_unavailable" 1 "ACCStsSw_1_Off" 2 "ACCStsSw_2_On" 3 "ACCStsSw_3_Reserve";
VAL_ 844 IACCSpdLimtSw 0 "ACCSpdLimtSw_0_unavailable" 1 "ACCSpdLimtSw_1_manual" 2 "ACCSpdLimtSw_2_Auto" 3 "ACCSpdLimtSw_3_OFF";
VAL_ 844 ISpdLimitManualSts 0 "SpdLimitManualSts_0_NoRequest" 1 "SpdLimitManualSts_1_manual" 2 "SpdLimitManualSts_2_Reserve" 3 "SpdLimitManualSts_3_Reserve";
VAL_ 844 ICCSpdlVcCmdSwReqDspCmd 0 "CCSpdlVcCmdSwReqDspCmd_0_unavailable" 1 "CCSpdlVcCmdSwReqDspCmd_1_off" 2 "CCSpdlVcCmdSwReqDspCmd_2_on" 3 "CCSpdlVcCmdSwReqDspCmd_3_reserved";
VAL_ 844 ISpdLmtMdMsgReq 0 "SpdLmtMdMsgReq_0_NoDisplay" 1 "SpdLmtMdMsgReq_1_msg1" 2 "SpdLmtMdMsgReq_2_msg2" 3 "SpdLmtMdMsgReq_3_msg3" 4 "SpdLmtMdMsgReq_4_msg4" 5 "SpdLmtMdMsgReq_5_msg5" 6 "SpdLmtMdMsgReq_6_msg6" 7 "SpdLmtMdMsgReq_7_msg7";
VAL_ 755 ILADSInfoDispReqToICM_HPP 0 "LADSInfoDispReqToICM_0_Reserved" 2 "LADSInfoDispReqToICM_2_Vehicle_speed_is_too_high_APA_system_abort" 3 "LADSInfoDispReqToICM_3_Vehicle_speed_is_too_high_please_slow_down" 4 "LADSInfoDispReqToICM_4_Parking_slot_searching" 5 "LADSInfoDispReqToICM_5_Parking_Exit" 7 "LADSInfoDispReqToICM_7_Please_stop_the_car" 9 "LADSInfoDispReqToICM_9_Parking_pause_please_confirm_in_APP" 10 "LADSInfoDispReqToICM_10_Press_start_for_APA_vehicle_control_or_choose_RPA" 11 "LADSInfoDispReqToICM_11_Parking_pause_please_confirm_safety" 12 "LADSInfoDispReqToICM_12_EPB_operated_Parking_exit" 13 "LADSInfoDispReqToICM_13_No_obstacle_park_out_by_yourself" 14 "LADSInfoDispReqToICM_14_Please_press_start_park_out" 15 "LADSInfoDispReqToICM_15_Parking_pause_please_press_continue" 16 "LADSInfoDispReqToICM_16_Please_fasten_the_safety_belt" 17 "LADSInfoDispReqToICM_17_Please_close_the_door" 18 "LADSInfoDispReqToICM_18_LADS_unavailable_parking_exit" 19 "LADSInfoDispReqToICM_19_Left_steering" 22 "LADSInfoDispReqToICM_22_RPA_ready_Please_leave_the_car_and_use_app" 29 "LADSInfoDispReqToICM_29_Right_steering" 30 "LADSInfoDispReqToICM_30_Please_step_on_the_brake_and_press_the_SSB" 33 "LADSInfoDispReqToICM_33_Barrier_exist_please_remove" 34 "LADSInfoDispReqToICM_34_Steering_wheel_has_been_turned" 35 "LADSInfoDispReqToICM_35_Accelerator_pressed" 37 "LADSInfoDispReqToICM_37_Shift_operated" 38 "LADSInfoDispReqToICM_38_Adjustment_time_exceeded" 39 "LADSInfoDispReqToICM_39_Slope_too_big" 40 "LADSInfoDispReqToICM_40_Disturbe_overtime" 41 "LADSInfoDispReqToICM_41_Space_too_small" 44 "LADSInfoDispReqToICM_44_Please_release_brake_and_pay_attention_to_surroundings_using_active_control_measure_if_necessary" 45 "LADSInfoDispReqToICM_45_Parking_is_ongoing" 46 "LADSInfoDispReqToICM_46_Parking_manoeuvre_has_completed_Please_take_over_vehicle" 48 "LADSInfoDispReqToICM_48_System_overtime_APA_system_quit" 63 "LADSInfoDispReqToICM_63_Environment_Changed" 65 "LADSInfoDispReqToICM_65_Please_stop_the_car_first" 66 "LADSInfoDispReqToICM_66_Please_shift_to_P_first" 67 "LADSInfoDispReqToICM_67_Please_apply_the_EPB_first" 68 "LADSInfoDispReqToICM_68_Please_start_the_vehicle" 69 "LADSInfoDispReqToICM_69_Please_unlock_the_vehicle" 70 "LADSInfoDispReqToICM_70_Please_takeover" 97 "LADSInfoDispReqToICM_97_Tire_pressure_abnormal" 98 "LADSInfoDispReqToICM_98_Please_turn_off_the_engine_manually" 99 "LADSInfoDispReqToICM_99_Please_lock_the_vehicle" 100 "LADSInfoDispReqToICM_100_Long_time_not_operated" 101 "LADSInfoDispReqToICM_101_Engine_start_error" 102 "LADSInfoDispReqToICM_102_Hazard_start_error" 103 "LADSInfoDispReqToICM_103_Unlock_failed" 104 "LADSInfoDispReqToICM_104_SSB_pressed" 105 "LADSInfoDispReqToICM_105_Bluetooth_inactive" 106 "LADSInfoDispReqToICM_106_Has_changed_to_normal_drive_mode" 107 "LADSInfoDispReqToICM_107_ACC_actived_LADS_exit" 108 "LADSInfoDispReqToICM_108_AEB_actived_LADS_exit" 109 "LADSInfoDispReqToICM_109_TJA_actived_LADS_exit" 110 "LADSInfoDispReqToICM_110_Locked_the_car" 111 "LADSInfoDispReqToICM_111_Not_choose_RPA" 112 "LADSInfoDispReqToICM_112_APP_exit_please_move_to_FICM" 113 "LADSInfoDispReqToICM_113_Vehicle_does_not_stop" 114 "LADSInfoDispReqToICM_114_Barrier_in_slot_change_another" 128 "LADSInfoDispReqToICM_128_Please_press_the_brake_pedal_vehicle_control_has_not_started" 129 "LADSInfoDispReqToICM_129_Parking_pause_please_press_the_button" 130 "LADSInfoDispReqToICM_130_Detecting_if_the_slot_space_is_enough" 146 "LADSInfoDispReqToICM_146_System_selfchecking" 147 "LADSInfoDispReqToICM_147_Please_select_park_out_direction" 148 "LADSInfoDispReqToICM_148_NRCD_is_ready" 149 "LADSInfoDispReqToICM_149_Parking_pause_please_press_continue_in_APP" 160 "LADSInfoDispReqToICM_160_Engine_is_not_ready" 161 "LADSInfoDispReqToICM_161_LADS_fault_can_not_open" 162 "LADSInfoDispReqToICM_162_LADS_busy_can_not_open" 163 "LADSInfoDispReqToICM_163_Speed_is_too_high_can_not_open" 164 "LADSInfoDispReqToICM_164_Vehicle_is_not_stop_can_not_open" 165 "LADSInfoDispReqToICM_165_ADAS_is_actived" 176 "LADSInfoDispReqToICM_176_Parking_into_Power_swap_station" 177 "LADSInfoDispReqToICM_177_Outside_mirror_is_fold" 178 "LADSInfoDispReqToICM_178_Direction_selection_timeout" 179 "LADSInfoDispReqToICM_179_Single_driving_distance_out_of_limit" 180 "LADSInfoDispReqToICM_180_User_pause_the_parking" 181 "LADSInfoDispReqToICM_181_Vehicle_Blocked" 182 "LADSInfoDispReqToICM_182_Slot_searching_fault" 183 "LADSInfoDispReqToICM_183_Slot_searching_conditions_not_satisfied" 184 "LADSInfoDispReqToICM_184_Parking_conditions_not_satisfied" 185 "LADSInfoDispReqToICM_185_Space_limit" 186 "LADSInfoDispReqToICM_186_Speed_high" 187 "LADSInfoDispReqToICM_187_External_ecu_failure" 188 "LADSInfoDispReqToICM_188_Phone_Low_battery" 189 "LADSInfoDispReqToICM_189_External_esc_active" 190 "LADSInfoDispReqToICM_190_Unsafe_Behavior" 191 "LADSInfoDispReqToICM_191_Airbag_deployed" 192 "LADSInfoDispReqToICM_192_USS_covered" 193 "LADSInfoDispReqToICM_193_AVM_camera_covered" 194 "LADSInfoDispReqToICM_194_Answer_the_phone" 195 "LADSInfoDispReqToICM_195_Engine_Front_Door_Open" 196 "LADSInfoDispReqToICM_196_Cruising_conditions_satisfied" 197 "LADSInfoDispReqToICM_197_Please_select_APA_super_or_RPA_super" 198 "LADSInfoDispReqToICM_198_Shift_N_gear_overtime" 199 "LADSInfoDispReqToICM_199_Please_release_Accelerator" 200 "LADSInfoDispReqToICM_200_Charge_gun_connect_can_not_open" 201 "LADSInfoDispReqToICM_201_Vehicle_low_battery_can_not_open" 202 "LADSInfoDispReqToICM_202_Ramp_too_steep_can_not_open" 203 "LADSInfoDispReqToICM_203_Digital_key_inside_the_car_can_not_open" 204 "LADSInfoDispReqToICM_204_Slot_too_small_Recommend_remote_control" 205 "LADSInfoDispReqToICM_205_Free_parking_slot_available" 206 "LADSInfoDispReqToICM_206_Free_parking_slot_unavailable" 207 "LADSInfoDispReqToICM_207_RPA_is_ongoing_Please_try_later" 208 "LADSInfoDispReqToICM_208_FOTA_is_ongoing_Please_try_later" 209 "LADSInfoDispReqToICM_209_vehicle_is_cold_starting_and__expected_to_take_a_long_time_Thanks_for_your_patience" 210 "LADSInfoDispReqToICM_210_Please_proceed_to_the_memory_path" 211 "LADSInfoDispReqToICM_211_Please_reduce_the_speed" 212 "LADSInfoDispReqToICM_212_Going_too_fast__memory_parking_has_exited" 213 "LADSInfoDispReqToICM_213_Slope_is_too_high__Memory_parking_has_exited" 214 "LADSInfoDispReqToICM_214_Memory_parking_hasexited" 215 "LADSInfoDispReqToICM_215_Please_select_the_parking_space_and_switch_to_P_gear_after_pouring_into_the_parking_space" 216 "LADSInfoDispReqToICM_216_Route_overlaps__Memory_parking_has_exited" 217 "LADSInfoDispReqToICM_217_Door_opens__memory_parking_has_exited" 218 "LADSInfoDispReqToICM_218_Astern_distance_is_too_far__Memory_parking_has_exited" 219 "LADSInfoDispReqToICM_219_Learning_distance_is_about_to_exceed_the_limit" 220 "LADSInfoDispReqToICM_220_Route_learning_distance_exceeded__memory_parking_has_exited" 221 "LADSInfoDispReqToICM_221_Route_learning_timed_out__Memory_parking_has_exited" 222 "LADSInfoDispReqToICM_222_Please_release_the_brake" 223 "LADSInfoDispReqToICM_223_Please_close_the_door_or_trunk" 224 "LADSInfoDispReqToICM_224_Target_space_is_occupied__We_will_be_pulling_into_the_next_space_for_you" 225 "LADSInfoDispReqToICM_225_Switched_to_berthing_en_route" 226 "LADSInfoDispReqToICM_226_Memory_parking_has_exited__please_take_over_the_vehicle";
VAL_ 755 IESSAdoWrnngDspCmd 0 "ESSAdoWrnngDspCmd_0_Unavailable" 1 "ESSAdoWrnngDspCmd_1_off" 2 "ESSAdoWrnngDspCmd_2_on" 3 "ESSAdoWrnngDspCmd_3_reserved";
VAL_ 755 IHPPFnSts 0 "HPPFnSts_0_Default" 1 "HPPFnSts_1_HPP_Map_Learning" 2 "HPPFnSts_2_HPP_Map_Parking_in_Slot_Learning" 3 "HPPFnSts_3_Map_Building_Processing" 4 "HPPFnSts_4_Waiting_to_save" 5 "HPPFnSts_5_HPP_Learning_Complete" 6 "HPPFnSts_6_HPP_Learning_Fail" 7 "HPPFnSts_7_HPP_Cruising_in" 8 "HPPFnSts_8_HPP_Cruising_out" 9 "HPPFnSts_9_HPP_Cruising_Paused" 10 "HPPFnSts_10_HPP_Parking_in" 11 "HPPFnSts_11_HPP_Parking_out" 12 "HPPFnSts_12_HPP_Parking_in_out_Paused" 13 "HPPFnSts_13_HPP_Cruising_Complete" 14 "HPPFnSts_14_HPP_Cruising_Fail" 15 "HPPFnSts_15_Map_Wating_to_Save" 16 "HPPFnSts_16_Reserved0" 17 "HPPFnSts_17_Reserved1" 18 "HPPFnSts_18_Reserved2" 19 "HPPFnSts_19_Reserved3" 20 "HPPFnSts_20_Reserved4" 21 "HPPFnSts_21_Reserved5" 22 "HPPFnSts_22_Reserved6" 23 "HPPFnSts_23_Reserved7" 24 "HPPFnSts_24_Reserved8" 25 "HPPFnSts_25_Reserved9" 26 "HPPFnSts_26_Reserved10" 27 "HPPFnSts_27_Reserved11" 28 "HPPFnSts_28_Reserved12" 29 "HPPFnSts_29_Reserved13" 30 "HPPFnSts_30_Reserved14" 31 "HPPFnSts_31_Reserved15" 32 "HPPFnSts_32_Reserved16" 33 "HPPFnSts_33_Reserved17" 34 "HPPFnSts_34_Reserved18" 35 "HPPFnSts_35_Reserved19" 36 "HPPFnSts_36_Reserved20" 37 "HPPFnSts_37_Reserved21" 38 "HPPFnSts_38_Reserved22" 39 "HPPFnSts_39_Reserved23" 40 "HPPFnSts_40_Reserved24" 41 "HPPFnSts_41_Reserved25" 42 "HPPFnSts_42_Reserved26" 43 "HPPFnSts_43_Reserved27" 44 "HPPFnSts_44_Reserved28" 45 "HPPFnSts_45_Reserved29" 46 "HPPFnSts_46_Reserved30" 47 "HPPFnSts_47_Reserved31" 48 "HPPFnSts_48_Reserved32" 49 "HPPFnSts_49_Reserved33" 50 "HPPFnSts_50_Reserved34" 51 "HPPFnSts_51_Reserved35" 52 "HPPFnSts_52_Reserved36" 53 "HPPFnSts_53_Reserved37" 54 "HPPFnSts_54_Reserved38" 55 "HPPFnSts_55_Reserved39" 56 "HPPFnSts_56_Reserved40" 57 "HPPFnSts_57_Reserved41" 58 "HPPFnSts_58_Reserved42" 59 "HPPFnSts_59_Reserved43" 60 "HPPFnSts_60_Reserved44" 61 "HPPFnSts_61_Reserved45" 62 "HPPFnSts_62_Reserved46" 63 "HPPFnSts_63_Reserved47";
VAL_ 755 IHPPInBmtSts 0 "HPPInBmtSts_0_Not_In_Basement" 1 "HPPInBmtSts_1_In_Basement";
VAL_ 755 IESSDspCmd 0 "ESSSwDspCmd_0_Unavailable" 1 "ESSSwDspCmd_1_Off" 2 "ESSSwDspCmd_2_On" 3 "AESSwDspCmd_3_On";
VAL_ 755 INOACitySysMsg 0 "NOACitySysMsg_0_No_display" 1 "NOACitySysMsg_1_PleaseNoticeTrafficLightAhead" 2 "NOACitySysMsg_2_About_to_TurnLeft" 3 "NOACitySysMsg_3_About_to_TurnRight" 4 "NOACitySysMsg_4_About_to_TurnAround" 5 "NOACitySysMsg_5_EnteringBusLane" 6 "NOACitySysMsg_6_EnteringReversibleLane" 7 "NOACitySysMsg_7_DecelerationToStop" 8 "NOACitySysMsg_8_WaitToStart" 9 "NOACitySysMsg_9_GreenLightToStart" 10 "NOACitySysMsg_10_GoStraightThroughIntersection" 11 "NOACitySysMsg_11_TOR_DifficultToUturn" 12 "NOACitySysMsg_12_EnteringWaitingArea" 13 "NOACitySysMsg_13_LongQuequeAtIntersection" 14 "NOACitySysMsg_14_YieldVRU" 15 "NOACitySysMsg_15_NoParkingArea" 16 "NOACitySysMsg_16_About_to_EnterRoundabout" 17 "NOACitySysMsg_17_About_to_DriveOutRoundabout" 18 "NOACitySysMsg_18_About_to_Detour" 19 "NOACitySysMsg_19_Detouring" 20 "NOACitySysMsg_20_CompleteDetour" 21 "NOACitySysMsg_21_FailtoDetour" 22 "NOACitySysMsg_22_LanechangeForDetouring" 23 "NOACitySysMsg_23_MergelaneAndPassInSequence" 24 "NOACitySysMsg_24_PleaseAssistCNOAWithAccelerateSlightly" 25 "NOACitySysMsg_25_PleaseAssistCNOAWithTurnSteeringWheelSlightly" 26 "NOACitySysMsg_26_TrafficPolice_PleaseTOR" 27 "NOACitySysMsg_27_About_to_EnterMainRoad" 28 "NOACitySysMsg_28_About_to_EnterReliefRoad" 29 "NOACitySysMsg_29_About_to_DetourInOppositeLane" 30 "NOACitySysMsg_30_EnteringTidalLane" 31 "NOACitySysMsg_31_About_to_EnterMTC" 32 "NOACitySysMsg_32_About_to_EnterETC" 33 "NOACitySysMsg_33_Reserved" 34 "NOACitySysMsg_34_Reserved" 35 "NOACitySysMsg_35_Gate_arm_raised_D2D" 36 "NOACitySysMsg_36_Turnstile_wait_timeout_D2D" 37 "NOACitySysMsg_37_About_to_go_through_the_gate_D2D";
VAL_ 755 IFLSUSSSts 0 "FLSUSSSts_0_Normal" 1 "FLSUSSSts_1_Fault" 2 "FLSUSSSts_2_Blind";
VAL_ 755 INOPSysMsg 0 "NOPSysMsg_0_No_display" 1 "NOPSysMsg_1_NOP_not_available" 2 "NOPSysMsg_2_Please_hold_steering_wheel" 3 "NOPSysMsg_3_Please_control_steering_wheel" 4 "NOPSysMsg_4_Please_take_over_control_of_vehicle" 5 "NOPSysMsg_5_Approaching_unreleased_highway_section" 6 "NOPSysMsg_6_A_lane_markings_not_present" 7 "NOPSysMsg_7_Road_condition_insufficient" 8 "NOPSysMsg_8_Unreleased_highway" 9 "NOPSysMsg_9_Out_of_speed_range" 10 "NOPSysMsg_10_Please_using_direction_lamp_switch_to_comfirm_right_lane_change_recommendation" 11 "NOPSysMsg_11_Please_using_direction_lamp_switch_to_comfirm_left_lane_change_recommendation" 12 "NOPSysMsg_12_Please_turn_off_direction_lamp_switch" 13 "NOPSysMsg_13_Entering_ramp_on_right_in_2km" 14 "NOPSysMsg_14_Entering_ramp_on_left_in_2km" 15 "NOPSysMsg_15_Entering_ramp_on_right_1km" 16 "NOPSysMsg_16_Entering_ramp_on_left_1km" 17 "NOPSysMsg_17_Entering_ramp_immediately" 18 "NOPSysMsg_18_Entering_main_road_of_highway" 19 "NOPSysMsg_19_About_to_left_lane_change" 20 "NOPSysMsg_20_About_to_right_lane_change" 21 "NOPSysMsg_21_Stay_in_current_lane" 22 "NOPSysMsg_22_Approaching_work_zone" 23 "NOPSysMsg_23_Over_ramp_speed_limit_please_slow_down" 24 "NOPSysMsg_24_Please_change_lane_to_right_manually" 25 "NOPSysMsg_25_Please_change_lane_to_left_manually" 26 "NOPSysMsg_26_Please_merge_into_main_roada_manually" 27 "NOPSysMsg_27_About_to_finish_NOP_navigation" 28 "NOPSysMsg_28_Location_signal_weak" 29 "NOPSysMsg_29_Tire_pressure_condition_insufficient" 30 "NOPSysMsg_30_Brake_disk_temperatue_high" 31 "NOPSysMsg_31_HDM_system_not_available" 32 "NOPSysMsg_32_Please_turn_off_direction_lamp_switch" 33 "NOPSysMsg_33_Limited_function_due_to_faults" 34 "NOPSysMsg_34_Navigation_not_ready" 35 "NOPSysMsg_35_Navigation_started" 36 "NOPSysMsg_36_Recommend_to_Change_to_Left_lane" 37 "NOPSysMsg_37_Recommend_to_Change_to_Right_lane" 38 "NOPSysMsg_38_NOP_approach_boundary" 39 "NOPSysMsg_39_NOP_exit" 40 "NOPSysMsg_40_Navigation_finished" 41 "NOPSysMsg_41_Please_Open_NOA_Switch" 42 "NOPSysMsg_42_Please_Notice_Merging_Veicle" 43 "NOPSysMsg_43_Out_of_Override_Time" 44 "NOPSysMsg_44_Reserved" 45 "NOPSysMsg_45_Left_500m_Exit" 46 "NOPSysMsg_46_Left_200m_Exit" 47 "NOPSysMsg_47_Left_500m_Construct" 48 "NOPSysMsg_48_Approaching_Tunnel" 49 "NOPSysMsg_49_Please_change_lane_manually" 50 "NOPSysMsg_50_Update_Planning_Path" 51 "NOPSysMsg_51_Approaching_AccelerationLane" 52 "NOPSysMsg_52_Approaching_Jam_to_Change_to_Left_lane" 53 "NOPSysMsg_53_Approaching_Jam_to_Change_to_Right_lane" 54 "NOPSysMsg_54_Entering_ramp_on_right_immediately" 55 "NOPSysMsg_55_Entering_ramp_on_left_immediately" 56 "NOPSysMsg_56_Entering_main_on_right_road_of_highway" 57 "NOPSysMsg_57_Entering_main_on_left_road_of_highway" 58 "NOPSysMsg_58_Selecting_toll_lane_D2D" 59 "NOPSysMsg_59_Lane_recognition_failed_manual_takeover_D2D";
VAL_ 755 ILCRInHMI 0 "LCRInHMI_0_unavailable" 1 "LCRInHMI_1_NotActive" 2 "LCRInHMI_2_Left" 3 "LCRInHMI_3_Right";
VAL_ 755 INOADistDecMsg 0 "NOADistDecMsg_0_NoDisplay" 1 "NOADistDecMsg_1_Dec1" 2 "NOADistDecMsg_2_Dec2" 3 "NOADistDecMsg_3_Dec3" 4 "NOADistDecMsg_4_Dec4" 5 "NOADistDecMsg_5_Dec5" 6 "NOADistDecMsg_6_Dec6" 7 "NOADistDecMsg_7_Dec7" 8 "NOADistDecMsg_8_Dec8" 9 "NOADistDecMsg_9_Dec9" 10 "NOADistDecMsg_10_Dec10" 11 "NOADistDecMsg_11_Dec11" 12 "NOADistDecMsg_12_Dec12" 13 "NOADistDecMsg_13_Dec13" 14 "NOADistDecMsg_14_Dec14" 15 "NOADistDecMsg_15_Dec15" 16 "NOADistDecMsg_16_Dec16" 17 "NOADistDecMsg_17_Dec17" 18 "NOADistDecMsg_18_Dec18" 19 "NOADistDecMsg_19_Dec19" 20 "NOADistDecMsg_20_Dec20" 21 "NOADistDecMsg_21_Dec21" 22 "NOADistDecMsg_22_Dec22" 23 "NOADistDecMsg_23_Dec23" 24 "NOADistDecMsg_24_Dec24" 25 "NOADistDecMsg_25_Dec25" 26 "NOADistDecMsg_26_Dec26" 27 "NOADistDecMsg_27_Dec27" 28 "NOADistDecMsg_28_Dec28" 29 "NOADistDecMsg_29_Dec29" 30 "NOADistDecMsg_30_Dec30" 31 "NOADistDecMsg_31_Dec31";
VAL_ 755 INarRoVslAssSwResp 0 "NarRoVslAssSwResp_0_0_Unavalible" 1 "NarRoVslAssSwResp_1_1_OFF" 2 "NarRoVslAssSwResp_2_2_Near" 3 "NarRoVslAssSwResp_3_3_Middle" 4 "NarRoVslAssSwResp_4_4_Far";
VAL_ 755 INrwroadBwdAssMesg 0 "NrwroadBwdAssMesg_0_reserved" 1 "NrwroadBwdAssMesg_1_reserved" 2 "NrwroadBwdAssMesg_2_reserved" 3 "NrwroadBwdAssMesg_3_reserved" 4 "NrwroadBwdAssMesg_4_reserved" 5 "NrwroadBwdAssMesg_5_reserved" 6 "NrwroadBwdAssMesg_6_reserved" 7 "NrwroadBwdAssMesg_7_reserved" 8 "NrwroadBwdAssMesg_8_reserved" 9 "NrwroadBwdAssMesg_9_reserved" 10 "NrwroadBwdAssMesg_10_reserved" 11 "NrwroadBwdAssMesg_11_reserved" 12 "NrwroadBwdAssMesg_12_reserved" 13 "NrwroadBwdAssMesg_13_reserved" 14 "NrwroadBwdAssMesg_14_reserved" 15 "NrwroadBwdAssMesg_15_reserved" 16 "NrwroadBwdAssMesg_16_reserved" 17 "NrwroadBwdAssMesg_17_reserved" 18 "NrwroadBwdAssMesg_18_reserved" 19 "NrwroadBwdAssMesg_19_reserved" 20 "NrwroadBwdAssMesg_20_reserved" 21 "NrwroadBwdAssMesg_21_reserved" 22 "NrwroadBwdAssMesg_22_reserved" 23 "NrwroadBwdAssMesg_23_reserved" 24 "NrwroadBwdAssMesg_24_reserved" 25 "NrwroadBwdAssMesg_25_reserved" 26 "NrwroadBwdAssMesg_26_reserved" 27 "NrwroadBwdAssMesg_27_reserved" 28 "NrwroadBwdAssMesg_28_reserved" 29 "NrwroadBwdAssMesg_29_reserved" 30 "NrwroadBwdAssMesg_30_reserved" 31 "NrwroadBwdAssMesg_31_reserved";
VAL_ 755 IJAMsgReq 0 "JAMsgReq_0_NoDisplay" 1 "JAMsgReq_1__1" 2 "JAMsgReq_2__2" 3 "JAMsgReq_3__3" 4 "JAMsgReq_4__4" 5 "JAMsgReq_5__5" 6 "JAMsgReq_6__6" 7 "JAMsgReq_7__7" 8 "JAMsgReq_8__8" 9 "JAMsgReq_9__9" 10 "JAMsgReq_10__10" 11 "JAMsgReq_11__11" 12 "JAMsgReq_12__12" 13 "JAMsgReq_13__12" 14 "JAMsgReq_14__14" 15 "JAMsgReq_15__15";
VAL_ 755 IDetourMsgReq 0 "DetourMsgReq_0_NoDisplay" 1 "DetourMsgReq_1__1" 2 "DetourMsgReq_2__2" 3 "DetourMsgReq_3__3" 4 "DetourMsgReq_4__4" 5 "DetourMsgReq_5__5" 6 "DetourMsgReq_6__6" 7 "DetourMsgReq_7__7" 8 "DetourMsgReq_8__8" 9 "DetourMsgReq_9__9" 10 "DetourMsgReq_10__10" 11 "DetourMsgReq_11__11" 12 "DetourMsgReq_12__12" 13 "DetourMsgReq_13__12" 14 "DetourMsgReq_14__14" 15 "DetourMsgReq_15__15";
VAL_ 755 IParkngOutDircnSelResult 0 "ParkngOutDircnSelResult_0_none" 1 "ParkngOutDircnSelResult_1_Front_Left_Cross" 2 "ParkngOutDircnSelResult_2_Front_Left_Parallel" 3 "ParkngOutDircnSelResult_3_Front_Out" 4 "ParkngOutDircnSelResult_4_Front_Right_Cross" 5 "ParkngOutDircnSelResult_5_Front_Right_Parallel" 6 "ParkngOutDircnSelResult_6_Back_Out" 7 "ParkngOutDircnSelResult_7_Back_Left_Cross" 8 "ParkngOutDircnSelResult_8_Back_Right_Cross" 9 "ParkngOutDircnSelResult_9_Reserved" 10 "ParkngOutDircnSelResult_10_Reserved" 11 "ParkngOutDircnSelResult_11_Reserved" 12 "ParkngOutDircnSelResult_12_Reserved" 13 "ParkngOutDircnSelResult_13_Reserved" 14 "ParkngOutDircnSelResult_14_Reserved" 15 "ParkngOutDircnSelResult_15_Reserved";
VAL_ 755 INOAQukChgSwDspCmd 0 "NOAQukChgSwDspCmd_0_unavailable" 1 "NOAQukChgSwDspCmd_1_temporary_unavailable" 2 "NOAQukChgSwDspCmd_2_NOA2LCC" 3 "NOAQukChgSwDspCmd_3_LCC2NOA";
VAL_ 755 INrwroadBwdAssSwSts 0 "NrwroadBwdAssSwSts_0_0_Unavialable" 1 "NrwroadBwdAssSwSts_1_1_Highlight" 2 "NrwroadBwdAssSwSts_2_2_Flashing" 3 "NrwroadBwdAssSwSts_3_3_Hide" 4 "NrwroadBwdAssSwSts_4_4_Reserved4" 5 "NrwroadBwdAssSwSts_5_5_Reserved5" 6 "NrwroadBwdAssSwSts_6_6_Reserved6" 7 "NrwroadBwdAssSwSts_7_7_Reserved7";
VAL_ 755 IFLUSSSts 0 "FLUSSSts_0_Normal" 1 "FLUSSSts_1_Fault" 2 "FLUSSSts_2_Blind";
VAL_ 755 IPEBSts 0 "PEBSts_0_off" 1 "PEBSts_1_passive" 2 "PEBSts_2_standby" 3 "PEBSts_3_active" 4 "PEBSts_4_error" 5 "PEBSts_5_Reserved";
VAL_ 755 IFrtCarGoNotfrDspCmd 0 "FrtCarGoNotfrDspCmd_0_Unavallable" 1 "FrtCarGoNotfrDspCmd_1_Off" 2 "FrtCarGoNotfrDspCmd_2_On" 3 "FrtCarGoNotfrDspCmd_3_Reserved";
VAL_ 755 IFRSUSSSts 0 "FRSUSSSts_0_Normal" 1 "FRSUSSSts_1_Fault" 2 "FRSUSSSts_2_Blind";
VAL_ 755 IFMRUSSSts 0 "FMRUSSSts_0_Normal" 1 "FMRUSSSts_1_Fault" 2 "FMRUSSSts_2_Blind";
VAL_ 755 IFMLUSSSts 0 "FMLUSSSts_0_Normal" 1 "FMLUSSSts_1_Fault" 2 "FMLUSSSts_2_Blind";
VAL_ 755 INOALaneSetDspCmd 0 "NOALaneSetDspCmd_0_NOALaneSetCmd_0_unavailable" 1 "NOALaneSetDspCmd_1_NOALaneSetCmd_1_Left1" 2 "NOALaneSetDspCmd_2_NOALaneSetCmd_2_Left2" 3 "NOALaneSetDspCmd_3_Reserved";
VAL_ 755 INOAETCSetDspCmd 0 "NOAETCSetDspCmd_0_NoRequest" 1 "NOAETCSetDspCmd_1_MTC" 2 "NOAETCSetDspCmd_2_ETC" 3 "NOAETCSetDspCmd_3_Reserved";
VAL_ 755 ILCRSwDspCmd 0 "LCRSwDspCmd_0_unavailable" 1 "LCRSwDspCmd_1_off" 2 "LCRSwDspCmd_2_on" 3 "LCRSwDspCmd_3_reserved";
VAL_ 755 IFRUSSSts 0 "FRUSSSts_0_Normal" 1 "FRUSSSts_1_Fault" 2 "FRUSSSts_2_Blind";
VAL_ 755 INOPCitySwDspCmd 0 "NOPCitySwDspCmd_0_Unavailable" 1 "NOPCitySwDspCmd_1_Off" 2 "NOPCitySwDspCmd_2_On" 3 "NOPCitySwDspCmd_3_Reserved";
VAL_ 755 INOPSwDspCmd 0 "NOPSwDspCmd_0_Unavailable" 1 "NOPSwDspCmd_1_off" 2 "NOPSwDspCmd_2_NOP_NdConfirm" 3 "NOPSwDspCmd_3_NOP_NotNdConfirm";
VAL_ 755 INOAReportSetDspCmd 0 "NOAReportSetDspCmd_0_NOAReportSetCmd_0_unavailable" 1 "NOAReportSetDspCmd_1_NOAReportSetCmd_1_detail" 2 "NOAReportSetDspCmd_2_NOAReportSetCmd_2_concision" 3 "NOAReportSetDspCmd_3_NOAReportSetCmd__3_minimal";
VAL_ 755 IRLUSSSts 0 "RLUSSSts_0_Normal" 1 "RLUSSSts_1_Fault" 2 "RLUSSSts_2_Blind";
VAL_ 755 IRLSUSSSts 0 "RLSUSSSts_0_Normal" 1 "RLSUSSSts_1_Fault" 2 "RLSUSSSts_2_Blind";
VAL_ 755 IPEBWarngReq 0 "PEBWarngReq_0_Default" 1 "PEBWarngReq_1_TURN_GREEN" 2 "PEBWarngReq_2_TURN_YELLOW" 3 "PEBWarngReq_3_TURN_RED";
VAL_ 755 INrwroadBwdAssConfrmSwDscmd 0 "NrwroadBwdAssConfrmSwDscmd_0_0_Unavalible" 1 "NrwroadBwdAssConfrmSwDscmd_1_1_Active_conformed" 2 "NrwroadBwdAssConfrmSwDscmd_2_2_quit_conformed";
VAL_ 755 IRRUSSSts 0 "RRUSSSts_0_Normal" 1 "RRUSSSts_1_Fault" 2 "RRUSSSts_2_Blind";
VAL_ 755 IRRSUSSSts 0 "RRSUSSSts_0_Normal" 1 "RRSUSSSts_1_Fault" 2 "RRSUSSSts_2_Blind";
VAL_ 755 IRMRUSSSts 0 "RMRUSSSts_0_Normal" 1 "RMRUSSSts_1_Fault" 2 "RMRUSSSts_2_Blind";
VAL_ 755 IRMLUSSSts 0 "RMLUSSSts_0_Normal" 1 "RMLUSSSts_1_Fault" 2 "RMLUSSSts_2_Blind";
VAL_ 755 IParkngOutFRCrsSts 0 "ParkngOutFRCrsSts_0_Invalid" 1 "ParkngOutFRCrsSts_1_Valid";
VAL_ 755 IParkngOutFLParllSts 0 "ParkngOutFLParllSts_0_Invalid" 1 "ParkngOutFLParllSts_1_Valid";
VAL_ 755 IParkngOutFLCrsSts 0 "ParkngOutFLCrsSts_0_Invalid" 1 "ParkngOutFLCrsSts_1_Valid";
VAL_ 755 IParkngOutBkRCrsSts 0 "ParkngOutBkRCrsSts_0_Invalid" 1 "ParkngOutBkRCrsSts_1_Valid";
VAL_ 755 IParkngOutBkLCrsSts 0 "ParkngOutBkLCrsSts_0_Invalid" 1 "ParkngOutBkLCrsSts_1_Valid";
VAL_ 755 IParkngOutBkCrsSts 0 "ParkngOutBkCrsSts_0_Invalid" 1 "ParkngOutBkCrsSts_1_Valid";
VAL_ 755 IHPPOnRoutSts 0 "HPPOnRoutSts_0_Not_On_Rout" 1 "HPPOnRoutSts_1_On_Rout";
VAL_ 755 IHPPMapBuildSts 0 "HPPMapBuildSts_0_Not_Built" 1 "HPPMapBuildSts_1_Built";
VAL_ 755 IParkngDirAvlSts 0 "ParkngDirAvlSts_0_Rear" 1 "ParkngDirAvlSts_1_Head" 2 "ParkngDirAvlSts_2_Rear_and_Head" 3 "ParkngDirAvlSts_3_Reserved";
VAL_ 755 IParkngDirSwResp 0 "ParkngDirSwResp_0_No_Request" 1 "ParkngDirSwResp_1_Front_parking_in" 2 "ParkngDirSwResp_2_back_parking_in" 3 "ParkngDirSwResp_3_Reserved";
VAL_ 755 IPEBSwResp 0 "PEBSwResp_0_On" 1 "PEBSwResp_1_Off";
VAL_ 755 IParkngSlotFindSts 0 "ParkngSlotFindSts_0_False" 1 "ParkngSlotFindSts_1_True";
VAL_ 755 IParkngOutFrtCrsSts 0 "ParkngOutFrtCrsSts_0_Invalid" 1 "ParkngOutFrtCrsSts_1_Valid";
VAL_ 755 IParkngOutFRParllSts 0 "ParkngOutFRParllSts_0_Invalid" 1 "ParkngOutFRParllSts_1_Valid";
VAL_ 486 IFrtCarGoNotfr 0 "FrtCarGoNotfr_0_False" 1 "FrtCarGoNotfr_1_Waminglevel_1" 2 "FrtCarGoNotfr_2_Warninglevel_2" 3 "FrtCarGoNotfr_3_Warninglevel_3";
VAL_ 486 IACCSysFltSts_SCS 0 "ACCSysFltSts_SCS_0_NoError" 1 "ACCSysFltSts_SCS_1_PerformanceDegradation" 2 "ACCSysFltSts_SCS_2_SystemTemporaryUnvailable" 3 "ACCSysFltSts_SCS_3_ServiceRequired" 4 "ACCSysFltSts_SCS_4_Reserved" 5 "ACCSysFltSts_SCS_5_Reserved" 6 "ACCSysFltSts_SCS_6_Reserved" 7 "ACCSysFltSts_SCS_7_Reserved";
VAL_ 337 IAutoLaneChngRLaneSts 0 "AutoLaneChngRLaneSts_0_NoRequest" 1 "AutoLaneChngRLaneSts_1_LaneChangeInhibit" 2 "AutoLaneChngRLaneSts_2_WaitingForLaneChangeStarting" 3 "AutoLaneChngRLaneSts_3_LaneChangeInProgress" 4 "AutoLaneChngRLaneSts_4_LaneChangeSucces" 5 "AutoLaneChngRLaneSts_5_LaneChangeFailed" 6 "AutoLaneChngRLaneSts_6_LaneChangeSuppressByDriver" 7 "AutoLaneChngRLaneSts_7_ReturnToEgoLaneByDriver" 8 "AutoLaneChngRLaneSts_8_ReturnToEgoLaneByAlc" 9 "AutoLaneChngRLaneSts_9_LaneChangeManoeuvreWithRisk" 10 "AutoLaneChngRLaneSts_10_ReturnToEgoLaneSuccess" 11 "AutoLaneChngRLaneSts_11_Waiting_For_ALC_Because_Vehicle_Speed_Too_Low" 12 "AutoLaneChngRLaneSts_12_Waiting_For_ALC_Because_Vehicle_Speed_Too_High" 13 "AutoLaneChngRLaneSts_13_Vehicle_go_through_the_lane";
VAL_ 337 IESSDirInd 0 "ESSDirInd_0_Unactive" 1 "ESSDirInd_1_Left" 2 "ESSDirInd_2_Right" 3 "ESSDirInd_3_reserved";
VAL_ 337 IPilotTkovMsgReq 0 "PilotTkovMsgReq_0_NoDisplay" 1 "PilotTkovMsgReq_1__1" 2 "PilotTkovMsgReq_2__2" 3 "PilotTkovMsgReq_3__3" 4 "PilotTkovMsgReq_4__4" 5 "PilotTkovMsgReq_5__5" 6 "PilotTkovMsgReq_6__6" 7 "PilotTkovMsgReq_7__7" 8 "PilotTkovMsgReq_8__8" 9 "PilotTkovMsgReq_9__9" 10 "PilotTkovMsgReq_10__10" 11 "PilotTkovMsgReq_11__11" 12 "PilotTkovMsgReq_12__12" 13 "PilotTkovMsgReq_13__12" 14 "PilotTkovMsgReq_14__14" 15 "PilotTkovMsgReq_15__15";
VAL_ 337 INOPSysSts_ZPD 0 "NOPSysSts_ZPD_0_Off" 1 "NOPSysSts_ZPD_1_Passive" 2 "NOPSysSts_ZPD_2_Standby" 3 "NOPSysSts_ZPD_3_HandsOn_active" 4 "NOPSysSts_ZPD_4_HandsFree_active" 5 "NOPSysSts_ZPD_5_Wait_for_driver_to_confirm" 6 "NOPSysSts_ZPD_6_ALC_Active" 7 "NOPSysSts_ZPD_7_Override" 8 "NOPSysSts_ZPD_8_TOR" 9 "NOPSysSts_ZPD_9_Prohibit" 10 "NOPSysSts_ZPD_10_Fault" 11 "NOPSysSts_ZPD_11_SafeStop";
VAL_ 337 IPrkgDstCtrlSwResp 0 "PrkgDstCtrlSwResp_0_Unavailable" 1 "PrkgDstCtrlSwResp_1_ON" 2 "PrkgDstCtrlSwResp_2_OFF";
VAL_ 337 IALCSysSts 0 "ALCSysSts_0_Off" 1 "ALCSysSts_1_ALCSySSts_1_Stand_by" 2 "ALCSysSts_2_Active_Request" 3 "ALCSysSts_3_Active_Control" 4 "ALCSysSts_4_Passive" 5 "ALCSysSts_5_Lane_Change_Returning" 6 "ALCSysSts_6_TOR" 7 "ALCSysSts_7_Please_Turn_Off_Direction_Indication_Lamp_Switch";
VAL_ 337 IALCSysFltSts 0 "ALCSysFltSts_0_No_error" 1 "ALCSysFltSts_1_Performance_degradation" 2 "ALCSysFltSts_2_System_temporary_unavailable" 3 "ALCSysFltSts_3_Service_required" 4 "ALCSysFltSts_4_Reserved";
VAL_ 337 IAutoLaneChngLLaneSts 0 "AutoLaneChngLLaneSts_0_NoRequest" 1 "AutoLaneChngLLaneSts_1_LaneChangeInhibit" 2 "AutoLaneChngLLaneSts_2_WaitingForLaneChangeStarting" 3 "AutoLaneChngLLaneSts_3_LaneChangeInProgress" 4 "AutoLaneChngLLaneSts_4_LaneChangeSucces" 5 "AutoLaneChngLLaneSts_5_LaneChangeFailed" 6 "AutoLaneChngLLaneSts_6_LaneChangeSuppressByDriver" 7 "AutoLaneChngLLaneSts_7_ReturnToEgoLaneByDriver" 8 "AutoLaneChngLLaneSts_8_ReturnToEgoLaneByAlc" 9 "AutoLaneChngLLaneSts_9_LaneChangeManoeuvreWithRisk" 10 "AutoLaneChngLLaneSts_10_ReturnToEgoLaneSuccess" 11 "AutoLaneChngRLaneSts_11_Waiting_For_ALC_Because_Vehicle_Speed_Too_Low" 12 "AutoLaneChngRLaneSts_12_Waiting_For_ALC_Because_Vehicle_Speed_Too_High" 13 "AutoLaneChngRLaneSts_13_Vehicle_go_through_the_lane";
VAL_ 337 IESSSysSts 0 "ESSSysSts_0_Off" 1 "ESSSysSts_1_StandBy" 2 "ESSSysSts_2_Passive" 3 "ESSSysSts_3_Active" 4 "ESSSysSts_4_Disable" 5 "ESSSysSts_5_reserved" 6 "ESSSysSts_6_reserved";
VAL_ 337 IESSSysFltSts 0 "ESSSysFltSts_0_NoError" 1 "ESSSysFltSts_1_PerformanceDegradation" 2 "ESSSysFltSts_2_SystemTemporaryUnvailable" 3 "ESSSysFltSts_3_ServiceRequired" 4 "ESSSysFltSts_4_Reserved" 5 "ESSSysFltSts_5_Reserved" 6 "ESSSysFltSts_6_Reserved" 7 "ESSSysFltSts_7_Reserved";
VAL_ 337 IESSDrvrTkovReq 0 "ESSDrvrTkovReq_0_False" 1 "ESSDrvrTkovReq_1_True";
VAL_ 337 ISLIFSysFltSts 0 "SLIFSysFltSts_0_NoError" 1 "SLIFSysFltSts_1_PerformanceDegradation" 2 "SLIFSysFltSts_2_SystemTemporaryUnavailable" 3 "SLIFSysFltSts_3_ServiceRequired";
VAL_ 337 IParkngslottype 0 "ParkngSlotType_0__null" 1 "ParkngSlotType_1_left_vertical" 2 "ParkngSlotType_2_left_parallel" 3 "ParkngSlotType_3_right_vertical" 4 "ParkngSlotType_4_right_parallel";
VAL_ 337 INOPSysFltSts 0 "NOPSysFltSts_0_No_error" 1 "NOPSysFltSts_1_Performance_degradation" 2 "NOPSysFltSts_2_System_temporary_unavailable" 3 "NOPSysFltSts_3_Service_required" 4 "NOPSysFltSts_4_Reserved";
VAL_ 720 ILADSInfoDispReq 0 "LADSInfoDispReq_0_0_NoRequest" 1 "LADSInfoDispReq_1_Reserved" 2 "LADSInfoDispReq_2_2_Vehicle_speed_is_too_high_APA_system_abort" 3 "LADSInfoDispReq_3_3_Vehicle_speed_is_too_high_please_be_slow_down" 4 "LADSInfoDispReq_4_4_Parking_slot_searching" 5 "LADSInfoDispReq_5_5_Parking_Exit" 6 "LADSInfoDispReq_6_Reserved" 7 "LADSInfoDispReq_7_7_Please_stop_the_car" 8 "LADSInfoDispReq_8_Reserved" 9 "LADSInfoDispReq_9_9_Parking_pause_please_confirm_in_APP" 10 "LADSInfoDispReq_10_10_Press_start_for_APA_vehicle_control_or_choose_RPA" 11 "LADSInfoDispReq_11_11_Parking_pause_please_confirm_safety" 12 "LADSInfoDispReq_12_12_EPB_operated_Parking_exit" 13 "LADSInfoDispReq_13_13_No_obstacle_park_out_by_yourself" 14 "LADSInfoDispReq_14_14_Please_press_start_park_out" 15 "LADSInfoDispReq_15_15_Parking_pause_please_press_continue" 16 "LADSInfoDispReq_16_16_Please_fasten_the_safety_belt" 17 "LADSInfoDispReq_17_17_Please_close_the_door" 18 "LADSInfoDispReq_18_18_LADS_unavailable_parking_exit" 19 "LADSInfoDispReq_19_19_Left_steering" 20 "LADSInfoDispReq_20_20_user_open_the_door_Learning_quite" 21 "LADSInfoDispReq_21_Reserved" 22 "LADSInfoDispReq_22_22_RPA_ready_Please_leave_the_car_and_use_app" 23 "LADSInfoDispReq_23_Reserved" 24 "LADSInfoDispReq_24_Reserved" 25 "LADSInfoDispReq_25_Reserved" 26 "LADSInfoDispReq_26_Reserved" 27 "LADSInfoDispReq_27_Reserved" 28 "LADSInfoDispReq_28_Reserved" 29 "LADSInfoDispReq_29_29_Right_steering" 30 "LADSInfoDispReq_30_30_Please_step_on_the_brake_and_press_the_SSB" 31 "LADSInfoDispReq_31_31_Brake_And_PressSSB_to_take_over_Vehicle_during_P2P_or_APA" 32 "LADSInfoDispReq_32_Reserved" 33 "LADSInfoDispReq_33_33_Barrier_exist_please_remove" 34 "LADSInfoDispReq_34_34_Steering_wheel_has_been_turned" 35 "LADSInfoDispReq_35_35_Accelerator_pressed" 36 "LADSInfoDispReq_36_Reserved" 37 "LADSInfoDispReq_37_37_Shift_operated" 38 "LADSInfoDispReq_38_38_Adjustment_time_exceeded" 39 "LADSInfoDispReq_39_39_Slope_too_big" 40 "LADSInfoDispReq_40_40_Disturbe_overtime" 41 "LADSInfoDispReq_41_41_Space_too_small" 42 "LADSInfoDispReq_42_Reserved" 43 "LADSInfoDispReq_43_Reserved" 44 "LADSInfoDispReq_44_44_Please_release_brake_and_pay_attention_to_surroundings_using_active_control_measure_if_necessary" 45 "LADSInfoDispReq_45_45_Parking_is_ongoing" 46 "LADSInfoDispReq_46_46_Parking_manoeuvre_has_completed__Please_take_over_vehicle" 47 "LADSInfoDispReq_47_Reserved" 48 "LADSInfoDispReq_48_48_System_overtime_APA_system_quit" 49 "LADSInfoDispReq_49_Reserved" 50 "LADSInfoDispReq_50_Reserved" 51 "LADSInfoDispReq_51_Reserved" 52 "LADSInfoDispReq_52_Reserved" 53 "LADSInfoDispReq_53_Reserved" 54 "LADSInfoDispReq_54_Reserved" 55 "LADSInfoDispReq_55_Reserved" 56 "LADSInfoDispReq_56_Reserved" 57 "LADSInfoDispReq_57_Reserved" 58 "LADSInfoDispReq_58_Reserved" 59 "LADSInfoDispReq_59_Reserved" 60 "LADSInfoDispReq_60_Reserved" 61 "LADSInfoDispReq_61_Reserved" 62 "LADSInfoDispReq_62_Reserved" 63 "LADSInfoDispReq_63_63_Environment_Changed" 64 "LADSInfoDispReq_64_Reserved" 65 "LADSInfoDispReq_65_65_Pleasestopthecarfirst" 66 "LADSInfoDispReq_66_66_PleaseshifttoPfirst" 67 "LADSInfoDispReq_67_67_PleaseapplytheEPBfirst" 68 "LADSInfoDispReq_68_68_Pleasestartthevehicle" 69 "LADSInfoDispReq_69_69_Please_unlock_the_vehicle" 70 "LADSInfoDispReq_70_70_Please_takeover" 71 "LADSInfoDispReq_71_Reserved" 72 "LADSInfoDispReq_72_Reserved" 73 "LADSInfoDispReq_73_Reserved" 74 "LADSInfoDispReq_74_Reserved" 75 "LADSInfoDispReq_75_Reserved" 76 "LADSInfoDispReq_76_Reserved" 77 "LADSInfoDispReq_77_Reserved" 78 "LADSInfoDispReq_78_Reserved" 79 "LADSInfoDispReq_79_Reserved" 80 "LADSInfoDispReq_80_Reserved" 81 "LADSInfoDispReq_81_Reserved" 82 "LADSInfoDispReq_82_Reserved" 83 "LADSInfoDispReq_83_Reserved" 84 "LADSInfoDispReq_84_Reserved" 85 "LADSInfoDispReq_85_Reserved" 86 "LADSInfoDispReq_86_Reserved" 87 "LADSInfoDispReq_87_Reserved" 88 "LADSInfoDispReq_88_Reserved" 89 "LADSInfoDispReq_89_Reserved" 90 "LADSInfoDispReq_90_Reserved" 91 "LADSInfoDispReq_91_Reserved" 92 "LADSInfoDispReq_92_Reserved" 93 "LADSInfoDispReq_93_Reserved" 94 "LADSInfoDispReq_94_Reserved" 95 "LADSInfoDispReq_95_Reserved" 96 "LADSInfoDispReq_96_Reserved" 97 "LADSInfoDispReq_97_97_Tire_pressure_abnormal" 98 "LADSInfoDispReq_98_98_Please_turn_off_the_engine_manually" 99 "LADSInfoDispReq_99_99_Please_lock_the_vehicle" 100 "LADSInfoDispReq_100_100_Long_time_not_operated" 101 "LADSInfoDispReq_101_Reserved" 102 "LADSInfoDispReq_102_102_HaParkingPausezard_start_error" 103 "LADSInfoDispReq_103_103_Unlock_failed" 104 "LADSInfoDispReq_104_104_SSB_pressed" 105 "LADSInfoDispReq_105_105_Bluetooth_inactive" 106 "LADSInfoDispReq_106_106_Has_changed_to_normal_drive_mode" 107 "LADSInfoDispReq_107_ACC_actived_LADS_exit" 108 "LADSInfoDispReq_108_AEB_actived_LADS_exit" 109 "LADSInfoDispReq_109_109_TJA_actived_LADS_exit" 110 "LADSInfoDispReq_110_110_Lockedthecar" 111 "LADSInfoDispReq_111_111_NotchooseRPA" 112 "LADSInfoDispReq_112_Reserved" 113 "LADSInfoDispReq_113_113_Vehicle_does_not_stop" 114 "LADSInfoDispReq_114_114_Barrier_in_slot_change_another" 115 "LADSInfoDispReq_115_Reserved" 116 "LADSInfoDispReq_116_Reserved" 117 "LADSInfoDispReq_117_Reserved" 118 "LADSInfoDispReq_118_Reserved" 119 "LADSInfoDispReq_119_Reserved" 120 "LADSInfoDispReq_120_Reserved" 121 "LADSInfoDispReq_121_Reserved" 122 "LADSInfoDispReq_122_Reserved" 123 "LADSInfoDispReq_123_Reserved" 124 "LADSInfoDispReq_124_Reserved" 125 "LADSInfoDispReq_125_Reserved" 126 "LADSInfoDispReq_126_Reserved" 127 "LADSInfoDispReq_127_Reserved" 128 "LADSInfoDispReq_128_128_Please_press_the_brake_padel_vehicle_control_has_not_started" 129 "LADSInfoDispReq_129_129_Parking_pause_please_press_the_button" 130 "LADSInfoDispReq_130_130_Detecting_if_the_slot_space_is_enough" 131 "LADSInfoDispReq_131_131_Please_exit_current_function_then_press_parkin" 132 "LADSInfoDispReq_132_Reserved" 133 "LADSInfoDispReq_133_Reserved" 134 "LADSInfoDispReq_134_Reserved" 135 "LADSInfoDispReq_135_Reserved" 136 "LADSInfoDispReq_136_Reserved" 137 "LADSInfoDispReq_137_Reserved" 138 "LADSInfoDispReq_138_Reserved" 139 "LADSInfoDispReq_139_Reserved" 140 "LADSInfoDispReq_140_Reserved" 141 "LADSInfoDispReq_141_Reserved" 142 "LADSInfoDispReq_142_Reserved" 143 "LADSInfoDispReq_143_Reserved" 144 "LADSInfoDispReq_144_Reserved" 145 "LADSInfoDispReq_145_Reserved" 146 "LADSInfoDispReq_146_146_Systemselfchecking" 147 "LADSInfoDispReq_147_Reserved" 148 "LADSInfoDispReq_148_Reserved" 149 "LADSInfoDispReq_149_149_Parking_pause_please_press_continue_in_APP" 150 "LADSInfoDispReq_150_150_Please_select_parkout_direction_in_ICM" 151 "LADSInfoDispReq_151_Reserved" 152 "LADSInfoDispReq_152_Reserved" 153 "LADSInfoDispReq_153_Reserved" 154 "LADSInfoDispReq_154_Reserved" 155 "LADSInfoDispReq_155_Reserved" 156 "LADSInfoDispReq_156_Reserved" 157 "LADSInfoDispReq_157_Reserved" 158 "LADSInfoDispReq_158_Reserved" 159 "LADSInfoDispReq_159_Reserved" 160 "LADSInfoDispReq_160_160_Engine_is_not_ready" 161 "LADSInfoDispReq_161_161_LADS_faultcannot_open" 162 "LADSInfoDispReq_162_162_LADS_busy_cannot_open" 163 "LADSInfoDispReq_163_163_Speed_is_too_high_cannot_open" 164 "LADSInfoDispReq_164_164_Vehicle_is_not_stop_cannot_open" 165 "LADSInfoDispReq_165_165_ADAS_is_actived" 166 "LADSInfoDispReq_166_166_waiting_for_key_off_and_lock" 167 "LADSInfoDispReq_167_167_Route_Learning_Start" 168 "LADSInfoDispReq_168_168_Route_learning_is_exit_Press_to_save_route" 169 "LADSInfoDispReq_169_169_Route_learning_is_over_time_Press_to_save_route" 170 "LADSInfoDispReq_170_170_Route_Learning_is_ongoing" 171 "LADSInfoDispReq_171_171_Stop_and_shift_to_P_if_want_to_finish_Leaning" 172 "LADSInfoDispReq_172_172_shift_to_P_if_want_to_finish_Leaning" 173 "LADSInfoDispReq_173_173_Route_learning_will_over_distance" 174 "LADSInfoDispReq_174_174_Select_Saving_Route" 175 "LADSInfoDispReq_175_175_stop_too_long_timesystem_exit" 176 "LADSInfoDispReq_176_176_Learning_over_distancesystem_exit" 177 "LADSInfoDispReq_177_177_shift_gear_over_timessystem_exit" 178 "LADSInfoDispReq_178_178_Route_too_complex_system_exit" 179 "LADSInfoDispReq_179_179_During_Route_Matching" 180 "LADSInfoDispReq_180_180_Route_Matched_Please_stop_car" 181 "LADSInfoDispReq_181_181_Route_Matched_Please_keep_stopping" 182 "LADSInfoDispReq_182_182_Route_Matching_Failedsystem_exit" 183 "LADSInfoDispReq_183_183_Route_FaultMatching_again" 184 "LADSInfoDispReq_184_184_Map_Loading_Failed" 185 "LADSInfoDispReq_185_185_Not_In_P_gearsystem_exit" 186 "LADSInfoDispReq_186_186_EPB_is_not_operated_system_exit" 187 "LADSInfoDispReq_187_187_Route_Delete_succeeded" 188 "LADSInfoDispReq_188_188_Route_Delete_Failedsystem_exit" 189 "LADSInfoDispReq_189_189_Not_supported_this_Route" 190 "LADSInfoDispReq_190_190_Environment_is_not_OK_for_Learning" 191 "LADSInfoDispReq_191_191_Route_is_SavingPlease_wait" 192 "LADSInfoDispReq_192_192_Please_select_park_route" 193 "LADSInfoDispReq_193_193_Route_Saving_succeeded" 194 "LADSInfoDispReq_194_194_Route_Saving_FailedSystem_exit" 195 "LADSInfoDispReq_195_195_Please_do_not_touch_the_steering_wheel" 196 "LADSInfoDispReq_196_196_Press_start_for_Route_Reply_vehicle_control_or_choose_APP" 197 "LADSInfoDispReq_197_197_Route_Reply_Ongoing" 198 "LADSInfoDispReq_198_198_Please_select_parking_slot" 199 "LADSInfoDispReq_199_199_Press_start_for_Parking_vehicle_control" 200 "LADSInfoDispReq_200_200_Please_select_route_to_replace" 201 "LADSInfoDispReq_201_201_Please_Press_to_Start_Route_Reply" 202 "LADSInfoDispReq_202_202_System_control_exit_press_button_to_continute_learning_by_driver" 203 "LADSInfoDispReq_203_203_Finial_slot_not_available_Please_select_other_slot" 204 "LADSInfoDispReq_204_204_Route_learning_Failed" 205 "LADSInfoDispReq_205_205_Route_Reply_Completed" 206 "LADSInfoDispReq_206_206_Route_learning_press_stop_button_to_finsih_learning" 207 "LADSInfoDispReq_207_207_Please_select_route" 208 "LADSInfoDispReq_208_208_Route_learning_will_over_time" 209 "LADSInfoDispReq_209_209_Route_Unavailable" 210 "LADSInfoDispReq_210_210_Not_In_R_gear" 211 "LADSInfoDispReq_211_211_ARA_Ongoing" 212 "LADSInfoDispReq_212_212_ARA_Completed" 213 "LADSInfoDispReq_213_213_Please_press_the_brake_padel_for_vehicle_control_hand_shake" 214 "LADSInfoDispReq_214_214_No_P2P_Route" 215 "LADSInfoDispReq_215_215_System_control_exit_press_button_to_save_route" 216 "LADSInfoDispReq_216_216_System_Loading_please_wait" 217 "LADSInfoDispReq_217_217_No_GPS_system_function_exited" 218 "LADSInfoDispReq_218_218_No_GPSl_please_drive_to_open_area" 219 "LADSInfoDispReq_219_219_Remote_parking_completed_the_destination_is_not_a_storage_location" 220 "LADSInfoDispReq_220_220_Obstacle_avoidance_routes_during_vehicle_control" 221 "LADSInfoDispReq_221_221_Insufficient_environmental_information_not_supporting_P2P" 222 "LADSInfoDispReq_222_222_The_vehicle_passes_through_a_toll_pole_and_does_not_support_route_learning" 223 "LADSInfoDispReq_223_223_Long_time_without_passing_through_the_parking_area_not_supporting_route_learning" 224 "LADSInfoDispReq_224_224_Obstacle_avoidance_risk_is_high_and_requires_user_confirmation" 225 "LADSInfoDispReq_225_225_During_the_matching_process_the_vehicle_leaves_the_geofence" 226 "LADSInfoDispReq_226_226_When_the_steering_wheel_angle_is_too_large_during_the_learning_process" 227 "LADSInfoDispReq_227_227_The_learning_route_is_too_short_to_save" 228 "LADSInfoDispReq_228_228_When_the_P2P_4G_parking_function_is_enabled_the_user_clicks_on_the_relevant_parking_function_on_the_large_screen" 229 "LADSInfoDispReq_229_229_SilentSelect_parking_slot" 230 "LADSInfoDispReq_230_230_Temporary_system_malfunction" 231 "LADSInfoDispReq_231_231_Camera_occlusion_affecting_P2P_functionality" 232 "LADSInfoDispReq_232_232_During_the_playback_process_the_user_intervenes_with_the_actuator_and_the_system_re_plans_the_route_based_on_the_current_position_of_the_vehicle" 233 "LADSInfoDispReq_233_233_During_the_playback_process_the_self_owned_vehicle_intelligently_gives_way_to_other_vehicles" 234 "LADSInfoDispReq_234_234_The_environment_is_too_dark_affecting_perception_accuracy" 235 "LADSInfoDispReq_235_235_Remind_users_at_the_beginning_of_route_learning" 236 "LADSInfoDispReq_236_236_Detect_deceleration_of_vehicles_with_obstacles";
VAL_ 720 ILADSInfoDispReqToICM 0 "LADSInfoDispReqToICM_0_NoRequest" 1 "LADSInfoDispReqToICM_1_Reserved" 2 "LADSInfoDispReqToICM_2_2_Vehicle_speed_is_too_high_APA_system_abort" 3 "LADSInfoDispReqToICM_3_3_Vehicle_speed_is_too_high_please_be_slow_down" 4 "LADSInfoDispReqToICM_4_4_Parking_slot_searching" 5 "LADSInfoDispReqToICM_5_5_Parking_Exit" 6 "LADSInfoDispReqToICM_6_Reserved" 7 "LADSInfoDispReqToICM_7_7_Please_stop_the_car" 8 "LADSInfoDispReqToICM_8_Reserved" 9 "LADSInfoDispReqToICM_9_9_Parking_pause_please_confirm_in_APP" 10 "LADSInfoDispReqToICM_10_10_Press_start_for_APA_vehicle_control_or_choose_RPA" 11 "LADSInfoDispReqToICM_11_11_Parking_pause_please_confirm_safety" 12 "LADSInfoDispReqToICM_12_12_EPB_operated_Parking_exit" 13 "LADSInfoDispReqToICM_13_13_No_obstacle_park_out_by_yourself" 14 "LADSInfoDispReqToICM_14_14_Please_press_start_park_out" 15 "LADSInfoDispReqToICM_15_15_Parking_pause_please_press_continue" 16 "LADSInfoDispReqToICM_16_16_Please_fasten_the_safety_belt" 17 "LADSInfoDispReqToICM_17_17_Please_close_the_door" 18 "LADSInfoDispReqToICM_18_18_LADS_unavailable_parking_exit" 19 "LADSInfoDispReqToICM_19_19_Left_steering" 20 "LADSInfoDispReqToICM_20_20_user_open_the_door_Learning_quite" 21 "LADSInfoDispReqToICM_21_Reserved" 22 "LADSInfoDispReqToICM_22_22_RPA_ready_Please_leave_the_car_and_use_app" 23 "LADSInfoDispReqToICM_23_Reserved" 24 "LADSInfoDispReqToICM_24_Reserved" 25 "LADSInfoDispReqToICM_25_Reserved" 26 "LADSInfoDispReqToICM_26_Reserved" 27 "LADSInfoDispReqToICM_27_Reserved" 28 "LADSInfoDispReqToICM_28_Reserved" 29 "LADSInfoDispReqToICM_29_29_Right_steering" 30 "LADSInfoDispReqToICM_30_30_Please_step_on_the_brake_and_press_the_SSB" 31 "LADSInfoDispReqToICM_31_31_Brake_And_PressSSB_to_take_over_Vehicle_during_P2P_or_APA" 32 "LADSInfoDispReqToICM_32_Reserved" 33 "LADSInfoDispReqToICM_33_33_Barrier_exist_please_remove" 34 "LADSInfoDispReqToICM_34_34_Steering_wheel_has_been_turned" 35 "LADSInfoDispReqToICM_35_35_Accelerator_pressed" 36 "LADSInfoDispReqToICM_36_Reserved" 37 "LADSInfoDispReqToICM_37_37_Shift_operated" 38 "LADSInfoDispReqToICM_38_38_Adjustment_time_exceeded" 39 "LADSInfoDispReqToICM_39_39_Slope_too_big" 40 "LADSInfoDispReqToICM_40_40_Disturbe_overtime" 41 "LADSInfoDispReqToICM_41_41_Space_too_small" 42 "LADSInfoDispReqToICM_42_Reserved" 43 "LADSInfoDispReqToICM_43_Reserved" 44 "LADSInfoDispReqToICM_44_44_Please_release_brake_and_pay_attention_to_surroundings_using_active_control_measure_if_necessary" 45 "LADSInfoDispReqToICM_45_45_Parking_is_ongoing" 46 "LADSInfoDispReqToICM_46_46_Parking_manoeuvre_has_completed__Please_take_over_vehicle" 47 "LADSInfoDispReqToICM_47_Reserved" 48 "LADSInfoDispReqToICM_48_48_System_overtime_APA_system_quit" 49 "LADSInfoDispReqToICM_49_Reserved" 50 "LADSInfoDispReqToICM_50_Reserved" 51 "LADSInfoDispReqToICM_51_Reserved" 52 "LADSInfoDispReqToICM_52_Reserved" 53 "LADSInfoDispReqToICM_53_Reserved" 54 "LADSInfoDispReqToICM_54_Reserved" 55 "LADSInfoDispReqToICM_55_Reserved" 56 "LADSInfoDispReqToICM_56_Reserved" 57 "LADSInfoDispReqToICM_57_Reserved" 58 "LADSInfoDispReqToICM_58_Reserved" 59 "LADSInfoDispReqToICM_59_Reserved" 60 "LADSInfoDispReqToICM_60_Reserved" 61 "LADSInfoDispReqToICM_61_Reserved" 62 "LADSInfoDispReqToICM_62_Reserved" 63 "LADSInfoDispReqToICM_63_63_Environment_Changed" 64 "LADSInfoDispReqToICM_64_Reserved" 65 "LADSInfoDispReqToICM_65_65_Pleasestopthecarfirst" 66 "LADSInfoDispReqToICM_66_66_PleaseshifttoPfirst" 67 "LADSInfoDispReqToICM_67_67_PleaseapplytheEPBfirst" 68 "LADSInfoDispReqToICM_68_68_Pleasestartthevehicle" 69 "LADSInfoDispReqToICM_69_69_Please_unlock_the_vehicle" 70 "LADSInfoDispReqToICM_70_70_Please_takeover" 71 "LADSInfoDispReqToICM_71_Reserved" 72 "LADSInfoDispReqToICM_72_Reserved" 73 "LADSInfoDispReqToICM_73_Reserved" 74 "LADSInfoDispReqToICM_74_Reserved" 75 "LADSInfoDispReqToICM_75_Reserved" 76 "LADSInfoDispReqToICM_76_Reserved" 77 "LADSInfoDispReqToICM_77_Reserved" 78 "LADSInfoDispReqToICM_78_Reserved" 79 "LADSInfoDispReqToICM_79_Reserved" 80 "LADSInfoDispReqToICM_80_Reserved" 81 "LADSInfoDispReqToICM_81_Reserved" 82 "LADSInfoDispReqToICM_82_Reserved" 83 "LADSInfoDispReqToICM_83_Reserved" 84 "LADSInfoDispReqToICM_84_Reserved" 85 "LADSInfoDispReqToICM_85_Reserved" 86 "LADSInfoDispReqToICM_86_Reserved" 87 "LADSInfoDispReqToICM_87_Reserved" 88 "LADSInfoDispReqToICM_88_Reserved" 89 "LADSInfoDispReqToICM_89_Reserved" 90 "LADSInfoDispReqToICM_90_Reserved" 91 "LADSInfoDispReqToICM_91_Reserved" 92 "LADSInfoDispReqToICM_92_Reserved" 93 "LADSInfoDispReqToICM_93_Reserved" 94 "LADSInfoDispReqToICM_94_Reserved" 95 "LADSInfoDispReqToICM_95_Reserved" 96 "LADSInfoDispReqToICM_96_Reserved" 97 "LADSInfoDispReqToICM_97_97_Tire_pressure_abnormal" 98 "LADSInfoDispReqToICM_98_98_Please_turn_off_the_engine_manually" 99 "LADSInfoDispReqToICM_99_99_Please_lock_the_vehicle" 100 "LADSInfoDispReqToICM_100_100_Long_time_not_operated" 101 "LADSInfoDispReqToICM_101_Reserved" 102 "LADSInfoDispReqToICM_102_102_HaParkingPausezard_start_error" 103 "LADSInfoDispReqToICM_103_103_Unlock_failed" 104 "LADSInfoDispReqToICM_104_104_SSB_pressed" 105 "LADSInfoDispReqToICM_105_105_Bluetooth_inactive" 106 "LADSInfoDispReqToICM_106_106_Has_changed_to_normal_drive_mode" 107 "LADSInfoDispReqToICM_107_ACC_actived_LADS_exit" 108 "LADSInfoDispReqToICM_108_AEB_actived_LADS_exit" 109 "LADSInfoDispReqToICM_109_109_TJA_actived_LADS_exit" 110 "LADSInfoDispReqToICM_110_110_Lockedthecar" 111 "LADSInfoDispReqToICM_111_111_NotchooseRPA" 112 "LADSInfoDispReqToICM_112_Reserved" 113 "LADSInfoDispReqToICM_113_113_Vehicle_does_not_stop" 114 "LADSInfoDispReqToICM_114_114_Barrier_in_slot_change_another" 115 "LADSInfoDispReqToICM_115_Reserved" 116 "LADSInfoDispReqToICM_116_Reserved" 117 "LADSInfoDispReqToICM_117_Reserved" 118 "LADSInfoDispReqToICM_118_Reserved" 119 "LADSInfoDispReqToICM_119_Reserved" 120 "LADSInfoDispReqToICM_120_Reserved" 121 "LADSInfoDispReqToICM_121_Reserved" 122 "LADSInfoDispReqToICM_122_Reserved" 123 "LADSInfoDispReqToICM_123_Reserved" 124 "LADSInfoDispReqToICM_124_Reserved" 125 "LADSInfoDispReqToICM_125_Reserved" 126 "LADSInfoDispReqToICM_126_Reserved" 127 "LADSInfoDispReqToICM_127_Reserved" 128 "LADSInfoDispReqToICM_128_128_Please_press_the_brake_padel_vehicle_control_has_not_started" 129 "LADSInfoDispReqToICM_129_129_Parking_pause_please_press_the_button" 130 "LADSInfoDispReqToICM_130_130_Detecting_if_the_slot_space_is_enough" 131 "LADSInfoDispReqToICM_131_131_Please_exit_current_function_then_press_parkin" 132 "LADSInfoDispReqToICM_132_Reserved" 133 "LADSInfoDispReqToICM_133_Reserved" 134 "LADSInfoDispReqToICM_134_Reserved" 135 "LADSInfoDispReqToICM_135_Reserved" 136 "LADSInfoDispReqToICM_136_Reserved" 137 "LADSInfoDispReqToICM_137_Reserved" 138 "LADSInfoDispReqToICM_138_Reserved" 139 "LADSInfoDispReqToICM_139_Reserved" 140 "LADSInfoDispReqToICM_140_Reserved" 141 "LADSInfoDispReqToICM_141_Reserved" 142 "LADSInfoDispReqToICM_142_Reserved" 143 "LADSInfoDispReqToICM_143_Reserved" 144 "LADSInfoDispReqToICM_144_Reserved" 145 "LADSInfoDispReqToICM_145_Reserved" 146 "LADSInfoDispReqToICM_146_146_Systemselfchecking" 147 "LADSInfoDispReqToICM_147_Reserved" 148 "LADSInfoDispReqToICM_148_Reserved" 149 "LADSInfoDispReqToICM_149_149_Parking_pause_please_press_continue_in_APP" 150 "LADSInfoDispReqToICM_150_150_Please_select_parkout_direction_in_ICM" 151 "LADSInfoDispReqToICM_151_Reserved" 152 "LADSInfoDispReqToICM_152_Reserved" 153 "LADSInfoDispReqToICM_153_Reserved" 154 "LADSInfoDispReqToICM_154_Reserved" 155 "LADSInfoDispReqToICM_155_Reserved" 156 "LADSInfoDispReqToICM_156_Reserved" 157 "LADSInfoDispReqToICM_157_Reserved" 158 "LADSInfoDispReqToICM_158_Reserved" 159 "LADSInfoDispReqToICM_159_Reserved" 160 "LADSInfoDispReqToICM_160_160_Engine_is_not_ready" 161 "LADSInfoDispReqToICM_161_161_LADS_faultcannot_open" 162 "LADSInfoDispReqToICM_162_162_LADS_busy_cannot_open" 163 "LADSInfoDispReqToICM_163_163_Speed_is_too_high_cannot_open" 164 "LADSInfoDispReqToICM_164_164_Vehicle_is_not_stop_cannot_open" 165 "LADSInfoDispReqToICM_165_165_ADAS_is_actived" 166 "LADSInfoDispReqToICM_166_166_waiting_for_key_off_and_lock" 167 "LADSInfoDispReqToICM_167_167_Route_Learning_Start" 168 "LADSInfoDispReqToICM_168_168_Route_learning_is_exit_Press_to_save_route" 169 "LADSInfoDispReqToICM_169_169_Route_learning_is_over_time_Press_to_save_route" 170 "LADSInfoDispReqToICM_170_170_Route_Learning_is_ongoing" 171 "LADSInfoDispReqToICM_171_171_Stop_and_shift_to_P_if_want_to_finish_Leaning" 172 "LADSInfoDispReqToICM_172_172_shift_to_P_if_want_to_finish_Leaning" 173 "LADSInfoDispReqToICM_173_173_Route_learning_will_over_distance" 174 "LADSInfoDispReqToICM_174_174_Select_Saving_Route" 175 "LADSInfoDispReqToICM_175_175_stop_too_long_timesystem_exit" 176 "LADSInfoDispReqToICM_176_176_Learning_over_distancesystem_exit" 177 "LADSInfoDispReqToICM_177_177_shift_gear_over_timessystem_exit" 178 "LADSInfoDispReqToICM_178_178_Route_too_complex_system_exit" 179 "LADSInfoDispReqToICM_179_179_During_Route_Matching" 180 "LADSInfoDispReqToICM_180_180_Route_Matched_Please_stop_car" 181 "LADSInfoDispReqToICM_181_181_Route_Matched_Please_keep_stopping" 182 "LADSInfoDispReqToICM_182_182_Route_Matching_Failedsystem_exit" 183 "LADSInfoDispReqToICM_183_183_Route_FaultMatching_again" 184 "LADSInfoDispReqToICM_184_184_Map_Loading_Failed" 185 "LADSInfoDispReqToICM_185_185_Not_In_P_gearsystem_exit" 186 "LADSInfoDispReqToICM_186_186_EPB_is_not_operated_system_exit" 187 "LADSInfoDispReqToICM_187_187_Route_Delete_succeeded" 188 "LADSInfoDispReqToICM_188_188_Route_Delete_Failedsystem_exit" 189 "LADSInfoDispReqToICM_189_189_Not_supported_this_Route" 190 "LADSInfoDispReqToICM_190_190_Environment_is_not_OK_for_Learning" 191 "LADSInfoDispReqToICM_191_191_Route_is_SavingPlease_wait" 192 "LADSInfoDispReqToICM_192_192_Please_select_park_route" 193 "LADSInfoDispReqToICM_193_193_Route_Saving_succeeded" 194 "LADSInfoDispReqToICM_194_194_Route_Saving_FailedSystem_exit" 195 "LADSInfoDispReqToICM_195_195_Please_do_not_touch_the_steering_wheel" 196 "LADSInfoDispReqToICM_196_196_Press_start_for_Route_Reply_vehicle_control_or_choose_APP" 197 "LADSInfoDispReqToICM_197_197_Route_Reply_Ongoing" 198 "LADSInfoDispReqToICM_198_198_Please_select_parking_slot" 199 "LADSInfoDispReqToICM_199_199_Press_start_for_Parking_vehicle_control" 200 "LADSInfoDispReqToICM_200_200_Please_select_route_to_replace" 201 "LADSInfoDispReqToICM_201_201_Please_Press_to_Start_Route_Reply" 202 "LADSInfoDispReqToICM_202_202_System_control_exit_press_button_to_continute_learning_by_driver" 203 "LADSInfoDispReqToICM_203_203_Finial_slot_not_available_Please_select_other_slot" 204 "LADSInfoDispReqToICM_204_204_Route_learning_Failed" 205 "LADSInfoDispReqToICM_205_205_Route_Reply_Completed" 206 "LADSInfoDispReqToICM_206_206_Route_learning_press_stop_button_to_finsih_learning" 207 "LADSInfoDispReqToICM_207_207_Please_select_route" 208 "LADSInfoDispReqToICM_208_208_Route_learning_will_over_time" 209 "LADSInfoDispReqToICM_209_209_Route_Unavailable" 210 "LADSInfoDispReqToICM_210_210_Not_In_R_gear" 211 "LADSInfoDispReqToICM_211_211_ARA_Ongoing" 212 "LADSInfoDispReqToICM_212_212_ARA_Completed" 213 "LADSInfoDispReqToICM_213_213_Please_press_the_brake_padel_for_vehicle_control_hand_shake" 214 "LADSInfoDispReqToICM_214_214_No_P2P_Route" 215 "LADSInfoDispReqToICM_215_215_System_control_exit_press_button_to_save_route" 216 "LADSInfoDispReqToICM_216_216_System_Loading_please_wait" 217 "LADSInfoDispReqToICM_217_217_No_GPS_system_function_exited" 218 "LADSInfoDispReqToICM_218_218_No_GPSl_please_drive_to_open_area" 219 "LADSInfoDispReqToICM_219_219_Remote_parking_completed_the_destination_is_not_a_storage_location" 220 "LADSInfoDispReqToICM_220_220_Obstacle_avoidance_routes_during_vehicle_control" 221 "LADSInfoDispReqToICM_221_221_Insufficient_environmental_information_not_supporting_P2P" 222 "LADSInfoDispReqToICM_222_222_The_vehicle_passes_through_a_toll_pole_and_does_not_support_route_learning" 223 "LADSInfoDispReqToICM_223_223_Long_time_without_passing_through_the_parking_area_not_supporting_route_learning" 224 "LADSInfoDispReqToICM_224_224_Obstacle_avoidance_risk_is_high_and_requires_user_confirmation" 225 "LADSInfoDispReqToICM_225_225_During_the_matching_process_the_vehicle_leaves_the_geofence" 226 "LADSInfoDispReqToICM_226_226_When_the_steering_wheel_angle_is_too_large_during_the_learning_process" 227 "LADSInfoDispReqToICM_227_227_The_learning_route_is_too_short_to_save" 228 "LADSInfoDispReqToICM_228_228_When_the_P2P_4G_parking_function_is_enabled_the_user_clicks_on_the_relevant_parking_function_on_the_large_screen" 229 "LADSInfoDispReqToICM_229_229_SilentSelect_parking_slot" 230 "LADSInfoDispReqToICM_230_230_Temporary_system_malfunction" 231 "LADSInfoDispReqToICM_231_231_Camera_occlusion_affecting_P2P_functionality" 232 "LADSInfoDispReqToICM_232_232_During_the_playback_process_the_user_intervenes_with_the_actuator_and_the_system_re_plans_the_route_based_on_the_current_position_of_the_vehicle" 233 "LADSInfoDispReqToICM_233_233_During_the_playback_process_the_self_owned_vehicle_intelligently_gives_way_to_other_vehicles" 234 "LADSInfoDispReqToICM_234_234_The_environment_is_too_dark_affecting_perception_accuracy" 235 "LADSInfoDispReqToICM_235_235_Remind_users_at_the_beginning_of_route_learning" 236 "LADSInfoDispReqToICM_236_236_Detect_deceleration_of_vehicles_with_obstacles";
VAL_ 720 ISDWLSRObsRng 0 "SDWLSRObsRng_0_NoObstacle" 1 "SDWLSRObsRng_1_Range1" 2 "SDWLSRObsRng_2_Range2" 3 "SDWLSRObsRng_3_Range3" 4 "SDWLSRObsRng_4_Range4" 5 "SDWLSRObsRng_5_Range5" 6 "SDWLSRObsRng_6_Range6" 7 "SDWLSRObsRng_7_Range7" 8 "SDWLSRObsRng_8_Range8" 9 "SDWLSRObsRng_9_Range9" 10 "SDWLSRObsRng_10_Range10" 11 "SDWLSRObsRng_11_Range11" 12 "SDWLSRObsRng_12_Range12" 13 "SDWLSRObsRng_13_Range13" 14 "SDWLSRObsRng_14_Range14" 15 "SDWLSRObsRng_15_Range15";
VAL_ 720 ISDWLSFObsRng 0 "SDWLSFObsRng_0_NoObstacle" 1 "SDWLSFObsRng_1_Range1" 2 "SDWLSFObsRng_2_Range2" 3 "SDWLSFObsRng_3_Range3" 4 "SDWLSFObsRng_4_Range4" 5 "SDWLSFObsRng_5_Range5" 6 "SDWLSFObsRng_6_Range6" 7 "SDWLSFObsRng_7_Range7" 8 "SDWLSFObsRng_8_Range8" 9 "SDWLSFObsRng_9_Range9" 10 "SDWLSFObsRng_10_Range10" 11 "SDWLSFObsRng_11_Range11" 12 "SDWLSFObsRng_12_Range12" 13 "SDWLSFObsRng_13_Range13" 14 "SDWLSFObsRng_14_Range14" 15 "SDWLSFObsRng_15_Range15";
VAL_ 720 ISDWRSRObsRng 0 "SDWRSRObsRng_0_NoObstacle" 1 "SDWRSRObsRng_1_Range1" 2 "SDWRSRObsRng_2_Range2" 3 "SDWRSRObsRng_3_Range3" 4 "SDWRSRObsRng_4_Range4" 5 "SDWRSRObsRng_5_Range5" 6 "SDWRSRObsRng_6_Range6" 7 "SDWRSRObsRng_7_Range7" 8 "SDWRSRObsRng_8_Range8" 9 "SDWRSRObsRng_9_Range9" 10 "SDWRSRObsRng_10_Range10" 11 "SDWRSRObsRng_11_Range11" 12 "SDWRSRObsRng_12_Range12" 13 "SDWRSRObsRng_13_Range13" 14 "SDWRSRObsRng_14_Range14" 15 "SDWRSRObsRng_15_Range15";
VAL_ 720 ISDWRSFObsRng 0 "SDWRSFObsRng_0_NoObstacle" 1 "SDWRSFObsRng_1_Range1" 2 "SDWRSFObsRng_2_Range2" 3 "SDWRSFObsRng_3_Range3" 4 "SDWRSFObsRng_4_Range4" 5 "SDWRSFObsRng_5_Range5" 6 "SDWRSFObsRng_6_Range6" 7 "SDWRSFObsRng_7_Range7" 8 "SDWRSFObsRng_8_Range8" 9 "SDWRSFObsRng_9_Range9" 10 "SDWRSFObsRng_10_Range10" 11 "SDWRSFObsRng_11_Range11" 12 "SDWRSFObsRng_12_Range12" 13 "SDWRSFObsRng_13_Range13" 14 "SDWRSFObsRng_14_Range14" 15 "SDWRSFObsRng_15_Range15";
VAL_ 733 IKeepPwrRsnIPD 0 "KeepPwrRsnIPD_0_Unknown" 1 "KeepPwrRsnIPD_1_Off" 2 "KeepPwrRsnIPD_2_On" 3 "KeepPwrRsnIPD_3__LPM_SnsrOff" 4 "KeepPwrRsnIPD_4__SnsrOff" 5 "KeepPwrRsnIPD_5_Reserved" 6 "KeepPwrRsnIPD_6_Reserved" 7 "KeepPwrRsnIPD_7_Reserved" 8 "KeepPwrRsnIPD_8_Reserved" 9 "KeepPwrRsnIPD_9_GoingDown" 10 "KeepPwrRsnIPD_10_off_SuperECO" 11 "KeepPwrRsnIPD_11_Reserved" 12 "KeepPwrRsnIPD_12_Reserved" 13 "KeepPwrRsnIPD_13_Reserved" 14 "KeepPwrRsnIPD_14_Reserved" 15 "KeepPwrRsnIPD_15_Reserved";
VAL_ 733 ISysPwrMdCtrl 0 "SysPwrMdCtrl_0_NoRequest" 1 "SysPwrMdCtrl_1_Accessory" 2 "SysPwrMdCtrl_2_Run" 3 "SysPwrMdCtrl_3_Crank_Request" 4 "SysPwrMdCtrl_4_Change_to_normal_mode" 5 "SysPwrMdCtrl_5_Change_to_AD_mode" 6 "SysPwrMdCtrl_6_Off";
VAL_ 1143 ISyncMsgType 32 "SyncMsgType_32_TSync" 40 "SyncMsgType_40_TSync_FUP";
VAL_ 1143 ISyncMsgSGW 0 "SyncMsgSGW_0_SyncToGTM" 1 "SyncMsgSGW_1_SyncToSubDomain";
VAL_ 1526 IIPDComKeyEnbResp 0 "IPDComKeyEnbResp_0_Failed" 1 "IPDComKeyEnbResp_1_Success";
VAL_ 1526 IRemParkngMapChosenresp 0 "RemParkngMapChosenresp_0_default" 1 "RemParkngMapChosenresp_1_positive" 2 "RemParkngMapChosenresp_2_negative";
VAL_ 1526 IAIParkngRespICB 1 "AIParkngRespICB_1_Start_Parking_in" 2 "AIParkngRespICB_2_Start_Parking_out" 3 "AIParkngRespICB_3_Pause" 4 "AIParkngRespICB_4_Continue" 5 "AIParkngRespICB_5_Cancel" 6 "AIParkngRespICB_6_Back_XEquals1" 7 "AIParkngRespICB_7_Left_Parking_out" 8 "AIParkngRespICB_8_Right_Parking_out" 9 "AIParkngRespICB_9_Fast_Parking" 10 "AIParkngRespICB_10_Line_out_System_Start" 11 "AIParkngRespICB_11_Line_back_System_Start" 12 "AIParkngRespICB_12_Call_to_Position_X" 13 "AIParkngRespICB_13_StartParkingScanningManualDriving_XEquals1" 14 "AIParkngRespICB_14_Remote_turn_left_XEquals8" 15 "AIParkngRespICB_15_Remote_turn_right_XEquals8" 16 "AIParkngRespICB_16_RememberBuildMap" 17 "AIParkngRespICB_17_Remember_Park_In" 18 "AIParkngRespICB_18_Remember_Summon" 19 "AIParkngRespICB_19_Start_Remember_Parking" 20 "AIParkngRespICB_20_Keep_Going_Forword" 21 "AIParkngRespICB_21_Keep_Going_Back" 22 "AIParkngRespICB_22_Start_AVP_in" 23 "AIParkngRespICB_23_Start_AVP_out" 24 "AIParkngRespICB_24_Back_Left_Parking_out" 25 "AIParkngRespICB_25_Back_Right_Parking_out" 32 "AIParkngRespICB_32_choose_left_direction_XEquals1" 33 "AIParkngRespICB_33_choose_right_direction_XEquals1" 34 "AIParkngRespICB_34_ReverseParkingInRecordingParking_XEquals1" 35 "AIParkngRespICB_35_MinorAdjEntry_XEquals1" 36 "AIParkngRespICB_36_MinorAdjActive_XEquals1" 37 "AIParkngRespICB_37_ReverseParkingEntry_XEquals1" 38 "MinorAdjActive_Left_XEquals1_2_P11L_M2_P11LX1_S11L_M1_P12L_427PP01_P11L_M3_EP33L_S11L_M2_S12L_M1" 39 "MinorAdjActive_Right_XEquals1_2_P11L_M2_P11LX1_S11L_M1_P12L_427PP01_P11L_M3_EP33_S11L_M2_S12L_M1" 40 "FixMinorAdj_XEquals1_2_P11L_M2_P11LX1_S11L_M1_P12L_427PP01_P11L_M3_EP33L_S11L_M2_S12L_M1" 41 "AIParkngRespICB_41_Trun_around_Left" 42 "AIParkngRespICB_42_RPAIN_Confirming" 45 "AIParkngRespICB_45_NarrowRoadForwardActive" 46 "AIParkngRespICB_46_NarrowRoadForwardEntry" 48 "AIParkngRespICB_48_Trun_around_Right" 49 "AIParkngRespICB_49_Choose_left_turn_round" 50 "AIParkngRespICB_50_Choose_right_turn_round" 51 "AIParkngRespICB_51_choose_right_back_direction" 52 "AIParkngRespICB_52_choose_left_back_direction" 53 "AIParkngRespICB_53_reserved" 54 "AIParkngRespICB_54_reserved" 55 "AIParkngRespICB_55_reserved" 56 "AIParkngRespICB_56_reserved" 57 "AIParkngRespICB_57_reserved" 58 "AIParkngRespICB_58_reserved" 59 "AIParkngRespICB_59_reserved" 60 "AIParkngRespICB_60_reserved" 61 "AIParkngRespICB_61_reserved" 62 "AIParkngRespICB_62_reserved" 63 "AIParkngRespICB_63_reserved" 64 "AIParkngRespICB_64_reserved" 65 "AIParkngRespICB_65_reserved" 66 "AIParkngRespICB_66_reserved" 67 "AIParkngRespICB_67_reserved" 68 "AIParkngRespICB_68_reserved" 69 "AIParkngRespICB_69_reserved" 70 "AIParkngRespICB_70_reserved" 71 "AIParkngRespICB_71_reserved" 72 "AIParkngRespICB_72_reserved" 73 "AIParkngRespICB_73_reserved" 74 "AIParkngRespICB_74_reserved" 75 "AIParkngRespICB_75_reserved" 76 "AIParkngRespICB_76_reserved" 77 "AIParkngRespICB_77_reserved" 78 "AIParkngRespICB_78_reserved" 79 "AIParkngRespICB_79_reserved" 80 "AIParkngRespICB_80_reserved" 81 "AIParkngRespICB_81_reserved" 82 "AIParkngRespICB_82_reserved" 83 "AIParkngRespICB_83_reserved" 84 "AIParkngRespICB_84_reserved" 85 "AIParkngRespICB_85_reserved" 86 "AIParkngRespICB_86_reserved" 87 "AIParkngRespICB_87_reserved" 88 "AIParkngRespICB_88_reserved" 89 "AIParkngRespICB_89_reserved" 90 "AIParkngRespICB_90_reserved" 91 "AIParkngRespICB_91_reserved" 92 "AIParkngRespICB_92_reserved" 93 "AIParkngRespICB_93_reserved" 94 "AIParkngRespICB_94_reserved" 95 "AIParkngRespICB_95_reserved" 96 "AIParkngRespICB_96_reserved" 97 "AIParkngRespICB_97_reserved" 98 "AIParkngRespICB_98_reserved" 99 "AIParkngRespICB_99_reserved" 100 "AIParkngRespICB_100_reserved" 101 "AIParkngRespICB_101_reserved" 102 "AIParkngRespICB_102_reserved" 103 "AIParkngRespICB_103_reserved" 104 "AIParkngRespICB_104_reserved" 105 "AIParkngRespICB_105_reserved" 106 "AIParkngRespICB_106_reserved" 107 "AIParkngRespICB_107_reserved" 108 "AIParkngRespICB_108_reserved" 109 "AIParkngRespICB_109_reserved" 110 "AIParkngRespICB_110_reserved" 111 "AIParkngRespICB_111_reserved" 112 "AIParkngRespICB_112_reserved" 113 "AIParkngRespICB_113_reserved" 114 "AIParkngRespICB_114_reserved" 115 "AIParkngRespICB_115_reserved" 116 "AIParkngRespICB_116_reserved" 117 "AIParkngRespICB_117_reserved" 118 "AIParkngRespICB_118_reserved" 119 "AIParkngRespICB_119_reserved" 120 "AIParkngRespICB_120_reserved" 121 "AIParkngRespICB_121_reserved" 122 "AIParkngRespICB_122_reserved" 123 "AIParkngRespICB_123_reserved" 124 "AIParkngRespICB_124_reserved" 125 "AIParkngRespICB_125_reserved" 126 "AIParkngRespICB_126_reserved" 127 "AIParkngRespICB_127_reserved" 128 "AIParkngRespICB_128_reserved" 129 "AIParkngRespICB_129_reserved" 130 "AIParkngRespICB_130_reserved" 131 "AIParkngRespICB_131_reserved" 132 "AIParkngRespICB_132_reserved" 133 "AIParkngRespICB_133_reserved" 134 "AIParkngRespICB_134_reserved" 135 "AIParkngRespICB_135_reserved" 136 "AIParkngRespICB_136_reserved" 137 "AIParkngRespICB_137_reserved" 138 "AIParkngRespICB_138_reserved" 139 "AIParkngRespICB_139_reserved" 140 "AIParkngRespICB_140_reserved" 141 "AIParkngRespICB_141_reserved" 142 "AIParkngRespICB_142_reserved" 143 "AIParkngRespICB_143_reserved" 144 "AIParkngRespICB_144_reserved" 145 "AIParkngRespICB_145_reserved" 146 "AIParkngRespICB_146_reserved" 147 "AIParkngRespICB_147_reserved" 148 "AIParkngRespICB_148_reserved" 149 "AIParkngRespICB_149_reserved" 150 "AIParkngRespICB_150_reserved" 151 "AIParkngRespICB_151_reserved" 152 "AIParkngRespICB_152_reserved" 153 "AIParkngRespICB_153_reserved" 154 "AIParkngRespICB_154_reserved" 155 "AIParkngRespICB_155_reserved" 156 "AIParkngRespICB_156_reserved" 157 "AIParkngRespICB_157_reserved" 158 "AIParkngRespICB_158_reserved" 159 "AIParkngRespICB_159_reserved" 160 "AIParkngRespICB_160_reserved" 161 "AIParkngRespICB_161_reserved" 162 "AIParkngRespICB_162_reserved" 163 "AIParkngRespICB_163_reserved" 164 "AIParkngRespICB_164_reserved" 165 "AIParkngRespICB_165_reserved" 166 "AIParkngRespICB_166_reserved" 167 "AIParkngRespICB_167_reserved" 168 "AIParkngRespICB_168_reserved" 169 "AIParkngRespICB_169_reserved" 170 "AIParkngRespICB_170_reserved" 171 "AIParkngRespICB_171_reserved" 172 "AIParkngRespICB_172_reserved" 173 "AIParkngRespICB_173_reserved" 174 "AIParkngRespICB_174_reserved" 175 "AIParkngRespICB_175_reserved" 176 "AIParkngRespICB_176_reserved" 177 "AIParkngRespICB_177_reserved" 178 "AIParkngRespICB_178_reserved" 179 "AIParkngRespICB_179_reserved" 180 "AIParkngRespICB_180_reserved" 181 "AIParkngRespICB_181_reserved" 182 "AIParkngRespICB_182_reserved" 183 "AIParkngRespICB_183_reserved" 184 "AIParkngRespICB_184_reserved" 185 "AIParkngRespICB_185_reserved" 186 "AIParkngRespICB_186_reserved" 187 "AIParkngRespICB_187_reserved" 188 "AIParkngRespICB_188_reserved" 189 "AIParkngRespICB_189_reserved" 190 "AIParkngRespICB_190_reserved" 191 "AIParkngRespICB_191_reserved" 192 "AIParkngRespICB_192_reserved" 193 "AIParkngRespICB_193_reserved" 194 "AIParkngRespICB_194_reserved" 195 "AIParkngRespICB_195_reserved" 196 "AIParkngRespICB_196_reserved" 197 "AIParkngRespICB_197_reserved" 198 "AIParkngRespICB_198_reserved" 199 "AIParkngRespICB_199_reserved" 200 "AIParkngRespICB_200_reserved" 201 "AIParkngRespICB_201_reserved" 202 "AIParkngRespICB_202_reserved" 203 "AIParkngRespICB_203_reserved" 204 "AIParkngRespICB_204_reserved" 205 "AIParkngRespICB_205_reserved" 206 "AIParkngRespICB_206_reserved" 207 "AIParkngRespICB_207_reserved" 208 "AIParkngRespICB_208_reserved" 209 "AIParkngRespICB_209_reserved" 210 "AIParkngRespICB_210_reserved" 211 "AIParkngRespICB_211_reserved" 212 "AIParkngRespICB_212_reserved" 213 "AIParkngRespICB_213_reserved" 214 "AIParkngRespICB_214_reserved" 215 "AIParkngRespICB_215_reserved" 216 "AIParkngRespICB_216_reserved" 217 "AIParkngRespICB_217_reserved" 218 "AIParkngRespICB_218_reserved" 219 "AIParkngRespICB_219_reserved" 220 "AIParkngRespICB_220_reserved" 221 "AIParkngRespICB_221_reserved" 222 "AIParkngRespICB_222_reserved" 223 "AIParkngRespICB_223_reserved" 224 "AIParkngRespICB_224_reserved" 225 "AIParkngRespICB_225_reserved" 226 "AIParkngRespICB_226_reserved" 227 "AIParkngRespICB_227_reserved" 228 "AIParkngRespICB_228_reserved" 229 "AIParkngRespICB_229_reserved" 230 "AIParkngRespICB_230_reserved" 231 "AIParkngRespICB_231_reserved" 232 "AIParkngRespICB_232_reserved" 233 "AIParkngRespICB_233_reserved" 234 "AIParkngRespICB_234_reserved" 235 "AIParkngRespICB_235_reserved" 236 "AIParkngRespICB_236_reserved" 237 "AIParkngRespICB_237_reserved" 238 "AIParkngRespICB_238_reserved" 239 "AIParkngRespICB_239_reserved" 240 "AIParkngRespICB_240_reserved" 241 "AIParkngRespICB_241_reserved" 242 "AIParkngRespICB_242_reserved" 243 "AIParkngRespICB_243_reserved" 244 "AIParkngRespICB_244_reserved" 245 "AIParkngRespICB_245_reserved" 246 "AIParkngRespICB_246_reserved" 247 "AIParkngRespICB_247_reserved" 248 "AIParkngRespICB_248_reserved" 249 "AIParkngRespICB_249_reserved" 250 "AIParkngRespICB_250_reserved" 251 "AIParkngRespICB_251_reserved" 252 "AIParkngRespICB_252_reserved" 253 "AIParkngRespICB_253_reserved" 254 "AIParkngRespICB_254_reserved" 255 "AIParkngRespICB_255_reserved";
VAL_ 1202 IIPD_NM_BSMtoRMS_BKPCANFD 0 "IPD_NM_BSMtoRMS_BKPCANFD_0_False" 1 "IPD_NM_BSMtoRMS_BKPCANFD_1_True";
VAL_ 1202 IIPD_NM_PBSMtoRMS_BKPCANFD 0 "IPD_NM_PBSMtoRMS_BKPCANFD_0_False" 1 "IPD_NM_PBSMtoRMS_BKPCANFD_1_True";
VAL_ 1202 IIPD_NM_RMStoNOS_BKPCANFD 0 "IPD_NM_RMStoNOS_BKPCANFD_0_False" 1 "IPD_NM_RMStoNOS_BKPCANFD_1_True";
VAL_ 1202 IIPD_NM_RSStoNOS_BKPCANFD 0 "IPD_NM_RSStoNOS_BKPCANFD_0_False" 1 "IPD_NM_RSStoNOS_BKPCANFD_1_True";
VAL_ 1202 IIPD_NM_RSStoRMS_BKPCANFD 0 "IPD_NM_RSStoRMS_BKPCANFD_0_False" 1 "IPD_NM_RSStoRMS_BKPCANFD_1_True";
VAL_ 1202 IIPD_NM_NOStoRMS_BKPCANFD 0 "IPD_NM_NOStoRMS_BKPCANFD_0_False" 1 "IPD_NM_NOStoRMS_BKPCANFD_1_True";
VAL_ 1202 IIPD_NM_NOSSta_BKPCANFD 0 "IPD_NM_NOSSta_BKPCANFD_0_False" 1 "IPD_NM_NOSSta_BKPCANFD_1_True";
VAL_ 1202 IIPD_NM_RMSSta_BKPCANFD 0 "IPD_NM_RMSSta_BKPCANFD_0_False" 1 "IPD_NM_RMSSta_BKPCANFD_1_True";
VAL_ 1202 IIPD_NWI_BKPCANFD 0 "IPD_NWI_BKPCANFD_0_NoWakeNetworkSource";
VAL_ 1202 IIPD_NOI_BKPCANFD 0 "IPD_NOI_BKPCANFD_0_NoRequest" 65535 "IPD_NOI_BKPCANFD_65535_AllNetworkOperationActive";
VAL_ 1202 IIPD_NKI_BKPCANFD 0 "IPD_NKI_BKPCANFD_0_NoRequest" 1 "IPD_NKI_BKPCANFD_1_PowerModeIsNonOFF";
VAL_ 705 IRASysSts 0 "RASysSts_0_Off" 1 "RASysSts_1_Standby" 2 "RASysSts_2_ForwardActive" 3 "RASysSts_3_Quit" 4 "RASysSts_4_Error" 5 "RASysSts_5_pause" 6 "RASysSts_6_Reserve1" 7 "RASysSts_7_Reserve2";
VAL_ 705 IHWPEMStsForEdr 0 "HWPEMStsForEdr_0_Off" 1 "HWPEMStsForEdr_1_On_but_Not_Intervening" 2 "HWPEMStsForEdr_2_Warning_but_Not_Intervening" 3 "HWPEMStsForEdr_3_Intervening" 4 "HWPEMStsForEdr_4_Faulted" 5 "HWPEMStsForEdr_5_Reserved" 6 "HWPEMStsForEdr_6_Reserved" 7 "HWPEMStsForEdr_7_Non_Function";
VAL_ 705 IHWPEMSts 0 "HWPEMSts_0_Off" 1 "HWPEMSts_1_On_but_Not_Intervening" 2 "HWPEMSts_2_Warning_but_Not_Intervening" 3 "HWPEMSts_3_Intervening" 4 "HWPEMSts_4_Faulted" 5 "HWPEMSts_5_Reserved" 6 "HWPEMSts_6_Reserved" 7 "HWPEMSts_7_Non_Function";
SIG_GROUP_ 368 IICBVC_30ms_Group158 1 : ICCDisAdjtVcCmd ICCDisDecAndIncVcCmd ICCSpdDecAndIncVcCmd ICCSpdVcCmd ICCSpdVcCmdSwReq ICCSwStsCCASwA ICCSwStsSetSwA IICBVC_30ms_Group158_CRC IICBVC_30ms_Group158_RC IICBVC_30ms_Group158_Reserved1 IICBVC_30ms_Group158_Reserved10 IICBVC_30ms_Group158_Reserved11 IICBVC_30ms_Group158_Reserved12 IICBVC_30ms_Group158_Reserved13 IICBVC_30ms_Group158_Reserved2 IICBVC_30ms_Group158_Reserved3 IICBVC_30ms_Group158_Reserved4 IICBVC_30ms_Group158_Reserved5 IICBVC_30ms_Group158_Reserved6 IICBVC_30ms_Group158_Reserved7 IICBVC_30ms_Group158_Reserved8 IICBVC_30ms_Group158_Reserved9;
SIG_GROUP_ 486 IIPD_20ms_Group43 1 : IACCAccReqToqVal IACCSysFltSts_SCS IFrtCarGoNotfr IIPD_20ms_Group43_CRC IIPD_20ms_Group43_RC IIPD_20ms_Group43_Reserved1 IIPD_20ms_Group43_Reserved2 IIPD_20ms_Group43_Reserved3 IIPD_20ms_Group43_Reserved4 IIPD_20ms_Group43_Reserved5;
SIG_GROUP_ 337 IIPD_20ms_Group60 1 : IALCSysFltSts IALCSysSts IAPASCSToqReqVal IAPAVehCrdnatAzmth IAPAVehCrdnatPosX IAPAVehCrdnatPosY IAutoLaneChngLLaneSts IAutoLaneChngRLaneSts IESSDirInd IESSDrvrTkovReq IESSSysFltSts IESSSysSts IIPD_20ms_Group60_CRC IIPD_20ms_Group60_RC IIPD_20ms_Group60_Reserved1 IIPD_20ms_Group60_Reserved10 IIPD_20ms_Group60_Reserved2 IIPD_20ms_Group60_Reserved3 IIPD_20ms_Group60_Reserved4 IIPD_20ms_Group60_Reserved5 IIPD_20ms_Group60_Reserved6 IIPD_20ms_Group60_Reserved7 IIPD_20ms_Group60_Reserved8 IIPD_20ms_Group60_Reserved9 INOPSysFltSts INOPSysSts_ZPD IParkngslottype IPilotTkovMsgReq IPrkgDstCtrlSwResp ISLIFSysFltSts;
SIG_GROUP_ 720 IIPD_50ms_Group14 1 : IIPD_50ms_Group14_CRC IIPD_50ms_Group14_RC IIPD_50ms_Group14_Reserved1 IIPD_50ms_Group14_Reserved10 IIPD_50ms_Group14_Reserved11 IIPD_50ms_Group14_Reserved2 IIPD_50ms_Group14_Reserved3 IIPD_50ms_Group14_Reserved4 IIPD_50ms_Group14_Reserved5 IIPD_50ms_Group14_Reserved6 IIPD_50ms_Group14_Reserved7 IIPD_50ms_Group14_Reserved8 IIPD_50ms_Group14_Reserved9 ILADSInfoDispReq ILADSInfoDispReqToICM ILADSProgressBar ISDWLSFObsRng ISDWLSRObsRng ISDWRSFObsRng ISDWRSRObsRng;
SIG_GROUP_ 733 IIPD_50ms_Group49 1 : IIPD_50ms_Group49_CRC IIPD_50ms_Group49_RC IIPD_50ms_Group49_Reserved1 IIPD_50ms_Group49_Reserved2 IIPD_50ms_Group49_Reserved3 IIPD_50ms_Group49_Reserved4 IIPD_50ms_Group49_Reserved5 IIPD_50ms_Group49_Reserved6 IKeepPwrRsnIPD ISysPwrMdCtrl;
SIG_GROUP_ 1143 IIPD_Sporadic_TimeSync_Group 1 : ISyncMsgCheckSum ISyncMsgOVS ISyncMsgSGW ISyncMsgSequenceCounter ISyncMsgTime ISyncMsgTimeDomain ISyncMsgType ISyncMsgreserved;
